VERSION ""

NS_ :

BS_:

BU_: VDCU_V CDCU VDR_TBOX ADCU VIU_B VIU_C VDCU_M EPB EPS_M EPS_S EBS FCS CMS_R CMS_B ECAS EGSM MTCU

BO_ 2566889511 NM_VDCU: 8 VDCU_V
 SG_ VDCU_SourceNodeID : 0|8@1+ (1,0) [0|255] "" Vector__XXX
 SG_ VDCU_ActiveWakeUpBit : 12|1@1+ (1,0) [0|1] "" Vector__XXX
 SG_ VDCU_RepeatMessageRequest : 8|1@1+ (1,0) [0|1] "" Vector__XXX
 SG_ VDCU_NMState_RMSfromBSM : 16|1@1+ (1,0) [0|1] "" Vector__XXX
 SG_ VDCU_NMState_RMSfromPBSM : 17|1@1+ (1,0) [0|1] "" Vector__XXX
 SG_ VDCU_NMState_RMSfromNOS : 18|1@1+ (1,0) [0|1] "" Vector__XXX
 SG_ VDCU_NMState_RMSfromRSS : 19|1@1+ (1,0) [0|1] "" Vector__XXX
 SG_ VDCU_NMState_NOSfromRMS : 20|1@1+ (1,0) [0|1] "" Vector__XXX
 SG_ VDCU_NMState_NOSfromRSS : 21|1@1+ (1,0) [0|1] "" Vector__XXX
 SG_ VDCU_WakeupSource : 24|8@1+ (1,0) [0|255] "" Vector__XXX
 SG_ VDCU_NMKpARson_NMPduReceived : 32|1@1+ (1,0) [0|1] "" Vector__XXX
 SG_ VDCU_NMKpARson_TimeOut : 33|1@1+ (1,0) [0|1] "" Vector__XXX
 SG_ VDCU_NMKpARson_Diag : 34|1@1+ (1,0) [0|1] "" Vector__XXX
 SG_ VDCU_NMKpARson_KL15 : 36|1@1+ (1,0) [0|1] "" Vector__XXX
 SG_ VDCU_NMKpARson_LINReq : 37|1@1+ (1,0) [0|1] "" Vector__XXX
 SG_ VDCU_NMKpARson_WinCtrl_L : 38|1@1+ (1,0) [0|1] "" Vector__XXX
 SG_ VDCU_NMKpARson_WinCtrl_R : 39|1@1+ (1,0) [0|1] "" Vector__XXX
 SG_ VDCU_NMKpARson_BrakePedalPressed : 40|1@1+ (1,0) [0|1] "" Vector__XXX
 SG_ VDCU_NMKpARson_LowBeamReq : 41|1@1+ (1,0) [0|1] "" Vector__XXX
 SG_ VDCU_NMKpARson_PosnLigjtReq : 42|1@1+ (1,0) [0|1] "" Vector__XXX
 SG_ VDCU_NMKpARson_DCChargeActive : 43|1@1+ (1,0) [0|1] "" Vector__XXX
 SG_ VDCU_NMKpARson_PowerOFFdelayMonitor : 44|1@1+ (1,0) [0|1] "" Vector__XXX
 SG_ VDCU_NMKpARson_ACChargeActive : 45|1@1+ (1,0) [0|1] "" Vector__XXX
 SG_ VDCU_NMKpARson_HVConnected : 46|1@1+ (1,0) [0|1] "" Vector__XXX
 SG_ VDCU_NMKpARson_ChargeWarmer : 47|1@1+ (1,0) [0|1] "" Vector__XXX
 SG_ VDCU_NMKpARson_Ready : 48|1@1+ (1,0) [0|1] "" Vector__XXX
 SG_ VDCU_NMKpARson_SmartCharge : 49|1@1+ (1,0) [0|1] "" Vector__XXX

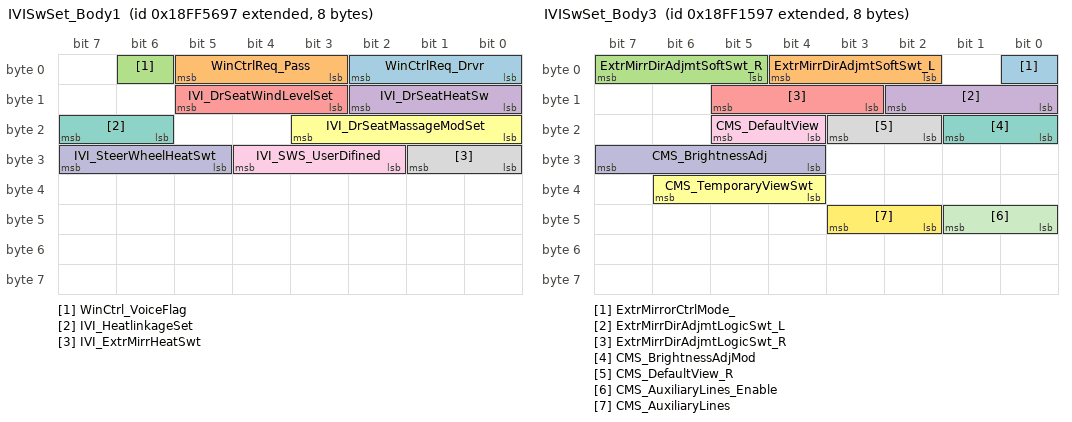
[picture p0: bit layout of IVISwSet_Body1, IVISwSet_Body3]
BO_ 2566870679 IVISwSet_Body1: 8 CDCU
 SG_ WinCtrlReq_Drvr : 0|3@1+ (1,0) [0|7] "" VDCU_V
 SG_ WinCtrlReq_Pass : 3|3@1+ (1,0) [0|7] "" VDCU_V
 SG_ WinCtrl_VoiceFlag : 6|1@1+ (1,0) [0|1] "" VDCU_V
 SG_ IVI_DrSeatHeatSw : 8|3@1+ (1,0) [0|7] "" VDCU_V
 SG_ IVI_DrSeatWindLevelSet : 11|3@1+ (1,0) [0|7] "" VDCU_V
 SG_ IVI_DrSeatMassageModSet : 16|4@1+ (1,0) [0|15] "" VDCU_V
 SG_ IVI_HeatlinkageSet : 22|2@1+ (1,0) [0|3] "" VDCU_V
 SG_ IVI_ExtrMirrHeatSwt : 24|2@1+ (1,0) [0|3] "" VDCU_V
 SG_ IVI_SWS_UserDifined : 26|3@1+ (1,0) [0|7] "" VDCU_V
 SG_ IVI_SteerWheelHeatSwt : 29|3@1+ (1,0) [0|7] "" VDCU_V

BO_ 2566900119 IVISwSet_Body2: 8 CDCU
 SG_ IVI_HornShiftSwitch : 0|2@1+ (1,0) [0|3] "" VDCU_V
 SG_ IVI_VehLockRemindSet : 2|2@1+ (1,0) [0|3] "" VDCU_V
 SG_ IVI_LampFollowMeHomeSet : 4|3@1+ (1,0) [0|7] "" VDCU_V
 SG_ IVI_LampAwayHomeSet : 8|3@1+ (1,0) [0|7] "" VDCU_V
 SG_ IVI_FindMyCarSet : 11|2@1+ (1,0) [0|3] "" VDCU_V
 SG_ IVI_SmartWelcomeSet : 13|2@1+ (1,0) [0|3] "" VDCU_V
 SG_ IVI_LogoLightSwitch : 16|2@1+ (1,0) [0|3] "" VDCU_V
 SG_ IVI_ADBSwitch : 18|2@1+ (1,0) [0|3] "" VDCU_V
 SG_ IVI_RainAutoCloseWinSet : 20|2@1+ (1,0) [0|3] "" VDCU_V
 SG_ IVI_LockAutoCloseWinSet : 22|2@1+ (1,0) [0|3] "" VDCU_V
 SG_ IVI_UnlockSet : 24|2@1+ (1,0) [0|3] "" VDCU_V
 SG_ IVI_SpeedAutoLockSet : 26|2@1+ (1,0) [0|3] "" VDCU_V
 SG_ IVI_StopAutoUnlockSet : 28|2@1+ (1,0) [0|3] "" VDCU_V
 SG_ IVI_ApproachAutoUnlockSet : 30|2@1+ (1,0) [0|3] "" VDCU_V
 SG_ IVI_AwayAutoLockSet : 32|2@1+ (1,0) [0|3] "" VDCU_V
 SG_ IVI_SpeedLimitSet_Sleeper : 34|2@1+ (1,0) [0|3] "" VDCU_V
 SG_ IVI_WCMEnableSwitch : 44|2@1+ (1,0) [0|3] "" VDCU_V
 SG_ IVI_BackLightBriSet : 48|4@1+ (1,0) [0|15] "" VDCU_V
 SG_ CeilingLightSet : 52|2@1+ (1,0) [0|3] "" VDCU_V
 SG_ IVI_VSPOpenSet : 56|2@1+ (1,0) [0|3] "" VDCU_V

BO_ 2566854039 IVISwSet_Body3: 8 CDCU
 SG_ ExtrMirrorCtrlMode_ : 0|1@1+ (1,0) [0|1] "" VDCU_V
 SG_ ExtrMirrDirAdjmtSoftSwt_L : 2|3@1+ (1,0) [0|7] "" VDCU_V
 SG_ ExtrMirrDirAdjmtSoftSwt_R : 5|3@1+ (1,0) [0|7] "" VDCU_V
 SG_ ExtrMirrDirAdjmtLogicSwt_L : 8|3@1+ (1,0) [0|7] "" VDCU_V
 SG_ ExtrMirrDirAdjmtLogicSwt_R : 11|3@1+ (1,0) [0|7] "" VDCU_V
 SG_ CMS_TemporaryViewSwt : 36|3@1+ (1,0) [0|7] "" VDCU_V
 SG_ CMS_BrightnessAdjMod : 16|2@1+ (1,0) [0|3] "" VDCU_V
 SG_ CMS_DefaultView_R : 18|2@1+ (1,0) [0|3] "" VDCU_V
 SG_ CMS_DefaultView : 20|2@1+ (1,0) [0|3] "" VDCU_V
 SG_ CMS_BrightnessAdj : 28|4@1+ (1,0) [0|15] "" VDCU_V
 SG_ CMS_AuxiliaryLines_Enable : 40|2@1+ (1,0) [0|3] "" VDCU_V
 SG_ CMS_AuxiliaryLines : 42|2@1+ (1,0) [0|3] "" VDCU_V

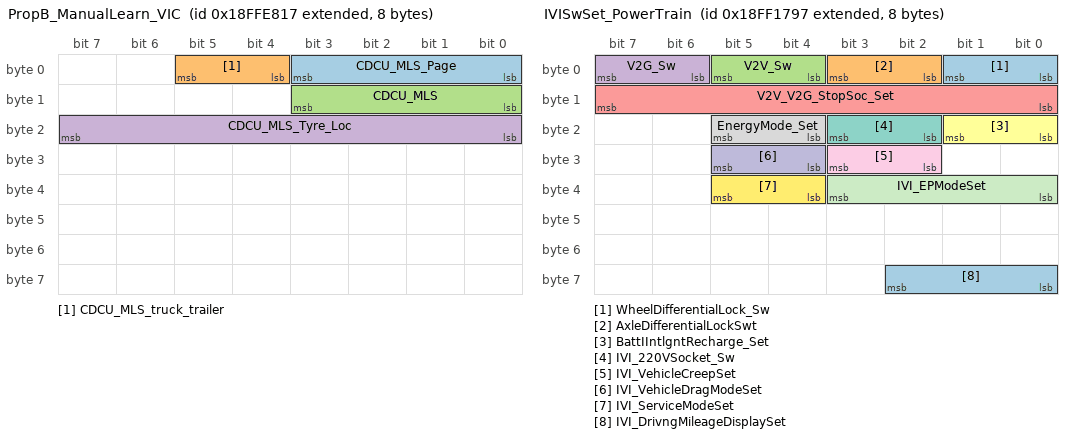
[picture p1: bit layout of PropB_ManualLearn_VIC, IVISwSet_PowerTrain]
BO_ 2566907927 PropB_ManualLearn_VIC: 8 CDCU
 SG_ CDCU_MLS_Page : 0|4@1+ (1,0) [0|15] "" VDCU_V
 SG_ CDCU_MLS_truck_trailer : 4|2@1+ (1,0) [0|3] "" VDCU_V
 SG_ CDCU_MLS : 8|4@1+ (1,0) [0|15] "" VDCU_V
 SG_ CDCU_MLS_Tyre_Loc : 16|8@1+ (1,0) [0|255] "" VDCU_V

BO_ 2566723351 IC_BDS: 8 CDCU
 SG_ DriverBeltlockStatus : 0|2@1+ (1,0) [0|3] "" VDCU_V
 SG_ PassengerBeltlockStatus : 2|2@1+ (1,0) [0|3] "" VDCU_V

BO_ 2566850171 DMS1: 8 CDCU
 SG_ DMS_SeatShakeSts : 32|3@1+ (1,0) [0|7] "" VDCU_V

BO_ 2563833751 Illumintion: 8 CDCU
 SG_ IlluminationBrightnessPercent : 0|8@1+ (0.4,0) [0|100] "%" VDCU_V

BO_ 2566905239 IVISwReq_TM1: 8 CDCU
 SG_ IVI_ACOffSwt : 0|2@1+ (1,0) [0|3] "" VDCU_V
 SG_ IVI_ACAutoSwt : 2|2@1+ (1,0) [0|3] "" VDCU_V
 SG_ IVI_ACModeMotorSwt : 4|3@1+ (1,0) [0|7] "" VDCU_V
 SG_ IVI_ACACSwt : 8|2@1+ (1,0) [0|3] "" VDCU_V
 SG_ IVI_ACPTCSwt : 10|2@1+ (1,0) [0|3] "" VDCU_V
 SG_ IVI_ACCycleMotorSwt : 12|2@1+ (1,0) [0|3] "" VDCU_V
 SG_ IVI_ACFrontDefrostSwt : 14|2@1+ (1,0) [0|3] "" VDCU_V
 SG_ IVI_ACTempPlusSwt : 16|1@1+ (1,0) [0|1] "" VDCU_V
 SG_ IVI_ACTempMinusSwt : 17|1@1+ (1,0) [0|1] "" VDCU_V
 SG_ IVI_ACTempLevelSwt : 18|6@1+ (1,0) [0|63] "" VDCU_V
 SG_ IVI_ACBlowerLvlSeltSwt : 24|4@1+ (1,0) [0|15] "" VDCU_V
 SG_ IVI_LonizerSwt : 28|2@1+ (1,0) [0|3] "" VDCU_V
 SG_ IVI_AirPurgeSwt : 30|2@1+ (1,0) [0|3] "" VDCU_V
 SG_ IVI_AcMaxSwt : 32|2@1+ (1,0) [0|3] "" VDCU_V
 SG_ IVI_HeatingMaxSwt : 34|2@1+ (1,0) [0|3] "" VDCU_V
 SG_ IVI_TempZoneSyncSwt : 36|2@1+ (1,0) [0|3] "" VDCU_V
 SG_ IVI_ACBlowerLvlSeltSwt_Slpr : 40|4@1+ (1,0) [0|15] "" VDCU_V
 SG_ IVI_ACTempPlusSwt_Slpr : 48|1@1+ (1,0) [0|1] "" VDCU_V
 SG_ IVI_ACTempMinusSwt_Slpr : 49|1@1+ (1,0) [0|1] "" VDCU_V
 SG_ IVI_ACTempLevelSwt_Slpr : 50|6@1+ (1,0) [0|63] "" VDCU_V
 SG_ IVI_ACBlowerPlusSwt_Slpr : 56|1@1+ (1,0) [0|1] "" VDCU_V
 SG_ IVI_ACBlowerMinusSwt_Slpr : 57|1@1+ (1,0) [0|1] "" VDCU_V
 SG_ IVI_ACBlowerLvlMinusSwt : 58|1@1+ (1,0) [0|1] "" VDCU_V
 SG_ IVI_ACOffSwt_Slpr : 59|2@1+ (1,0) [0|3] "" VDCU_V
 SG_ IVI_ACTimingRunSwt_Slpr : 61|2@1+ (1,0) [0|3] "" VDCU_V

BO_ 2566854551 IVISwSet_PowerTrain: 8 CDCU
 SG_ WheelDifferentialLock_Sw : 0|2@1+ (1,0) [0|3] "" VDCU_V
 SG_ AxleDifferentialLockSwt : 2|2@1+ (1,0) [0|3] "" VDCU_V
 SG_ V2V_Sw : 4|2@1+ (1,0) [0|3] "" VDCU_V
 SG_ V2G_Sw : 6|2@1+ (1,0) [0|3] "" VDCU_V
 SG_ V2V_V2G_StopSoc_Set : 8|8@1+ (1,0) [20|100] "%" VDCU_V
 SG_ BattIIntlgntRecharge_Set : 16|2@1+ (1,0) [0|3] "" VDCU_V
 SG_ IVI_220VSocket_Sw : 18|2@1+ (1,0) [0|3] "" VDCU_V
 SG_ EnergyMode_Set : 20|2@1+ (1,0) [0|3] "" VDCU_V
 SG_ IVI_VehicleCreepSet : 26|2@1+ (1,0) [0|3] "" VDCU_V
 SG_ IVI_VehicleDragModeSet : 28|2@1+ (1,0) [0|3] "" VDCU_V
 SG_ IVI_EPModeSet : 32|4@1+ (1,0) [0|15] "" VDCU_V
 SG_ IVI_ServiceModeSet : 36|2@1+ (1,0) [0|3] "" VDCU_V
 SG_ IVI_DrivngMileageDisplaySet : 56|3@1+ (1,0) [0|7] "" VDCU_V

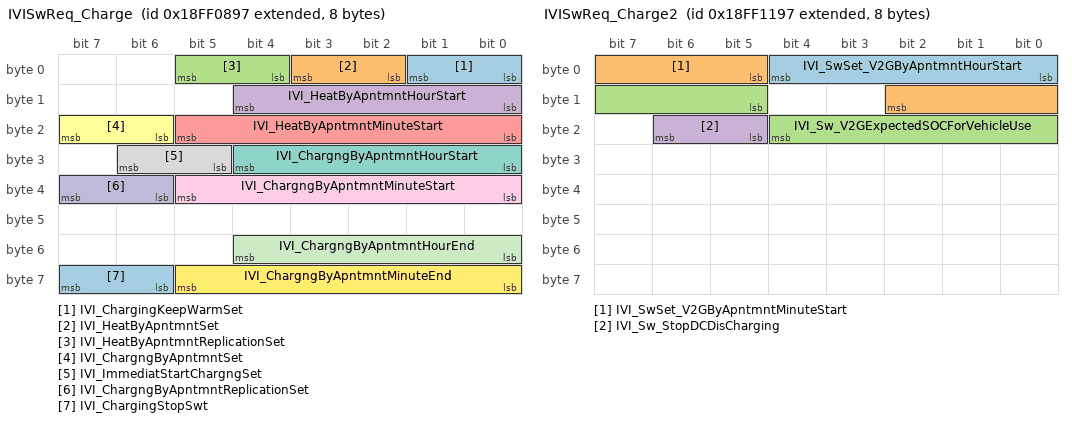
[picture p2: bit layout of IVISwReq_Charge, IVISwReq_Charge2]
BO_ 2566850711 IVISwReq_Charge: 8 CDCU
 SG_ IVI_ChargingKeepWarmSet : 0|2@1+ (1,0) [0|3] "" VDCU_V
 SG_ IVI_HeatByApntmntSet : 2|2@1+ (1,0) [0|3] "" VDCU_V
 SG_ IVI_HeatByApntmntReplicationSet : 4|2@1+ (1,0) [0|1] "" VDCU_V
 SG_ IVI_HeatByApntmntHourStart : 8|5@1+ (1,0) [0|31] "" VDCU_V
 SG_ IVI_HeatByApntmntMinuteStart : 16|6@1+ (1,0) [0|31] "" VDCU_V
 SG_ IVI_ChargngByApntmntSet : 22|2@1+ (1,0) [0|3] "" VDCU_V
 SG_ IVI_ChargngByApntmntHourStart : 24|5@1+ (1,0) [0|31] "h" VDCU_V
 SG_ IVI_ImmediatStartChargngSet : 29|2@1+ (1,0) [0|3] "" VDCU_V
 SG_ IVI_ChargngByApntmntMinuteStart : 32|6@1+ (1,0) [0|31] "min" VDCU_V
 SG_ IVI_ChargngByApntmntReplicationSet : 38|2@1+ (1,0) [0|1] "" VDCU_V
 SG_ IVI_ChargngByApntmntHourEnd : 48|5@1+ (1,0) [0|31] "h" VDCU_V
 SG_ IVI_ChargngByApntmntMinuteEnd : 56|6@1+ (1,0) [0|63] "min" VDCU_V
 SG_ IVI_ChargingStopSwt : 62|2@1+ (1,0) [0|3] "" VDCU_V

BO_ 2566853015 IVISwReq_Charge2: 8 CDCU
 SG_ IVI_SwSet_V2GByApntmntHourStart : 0|5@1+ (1,0) [0|31] "h" VDCU_V
 SG_ IVI_SwSet_V2GByApntmntMinuteStart : 5|6@1+ (1,0) [0|63] "min" VDCU_V
 SG_ IVI_Sw_V2GExpectedSOCForVehicleUse : 13|8@1+ (1,0) [0|100] "%" VDCU_V
 SG_ IVI_Sw_StopDCDisCharging : 21|2@1+ (1,0) [0|3] "" VDCU_V

BO_ 2566865177 TM_ACCtrl: 8 VDCU_V
 SG_ ACTempLevelDisp : 0|6@1+ (1,0) [0|63] "" CDCU,VDR_TBOX,ADCU
 SG_ ACPTCDisp : 6|2@1+ (1,0) [0|3] "" Vector__XXX
 SG_ ACTempLevelCtrl : 8|6@1+ (1,0) [0|63] "" VIU_B,ADCU
 SG_ ACModeMotorDisp : 16|3@1+ (1,0) [0|7] "" CDCU,VDR_TBOX,ADCU
 SG_ ACModeMotorCtrl : 19|3@1+ (1,0) [0|7] "" VIU_B,ADCU
 SG_ ACCycleMotorDisp : 22|2@1+ (1,0) [0|3] "" CDCU,VDR_TBOX,ADCU
 SG_ ACCycleMotorPosnCtrl : 24|2@1+ (1,0) [0|3] "" VIU_B,ADCU
 SG_ ACBlowerLevelDisp : 26|4@1+ (1,0) [0|15] "" CDCU,VDR_TBOX,ADCU
 SG_ ACBlowerLevelCtrl : 32|4@1+ (1,0) [0|15] "" VIU_B,ADCU
 SG_ ACFrontDefrostDisp : 36|2@1+ (1,0) [0|3] "" CDCU,VDR_TBOX,ADCU
 SG_ ACAcDisp : 38|2@1+ (1,0) [0|3] "" CDCU,VDR_TBOX,ADCU
 SG_ ACMaxDisp : 40|2@1+ (1,0) [0|3] "" CDCU,VDR_TBOX,ADCU
 SG_ ACAutoDisp : 42|2@1+ (1,0) [0|3] "" CDCU,VDR_TBOX,ADCU
 SG_ ACOffDisp : 44|2@1+ (1,0) [0|3] "" CDCU,VDR_TBOX,ADCU
 SG_ ACAirPurgeDisp : 46|2@1+ (1,0) [0|3] "" CDCU,VDR_TBOX,ADCU
 SG_ ACAirPurgeCtrl : 48|2@1+ (1,0) [0|3] "" VIU_B,ADCU
 SG_ ACLonizerDisp : 50|2@1+ (1,0) [0|3] "" CDCU,VDR_TBOX,ADCU
 SG_ ACLonizerCtrl : 52|2@1+ (1,0) [0|3] "" VIU_B,ADCU
 SG_ AC_TempZoneSyncSts : 54|2@1+ (1,0) [0|3] "" VIU_B,CDCU,VDR_TBOX,ADCU
 SG_ AC_HeatingMaxSts : 56|2@1+ (1,0) [0|3] "" VIU_B,CDCU,VDR_TBOX,ADCU
 SG_ ElecACTempLevelDisp : 58|5@1+ (1,0) [0|31] "" Vector__XXX

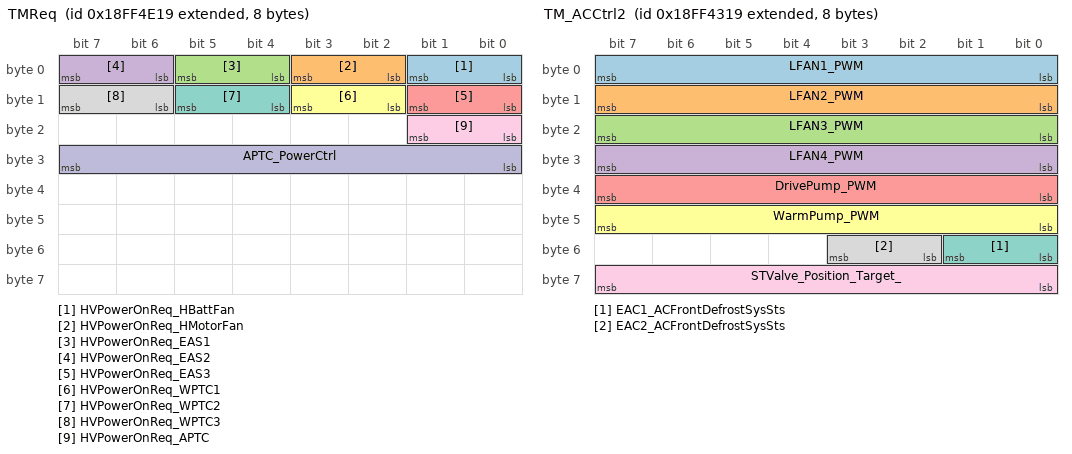
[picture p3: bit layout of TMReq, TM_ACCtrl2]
BO_ 2566868505 TMReq: 8 VDCU_V
 SG_ HVPowerOnReq_HBattFan : 0|2@1+ (1,0) [0|3] "" Vector__XXX
 SG_ HVPowerOnReq_HMotorFan : 2|2@1+ (1,0) [0|3] "" Vector__XXX
 SG_ HVPowerOnReq_EAS1 : 4|2@1+ (1,0) [0|3] "" Vector__XXX
 SG_ HVPowerOnReq_EAS2 : 6|2@1+ (1,0) [0|3] "" Vector__XXX
 SG_ HVPowerOnReq_EAS3 : 8|2@1+ (1,0) [0|3] "" Vector__XXX
 SG_ HVPowerOnReq_WPTC1 : 10|2@1+ (1,0) [0|3] "" Vector__XXX
 SG_ HVPowerOnReq_WPTC2 : 12|2@1+ (1,0) [0|3] "" Vector__XXX
 SG_ HVPowerOnReq_WPTC3 : 14|2@1+ (1,0) [0|3] "" Vector__XXX
 SG_ HVPowerOnReq_APTC : 16|2@1+ (1,0) [0|3] "" Vector__XXX
 SG_ APTC_PowerCtrl : 24|8@1+ (100,0) [0|4700] "W" VIU_B

BO_ 2566865433 TM_ACCtrl1: 8 VDCU_V
 SG_ ACTempLevelDispSlpr : 2|6@1+ (1,0) [0|63] "" CDCU
 SG_ ACTempLevelCtrl_Slpr : 10|6@1+ (1,0) [0|63] "" VIU_B
 SG_ ACBlowerLevelDisp_Slpr : 16|4@1+ (1,0) [0|15] "" CDCU
 SG_ ACBlowerLevelCtrl_Slpr : 20|4@1+ (1,0) [0|15] "" VIU_B
 SG_ ACTimingRunDisp_Slpr : 24|2@1+ (1,0) [0|3] "" CDCU
 SG_ ACOffDisp_Slpr : 26|2@1+ (1,0) [0|3] "" CDCU
 SG_ ESC_PTC_LowRelayCtrl : 28|2@1+ (1,0) [0|3] "" VIU_B
 SG_ FAN_LowRelayCtrl : 30|2@1+ (1,0) [0|3] "" VIU_C
 SG_ Blower_RelayCtrl : 32|2@1+ (1,0) [0|3] "" VIU_B
 SG_ Blower_RelayCtrl_Slpr : 34|2@1+ (1,0) [0|3] "" VIU_B
 SG_ BattPump_RelayCtrl : 36|2@1+ (1,0) [0|3] "" VIU_B
 SG_ WarmPump_RelayCtrl : 38|2@1+ (1,0) [0|3] "" VIU_B
 SG_ DrivePump_RelayCtrl : 40|2@1+ (1,0) [0|3] "" VIU_C
 SG_ SOVFront_Ctrl : 42|1@1+ (1,0) [0|1] "" VIU_B
 SG_ SOVRear_Ctrl : 43|1@1+ (1,0) [0|1] "" VIU_B
 SG_ Wasteheat_use_2way_SOV : 46|2@1+ (1,0) [0|3] "" VIU_C
 SG_ BattPump_PWM : 48|8@1+ (0.4,0) [0|100] "%" VIU_B,VIU_C
 SG_ Temp_Ambt_Accurate : 56|8@1+ (0.5,-40) [-40|87] "℃" Vector__XXX

BO_ 2566865689 TM_ACCtrl2: 8 VDCU_V
 SG_ LFAN1_PWM : 0|8@1+ (0.4,0) [0|100] "%" VIU_B,VIU_C
 SG_ LFAN2_PWM : 8|8@1+ (0.4,0) [0|100] "%" VIU_B,VIU_C
 SG_ LFAN3_PWM : 16|8@1+ (0.4,0) [0|100] "%" VIU_B,VIU_C
 SG_ LFAN4_PWM : 24|8@1+ (0.4,0) [0|100] "%" VIU_B,VIU_C
 SG_ DrivePump_PWM : 32|8@1+ (0.4,0) [0|100] "%" VIU_B,VIU_C
 SG_ WarmPump_PWM : 40|8@1+ (0.4,0) [0|100] "%" VIU_C
 SG_ EAC1_ACFrontDefrostSysSts : 48|2@1+ (1,0) [0|3] "" CDCU
 SG_ EAC2_ACFrontDefrostSysSts : 50|2@1+ (1,0) [0|3] "" CDCU
 SG_ STValve_Position_Target_ : 56|8@1+ (0.01953,0) [0|5] "v" VIU_C

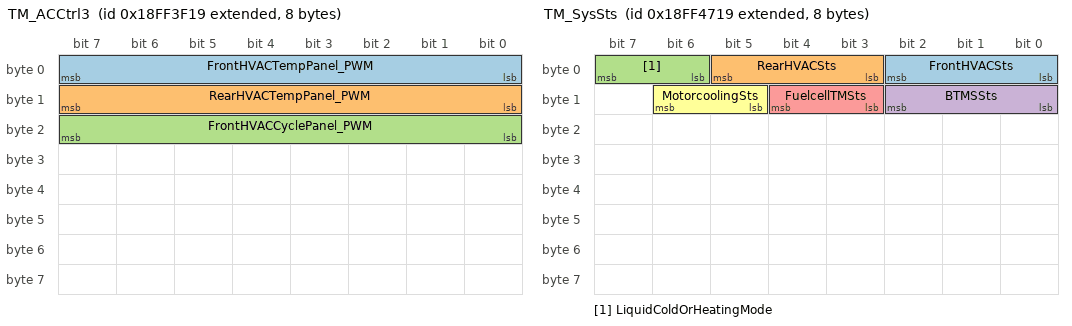
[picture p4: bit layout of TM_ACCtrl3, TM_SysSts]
BO_ 2566864665 TM_ACCtrl3: 8 VDCU_V
 SG_ FrontHVACTempPanel_PWM : 0|8@1+ (0.4,0) [0|100] "%" VIU_B
 SG_ RearHVACTempPanel_PWM : 8|8@1+ (0.4,0) [0|100] "%" VIU_B
 SG_ FrontHVACCyclePanel_PWM : 16|8@1+ (0.4,0) [0|100] "%" VIU_B

BO_ 2566866713 TM_SysSts: 8 VDCU_V
 SG_ FrontHVACSts : 0|3@1+ (1,0) [0|7] "" Vector__XXX
 SG_ RearHVACSts : 3|3@1+ (1,0) [0|6] "" Vector__XXX
 SG_ LiquidColdOrHeatingMode : 6|2@1+ (1,0) [0|3] "" Vector__XXX
 SG_ BTMSSts : 8|3@1+ (1,0) [0|7] "" Vector__XXX
 SG_ FuelcellTMSts : 11|2@1+ (1,0) [0|3] "" Vector__XXX
 SG_ MotorcoolingSts : 13|2@1+ (1,0) [0|3] "" Vector__XXX

BO_ 2566907722 EncryptData_TBox: 16 VDR_TBOX
 SG_ T_boxEncryptData_Byte1 : 0|8@1+ (1,0) [0|255] "" VDCU_V
 SG_ T_boxEncryptData_Byte2 : 8|8@1+ (1,0) [0|255] "" VDCU_V
 SG_ T_boxEncryptData_Byte3 : 16|8@1+ (1,0) [0|255] "" VDCU_V
 SG_ T_boxEncryptData_Byte4 : 24|8@1+ (1,0) [0|255] "" VDCU_V
 SG_ T_boxEncryptData_Byte5 : 32|8@1+ (1,0) [0|255] "" VDCU_V
 SG_ T_boxEncryptData_Byte6 : 40|8@1+ (1,0) [0|255] "" VDCU_V
 SG_ T_boxEncryptData_Byte7 : 48|8@1+ (1,0) [0|255] "" VDCU_V
 SG_ T_boxEncryptData_Byte8 : 56|8@1+ (1,0) [0|255] "" VDCU_V
 SG_ T_boxEncryptData_Byte9 : 64|8@1+ (1,0) [0|255] "" VDCU_V
 SG_ T_boxEncryptData_Byte10 : 72|8@1+ (1,0) [0|255] "" VDCU_V
 SG_ T_boxEncryptData_Byte11 : 80|8@1+ (1,0) [0|255] "" VDCU_V
 SG_ T_boxEncryptData_Byte12 : 88|8@1+ (1,0) [0|255] "" VDCU_V
 SG_ T_boxEncryptData_Byte13 : 96|8@1+ (1,0) [0|255] "" VDCU_V
 SG_ T_boxEncryptData_Byte14 : 104|8@1+ (1,0) [0|255] "" VDCU_V
 SG_ T_boxEncryptData_Byte15 : 112|8@1+ (1,0) [0|255] "" VDCU_V
 SG_ T_boxEncryptData_Byte16 : 120|8@1+ (1,0) [0|255] "" VDCU_V

BO_ 2566908234 VehicleID_TBox: 8 VDR_TBOX
 SG_ VehicleID_Tbox : 0|48@1+ (1,0) [0|2.81474976710655E14] "" VDCU_V

BO_ 2566908490 SecretKey_TBox: 16 VDR_TBOX
 SG_ SecretKey_Tbox_Byte1 : 0|8@1+ (1,0) [0|255] "" VDCU_V
 SG_ SecretKey_Tbox_Byte2 : 8|8@1+ (1,0) [0|255] "" VDCU_V
 SG_ SecretKey_Tbox_Byte3 : 16|8@1+ (1,0) [0|255] "" VDCU_V
 SG_ SecretKey_Tbox_Byte4 : 24|8@1+ (1,0) [0|255] "" VDCU_V
 SG_ SecretKey_Tbox_Byte5 : 32|8@1+ (1,0) [0|255] "" VDCU_V
 SG_ SecretKey_Tbox_Byte6 : 40|8@1+ (1,0) [0|255] "" VDCU_V
 SG_ SecretKey_Tbox_Byte7 : 48|8@1+ (1,0) [0|255] "" VDCU_V
 SG_ SecretKey_Tbox_Byte8 : 56|8@1+ (1,0) [0|255] "" VDCU_V
 SG_ SecretKey_Tbox_Byte9 : 64|8@1+ (1,0) [0|255] "" VDCU_V
 SG_ SecretKey_Tbox_Byte10 : 72|8@1+ (1,0) [0|255] "" VDCU_V
 SG_ SecretKey_Tbox_Byte11 : 80|8@1+ (1,0) [0|255] "" VDCU_V
 SG_ SecretKey_Tbox_Byte12 : 88|8@1+ (1,0) [0|255] "" VDCU_V
 SG_ SecretKey_Tbox_Byte13 : 96|8@1+ (1,0) [0|255] "" VDCU_V
 SG_ SecretKey_Tbox_Byte14 : 104|8@1+ (1,0) [0|255] "" VDCU_V
 SG_ SecretKey_Tbox_Byte15 : 112|8@1+ (1,0) [0|255] "" VDCU_V
 SG_ SecretKey_Tbox_Byte16 : 120|8@1+ (1,0) [0|255] "" VDCU_V

BO_ 2565537610 RQST_TBox: 3 VDR_TBOX
 SG_ Tbox_RQST_PGN : 0|24@1+ (1,0) [0|1.6777215E7] "" VDCU_V

BO_ 2566907210 TBox_Request: 16 VDR_TBOX
 SG_ ControlIdentifier : 0|8@1+ (1,0) [0|255] "" VDCU_V
 SG_ AwakeNetwork : 8|2@1+ (1,0) [0|3] "" VDCU_V
 SG_ TBOX_ACTempLevelReq_TM1 : 16|6@1+ (1,0) [0|63] "" VDCU_V
 SG_ TBOX_ACFrontDefrostReq_TM1 : 22|2@1+ (1,0) [0|3] "" VDCU_V
 SG_ TBOX_Cockpit_Cleaning_TM1 : 24|2@1+ (1,0) [0|3] "" VDCU_V
 SG_ TBOX_AcMaxSwt : 32|2@1+ (1,0) [0|3] "" VDCU_V
 SG_ TBOX_HeatingMaxSwt : 34|2@1+ (1,0) [0|3] "" VDCU_V
 SG_ TBOX_DrSeatHeatSw : 40|3@1+ (1,0) [0|7] "" VDCU_V
 SG_ TBOX_SteerWheelHeatSwt : 43|3@1+ (1,0) [0|7] "" VDCU_V
 SG_ TBOX_ChargngByApntmntHourStartFb : 48|5@1+ (1,0) [0|31] "h" VDCU_V
 SG_ TBOX_ChargngByApntmntMinuteStartFb : 53|6@1+ (1,0) [0|63] "min" VDCU_V
 SG_ TBOX_DCChargingByApntmnReplication_St : 60|2@1+ (1,0) [0|3] "" VDCU_V
 SG_ TBOX_ChargngByApntmntHourEndFb : 64|5@1+ (1,0) [0|31] "h" VDCU_V
 SG_ TBOX_ChargngByApntmntMinuteEndFb : 72|6@1+ (1,0) [0|63] "min" VDCU_V

BO_ 2566909258 TBOXReq_TM1: 8 VDR_TBOX
 SG_ TBOX_RemoteReqFlag : 63|1@1+ (1,0) [0|1] "" VDCU_V

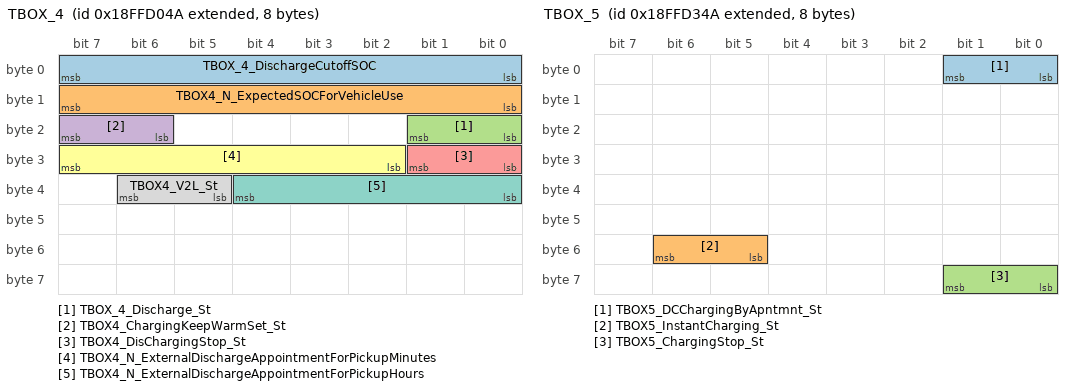
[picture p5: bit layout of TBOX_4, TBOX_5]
BO_ 2566901834 TBOX_4: 8 VDR_TBOX
 SG_ TBOX_4_DischargeCutoffSOC : 0|8@1+ (1,0) [0|100] "%" VDCU_V
 SG_ TBOX4_N_ExpectedSOCForVehicleUse : 8|8@1+ (1,0) [0|100] "%" VDCU_V
 SG_ TBOX_4_Discharge_St : 16|2@1+ (1,0) [0|3] "" VDCU_V
 SG_ TBOX4_ChargingKeepWarmSet_St : 22|2@1+ (1,0) [0|3] "" VDCU_V
 SG_ TBOX4_DisChargingStop_St : 24|2@1+ (1,0) [0|3] "" VDCU_V
 SG_ TBOX4_N_ExternalDischargeAppointmentForPickupMinutes : 26|6@1+ (1,0) [0|63] "" VDCU_V
 SG_ TBOX4_N_ExternalDischargeAppointmentForPickupHours : 32|5@1+ (1,0) [0|31] "" VDCU_V
 SG_ TBOX4_V2L_St : 37|2@1+ (1,0) [0|3] "" VDCU_V

BO_ 2566902602 TBOX_5: 8 VDR_TBOX
 SG_ TBOX5_DCChargingByApntmnt_St : 0|2@1+ (1,0) [0|3] "" VDCU_V
 SG_ TBOX5_InstantCharging_St : 53|2@1+ (1,0) [0|3] "" VDCU_V
 SG_ TBOX5_ChargingStop_St : 56|2@1+ (1,0) [0|3] "" VDCU_V

BO_ 2566907431 RandomData_VDCU: 8 VDCU_V
 SG_ VDCU_RandomData : 0|24@1+ (1,0) [0|1.6777215E7] "" VDR_TBOX

BO_ 2566908199 VehicleID_VDCU: 8 VDCU_V
 SG_ VehicleID_VDCU : 0|48@1+ (1,0) [0|2.81474976710655E14] "" VDR_TBOX

BO_ 2566908455 SecretKey_VDCU: 16 VDCU_V
 SG_ SecretKey_VDCU_Byte1 : 0|8@1+ (1,0) [0|255] "" VDR_TBOX
 SG_ SecretKey_VDCU_Byte2 : 8|8@1+ (1,0) [0|255] "" VDR_TBOX
 SG_ SecretKey_VDCU_Byte3 : 16|8@1+ (1,0) [0|255] "" VDR_TBOX
 SG_ SecretKey_VDCU_Byte4 : 24|8@1+ (1,0) [0|255] "" VDR_TBOX
 SG_ SecretKey_VDCU_Byte5 : 32|8@1+ (1,0) [0|255] "" VDR_TBOX
 SG_ SecretKey_VDCU_Byte6 : 40|8@1+ (1,0) [0|255] "" VDR_TBOX
 SG_ SecretKey_VDCU_Byte7 : 48|8@1+ (1,0) [0|255] "" VDR_TBOX
 SG_ SecretKey_VDCU_Byte8 : 56|8@1+ (1,0) [0|255] "" VDR_TBOX
 SG_ SecretKey_VDCU_Byte9 : 64|8@1+ (1,0) [0|255] "" VDR_TBOX
 SG_ SecretKey_VDCU_Byte10 : 72|8@1+ (1,0) [0|255] "" VDR_TBOX
 SG_ SecretKey_VDCU_Byte11 : 80|8@1+ (1,0) [0|255] "" VDR_TBOX
 SG_ SecretKey_VDCU_Byte12 : 88|8@1+ (1,0) [0|255] "" VDR_TBOX
 SG_ SecretKey_VDCU_Byte13 : 96|8@1+ (1,0) [0|255] "" VDR_TBOX
 SG_ SecretKey_VDCU_Byte14 : 104|8@1+ (1,0) [0|255] "" VDR_TBOX
 SG_ SecretKey_VDCU_Byte15 : 112|8@1+ (1,0) [0|255] "" VDR_TBOX
 SG_ SecretKey_VDCU_Byte16 : 120|8@1+ (1,0) [0|255] "" VDR_TBOX

BO_ 2565537575 RQST_VDCU: 3 VDCU_V
 SG_ VDCU_RQST_PGN : 0|24@1+ (1,0) [0|1.6777215E7] "" VDR_TBOX

BO_ 2566907943 VDCU_Response: 8 VDCU_V
 SG_ VDCU_St_AuthenticationResultResponse : 50|2@1+ (1,0) [0|3] "" VDR_TBOX
 SG_ ValidDKM : 40|1@1+ (1,0) [0|1] "" VDCU_M

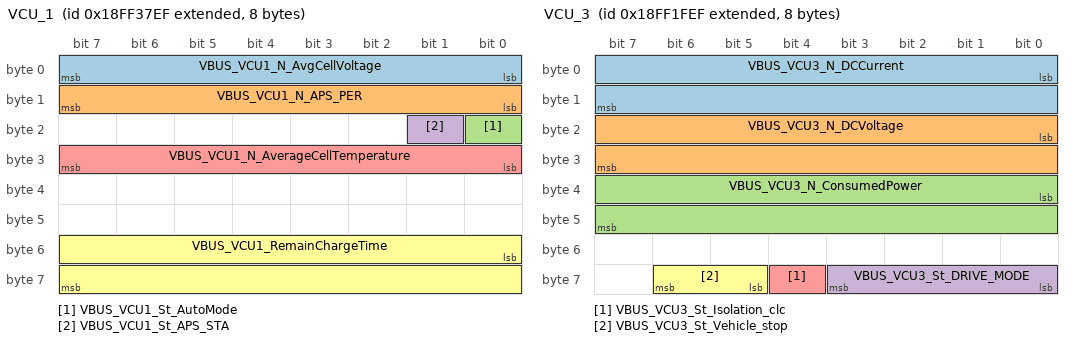
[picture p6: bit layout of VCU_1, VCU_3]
BO_ 2566862831 VCU_1: 8 VDCU_V
 SG_ VBUS_VCU1_N_AvgCellVoltage : 0|8@1+ (0.02,0) [0|5] "V" CDCU,VDR_TBOX,ADCU
 SG_ VBUS_VCU1_N_APS_PER : 8|8@1+ (0.4,0) [0|100] "%" CDCU,VDR_TBOX,ADCU
 SG_ VBUS_VCU1_St_AutoMode : 16|1@1+ (1,0) [0|1] "" CDCU,VDR_TBOX,ADCU
 SG_ VBUS_VCU1_St_APS_STA : 17|1@1+ (1,0) [0|1] "" CDCU,VDR_TBOX,ADCU
 SG_ VBUS_VCU1_N_AverageCellTemperature : 24|8@1+ (1,-40) [-40|125] "℃" CDCU,VDR_TBOX,ADCU
 SG_ VBUS_VCU1_RemainChargeTime : 48|16@1+ (1,0) [0|65535] "min" CDCU,VDR_TBOX,ADCU

BO_ 2566858479 VCU_6: 8 VDCU_V
 SG_ VBUS_VCU6_F_BpSynFlt_Fault : 58|1@1+ (1,0) [0|1] "" CDCU

BO_ 2566856687 VCU_3: 8 VDCU_V
 SG_ VBUS_VCU3_N_DCCurrent : 0|16@1+ (0.1,-1000) [-1000|1000] "A" CDCU,ADCU
 SG_ VBUS_VCU3_N_DCVoltage : 16|16@1+ (0.1,0) [0|1000] "V" CDCU,ADCU
 SG_ VBUS_VCU3_N_ConsumedPower : 32|16@1+ (1,-1000) [-1000|1000] "kW" CDCU,ADCU
 SG_ VBUS_VCU3_St_DRIVE_MODE : 56|4@1+ (1,0) [0|15] "" CDCU,ADCU
 SG_ VBUS_VCU3_St_Isolation_clc : 60|1@1+ (1,0) [0|1] "" CDCU,ADCU
 SG_ VBUS_VCU3_St_Vehicle_stop : 61|2@1+ (1,0) [0|3] "" CDCU,ADCU

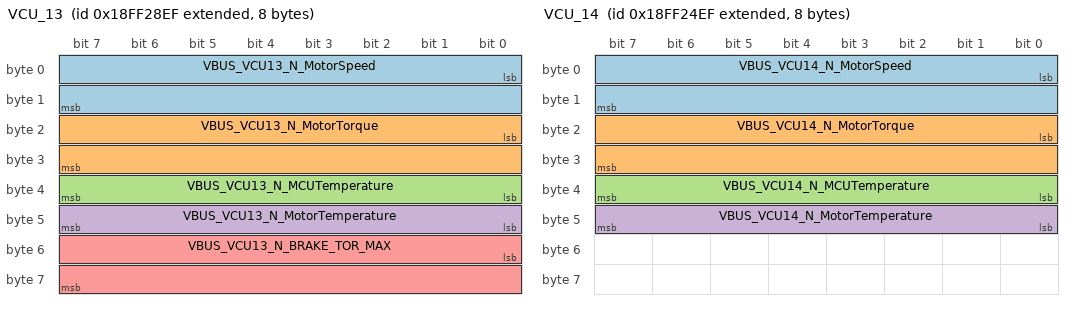
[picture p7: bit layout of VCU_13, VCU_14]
BO_ 2566858991 VCU_13: 8 VDCU_V
 SG_ VBUS_VCU13_N_MotorSpeed : 0|16@1+ (1,-10000) [-10000|10000] "rpm" CDCU,VDR_TBOX,ADCU,EPB,EPS_M,EPS_S
 SG_ VBUS_VCU13_N_MotorTorque : 16|16@1+ (1,-5000) [-5000|60535] "N?m" CDCU,VDR_TBOX,ADCU,EPB,EPS_M,EPS_S
 SG_ VBUS_VCU13_N_MCUTemperature : 32|8@1+ (1,-40) [-40|215] "°C" CDCU,VDR_TBOX,ADCU,EPS_M,EPS_S
 SG_ VBUS_VCU13_N_MotorTemperature : 40|8@1+ (1,-40) [-40|215] "°C" CDCU,VDR_TBOX,ADCU,EPS_M,EPS_S
 SG_ VBUS_VCU13_N_BRAKE_TOR_MAX : 48|16@1+ (1,-3000) [-3000|3000] "N?m" CDCU,VDR_TBOX,ADCU,EPS_M,EPS_S

BO_ 2566857967 VCU_14: 8 VDCU_V
 SG_ VBUS_VCU14_N_MotorSpeed : 0|16@1+ (1,-10000) [-10000|30000] "rpm" CDCU,ADCU,EPB,EPS_M,EPS_S
 SG_ VBUS_VCU14_N_MotorTorque : 16|16@1+ (1,-5000) [-5000|60535] "N?m" CDCU,ADCU,EPB,EPS_M,EPS_S
 SG_ VBUS_VCU14_N_MCUTemperature : 32|8@1+ (1,-40) [-40|215] "°C" CDCU,ADCU,EPS_M,EPS_S
 SG_ VBUS_VCU14_N_MotorTemperature : 40|8@1+ (1,-40) [-40|215] "°C" CDCU,ADCU,EPS_M,EPS_S

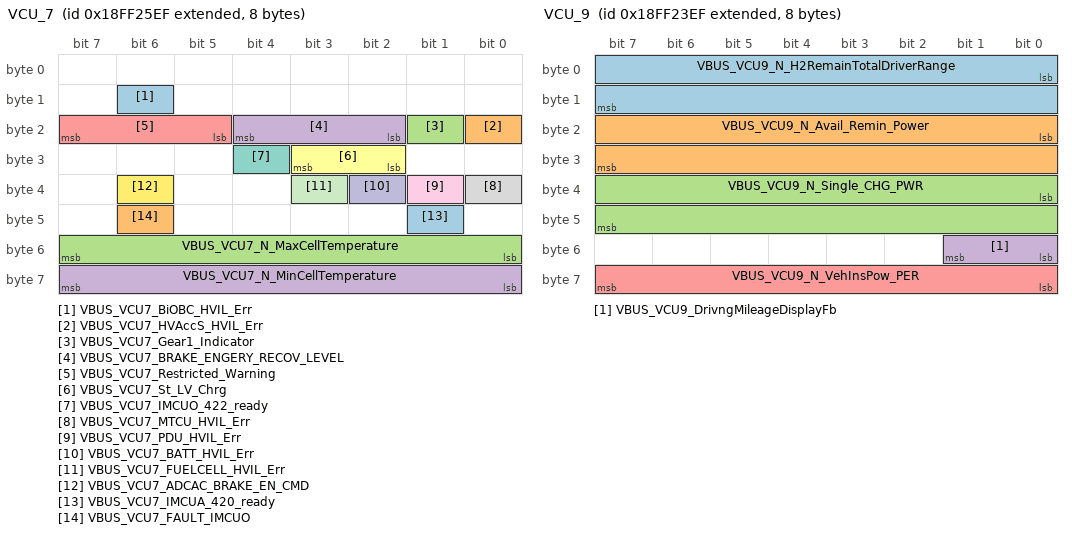
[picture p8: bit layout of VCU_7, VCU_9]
BO_ 2566858223 VCU_7: 8 VDCU_V
 SG_ VBUS_VCU7_BiOBC_HVIL_Err : 14|1@1+ (1,0) [0|1] "" CDCU,VDR_TBOX,ADCU
 SG_ VBUS_VCU7_HVAccS_HVIL_Err : 16|1@1+ (1,0) [0|1] "" ADCU
 SG_ VBUS_VCU7_Gear1_Indicator : 17|1@1+ (1,0) [0|1] "" CDCU,ADCU
 SG_ VBUS_VCU7_BRAKE_ENGERY_RECOV_LEVEL : 18|3@1+ (1,0) [0|7] "" CDCU,VDR_TBOX,ADCU
 SG_ VBUS_VCU7_Restricted_Warning : 21|3@1+ (1,0) [0|7] "" CDCU,VDR_TBOX,ADCU
 SG_ VBUS_VCU7_St_LV_Chrg : 26|2@1+ (1,0) [0|3] "" CDCU,VDR_TBOX,ADCU
 SG_ VBUS_VCU7_IMCUO_422_ready : 28|1@1+ (1,0) [0|1] "" CDCU,VDR_TBOX,ADCU
 SG_ VBUS_VCU7_MTCU_HVIL_Err : 32|1@1+ (1,0) [0|1] "" CDCU,VDR_TBOX,ADCU
 SG_ VBUS_VCU7_PDU_HVIL_Err : 33|1@1+ (1,0) [0|1] "" CDCU,VDR_TBOX,ADCU
 SG_ VBUS_VCU7_BATT_HVIL_Err : 34|1@1+ (1,0) [0|1] "" CDCU,VDR_TBOX,ADCU
 SG_ VBUS_VCU7_FUELCELL_HVIL_Err : 35|1@1+ (1,0) [0|1] "" CDCU,VDR_TBOX,ADCU
 SG_ VBUS_VCU7_ADCAC_BRAKE_EN_CMD : 38|1@1+ (1,0) [0|1] "" CDCU,VDR_TBOX,ADCU
 SG_ VBUS_VCU7_IMCUA_420_ready : 41|1@1+ (1,0) [0|1] "" VIU_C,CDCU,VDR_TBOX,ADCU
 SG_ VBUS_VCU7_FAULT_IMCUO : 46|1@1+ (1,0) [0|1] "" CDCU,VDR_TBOX,ADCU
 SG_ VBUS_VCU7_N_MaxCellTemperature : 48|8@1+ (1,-40) [-40|125] "℃" CDCU,VDR_TBOX,ADCU
 SG_ VBUS_VCU7_N_MinCellTemperature : 56|8@1+ (1,-40) [-40|125] "℃" CDCU,VDR_TBOX,ADCU

BO_ 2566857711 VCU_9: 8 VDCU_V
 SG_ VBUS_VCU9_N_H2RemainTotalDriverRange : 0|16@1+ (1,0) [0|65535] "km" CDCU,ADCU
 SG_ VBUS_VCU9_N_Avail_Remin_Power : 16|16@1+ (1,-1000) [-1000|1000] "kW" CDCU,ADCU
 SG_ VBUS_VCU9_N_Single_CHG_PWR : 32|16@1+ (0.1,0) [0|6553.5] "kW·h" CDCU,ADCU
 SG_ VBUS_VCU9_DrivngMileageDisplayFb : 48|2@1+ (1,0) [0|3] "" CDCU,ADCU
 SG_ VBUS_VCU9_N_VehInsPow_PER : 56|8@1+ (1,-100) [-100|100] "%" Vector__XXX

BO_ 2566853871 VCU_12: 8 VDCU_V
 SG_ VBUS_VCU12_ICS_Fault_Flg : 61|2@1+ (1,0) [0|3] "" CDCU,VDR_TBOX,ADCU
 SG_ VBUS_VCU12_HVConnect_Sta : 63|1@1+ (1,0) [0|1] "" CDCU

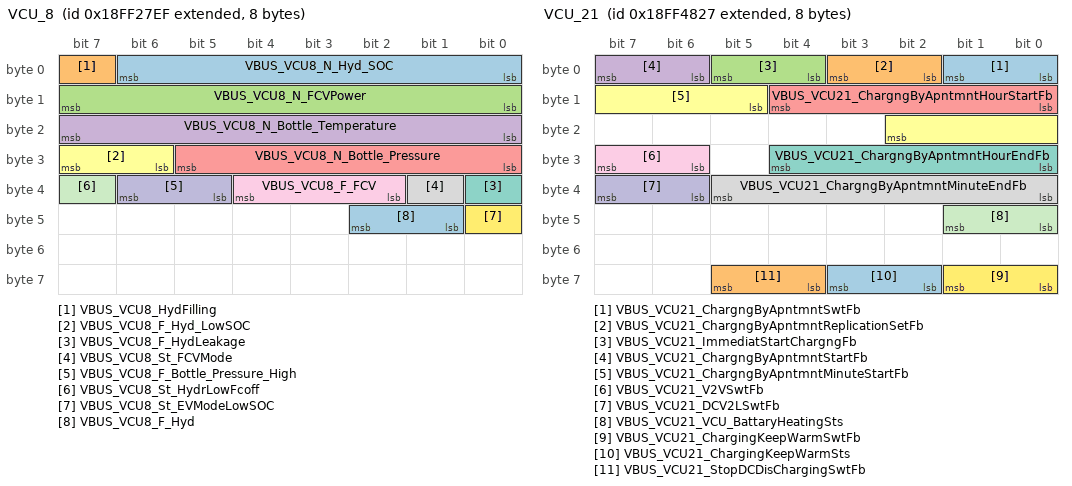
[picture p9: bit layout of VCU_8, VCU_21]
BO_ 2566858735 VCU_8: 8 VDCU_V
 SG_ VBUS_VCU8_N_Hyd_SOC : 0|7@1+ (1,0) [0|100] "%" CDCU,VDR_TBOX,ADCU
 SG_ VBUS_VCU8_HydFilling : 7|1@1+ (1,0) [0|1] "" CDCU,VDR_TBOX,ADCU
 SG_ VBUS_VCU8_N_FCVPower : 8|8@1+ (1,0) [0|255] "kw" CDCU,VDR_TBOX,ADCU
 SG_ VBUS_VCU8_N_Bottle_Temperature : 16|8@1+ (1,-40) [-40|210] "℃" CDCU,VDR_TBOX,ADCU
 SG_ VBUS_VCU8_N_Bottle_Pressure : 24|6@1+ (1,0) [0|50] "MPa" CDCU,VDR_TBOX,ADCU
 SG_ VBUS_VCU8_F_Hyd_LowSOC : 30|2@1+ (1,0) [0|2] "" CDCU,VDR_TBOX,ADCU
 SG_ VBUS_VCU8_F_HydLeakage : 32|1@1+ (1,0) [0|1] "" CDCU,VDR_TBOX,ADCU
 SG_ VBUS_VCU8_St_FCVMode : 33|1@1+ (1,0) [0|1] "" CDCU,VDR_TBOX,ADCU
 SG_ VBUS_VCU8_F_FCV : 34|3@1+ (1,0) [0|4] "" CDCU,VDR_TBOX,ADCU
 SG_ VBUS_VCU8_F_Bottle_Pressure_High : 37|2@1+ (1,0) [0|3] "" CDCU,VDR_TBOX,ADCU
 SG_ VBUS_VCU8_St_HydrLowFcoff : 39|1@1+ (1,0) [0|1] "" CDCU,VDR_TBOX,ADCU
 SG_ VBUS_VCU8_St_EVModeLowSOC : 40|1@1+ (1,0) [0|1] "" CDCU,VDR_TBOX,ADCU
 SG_ VBUS_VCU8_F_Hyd : 41|2@1+ (1,0) [0|3] "" CDCU,VDR_TBOX,ADCU

BO_ 2566866215 VCU_20: 8 VDCU_V
 SG_ VBUS_VCU20_V2GSwtFb : 0|2@1+ (1,0) [0|3] "" CDCU
 SG_ VBUS_VCU20_PowerOutSts_220V : 2|2@1+ (1,0) [0|3] "" Vector__XXX
 SG_ VBUS_VCU20_PowerSwtFb_220V : 4|2@1+ (1,0) [0|3] "" CDCU
 SG_ VBUS_VCU20_AutoBatteryRechargeSwtFb : 6|2@1+ (1,0) [0|3] "" CDCU
 SG_ VBUS_VCU20_DiffLockStateRearAxle1 : 8|2@1+ (1,0) [0|3] "" CDCU
 SG_ VBUS_VCU20_DiffLockStateRearAxle2 : 10|2@1+ (1,0) [0|3] "" CDCU
 SG_ VBUS_VCU20_DiffLockSwtFb : 12|2@1+ (1,0) [0|3] "" CDCU
 SG_ VBUS_VCU20_SPSM_St : 14|2@1+ (1,0) [0|3] "" CDCU
 SG_ VBUS_VCU20_VehicleCreepSetFb : 16|2@1+ (1,0) [0|3] "" CDCU
 SG_ VBUS_VCU20_GSMFltSts : 18|2@1+ (1,0) [0|3] "" CDCU
 SG_ VBUS_VCU20_DragModelSwtFb : 24|2@1+ (1,0) [0|3] "" CDCU
 SG_ VBUS_VCU20_SPSM_SwtFb : 26|2@1+ (1,0) [0|3] "" CDCU
 SG_ VBUS_VCU20_Swt_EV_FCV : 28|2@1+ (1,0) [0|3] "" CDCU
 SG_ VBUS_VCU20_DriveAnti_theftSts : 30|2@1+ (1,0) [0|3] "" CDCU,VDR_TBOX
 SG_ VBUS_VCU20_StopChargingSwtFb : 32|2@1+ (1,0) [0|3] "" CDCU,VDR_TBOX
 SG_ VBUS_VCU20_V2GByApntmntMinuteStart : 34|6@1+ (1,0) [0|63] "" CDCU
 SG_ VBUS_VCU20_V2GDischargeCutoffSOC : 40|8@1+ (1,0) [0|100] "%" CDCU
 SG_ VBUS_VCU20_V2GExpectedSOCForVehicleUse : 48|8@1+ (1,0) [0|100] "%" CDCU
 SG_ VBUS_VCU20_V2GByApntmntHourStart : 56|5@1+ (1,0) [0|31] "" CDCU
 SG_ VBUS_VCU20_DrvMod_ECO : 61|1@1+ (1,0) [0|1] "" CDCU
 SG_ VBUS_VCU20_EMotor_OverSpeed : 62|2@1+ (1,0) [0|3] "" CDCU

BO_ 2566866983 VCU_21: 8 VDCU_V
 SG_ VBUS_VCU21_ChargngByApntmntSwtFb : 0|2@1+ (1,0) [0|3] "" CDCU,VDR_TBOX
 SG_ VBUS_VCU21_ChargngByApntmntReplicationSetFb : 2|2@1+ (1,0) [0|3] "" CDCU,VDR_TBOX
 SG_ VBUS_VCU21_ImmediatStartChargngFb : 4|2@1+ (1,0) [0|3] "" CDCU,VDR_TBOX
 SG_ VBUS_VCU21_ChargngByApntmntStartFb : 6|2@1+ (1,0) [0|3] "" CDCU,VDR_TBOX
 SG_ VBUS_VCU21_ChargngByApntmntHourStartFb : 8|5@1+ (1,0) [0|31] "h" CDCU,VDR_TBOX
 SG_ VBUS_VCU21_ChargngByApntmntMinuteStartFb : 13|6@1+ (1,0) [0|63] "min" CDCU,VDR_TBOX
 SG_ VBUS_VCU21_ChargngByApntmntHourEndFb : 24|5@1+ (1,0) [0|31] "h" CDCU,VDR_TBOX
 SG_ VBUS_VCU21_ChargngByApntmntMinuteEndFb : 32|6@1+ (1,0) [0|63] "min" CDCU,VDR_TBOX
 SG_ VBUS_VCU21_V2VSwtFb : 30|2@1+ (1,0) [0|3] "" CDCU
 SG_ VBUS_VCU21_DCV2LSwtFb : 38|2@1+ (1,0) [0|3] "" CDCU
 SG_ VBUS_VCU21_VCU_BattaryHeatingSts : 40|2@1+ (1,0) [0|3] "" CDCU,VDR_TBOX
 SG_ VBUS_VCU21_ChargingKeepWarmSwtFb : 56|2@1+ (1,0) [0|3] "" CDCU,VDR_TBOX
 SG_ VBUS_VCU21_ChargingKeepWarmSts : 58|2@1+ (1,0) [0|3] "" CDCU,VDR_TBOX
 SG_ VBUS_VCU21_StopDCDisChargingSwtFb : 60|2@1+ (1,0) [0|3] "" CDCU,VDR_TBOX

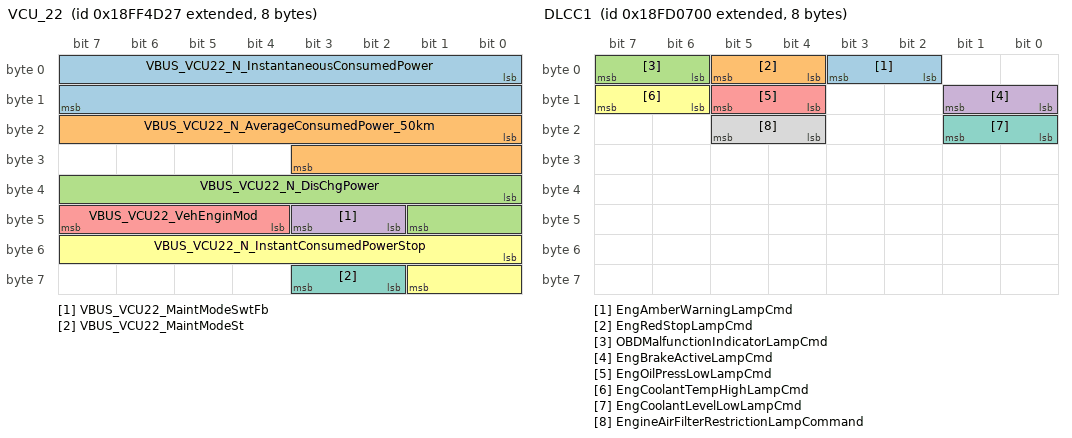
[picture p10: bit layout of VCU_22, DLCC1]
BO_ 2566868263 VCU_22: 8 VDCU_V
 SG_ VBUS_VCU22_N_InstantaneousConsumedPower : 0|16@1+ (0.1,-3000) [-3000|3553.5] "kW·h/100km" CDCU
 SG_ VBUS_VCU22_N_AverageConsumedPower_50km : 16|12@1+ (0.1,0) [0|6553.5] "kW·h/100km" CDCU
 SG_ VBUS_VCU22_N_DisChgPower : 32|10@1+ (0.1,0) [0|1000] "kW" Vector__XXX
 SG_ VBUS_VCU22_MaintModeSwtFb : 42|2@1+ (1,0) [0|3] "" CDCU
 SG_ VBUS_VCU22_VehEnginMod : 44|4@1+ (1,0) [0|15] "" CDCU
 SG_ VBUS_VCU22_N_InstantConsumedPowerStop : 48|10@1+ (0.1,0) [0|100] "kW" CDCU
 SG_ VBUS_VCU22_MaintModeSt : 58|2@1+ (1,0) [0|3] "" CDCU

BO_ 2566870288 PROPB_IT3_TX: 8 VDCU_V
 SG_ IntarderPilotLampState : 0|2@1+ (1,0) [0|3] "" CDCU

BO_ 2566708224 CCVS3: 8 VDCU_V
 SG_ ACCReadinessStatus : 0|2@1+ (1,0) [0|3] "" ADCU,EPB,EBS,EPS_M,EPS_S
 SG_ AEBSReadinessState : 24|2@1+ (1,0) [0|3] "" ADCU,EPB,EBS,EPS_M,EPS_S

BO_ 2566719232 DLCC1: 8 VDCU_V
 SG_ EngAmberWarningLampCmd : 2|2@1+ (1,0) [0|3] "" CDCU,ADCU,EPB,EBS,EPS_M,EPS_S
 SG_ EngRedStopLampCmd : 4|2@1+ (1,0) [0|3] "" CDCU,ADCU,EPB,EBS,EPS_M,EPS_S
 SG_ OBDMalfunctionIndicatorLampCmd : 6|2@1+ (1,0) [0|3] "" CDCU,ADCU,EPB,EBS,EPS_M,EPS_S
 SG_ EngBrakeActiveLampCmd : 8|2@1+ (1,0) [0|3] "" CDCU,ADCU,EPB,EBS,EPS_M,EPS_S
 SG_ EngOilPressLowLampCmd : 12|2@1+ (1,0) [0|3] "" CDCU,ADCU,EPB,EBS,EPS_M,EPS_S
 SG_ EngCoolantTempHighLampCmd : 14|2@1+ (1,0) [0|3] "" CDCU,ADCU,EPB,EBS,EPS_M,EPS_S
 SG_ EngCoolantLevelLowLampCmd : 16|2@1+ (1,0) [0|3] "" CDCU,ADCU,EPB,EBS,EPS_M,EPS_S
 SG_ EngineAirFilterRestrictionLampCommand : 20|2@1+ (1,0) [0|3] "" CDCU,ADCU,EPB,EBS,EPS_M,EPS_S

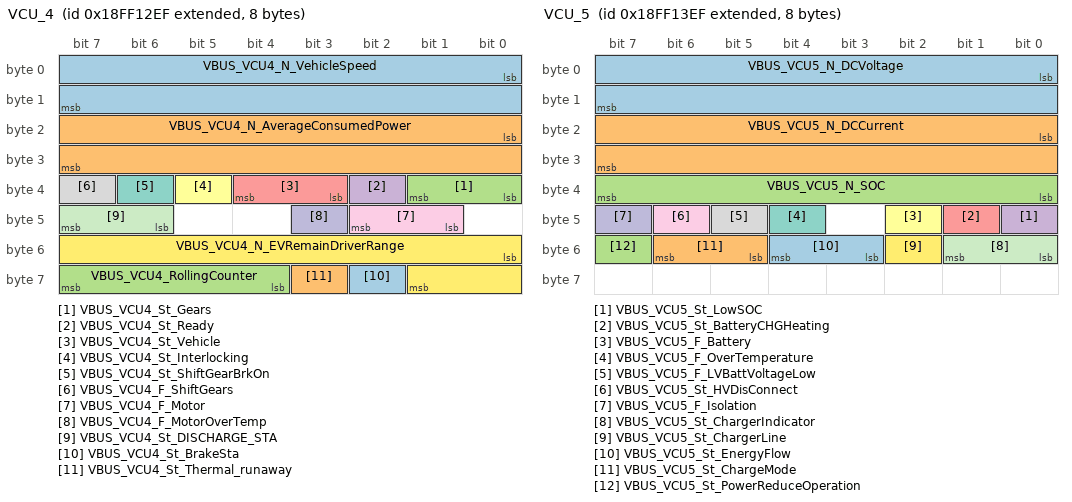
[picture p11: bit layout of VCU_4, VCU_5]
BO_ 2566853359 VCU_4: 8 VDCU_V
 SG_ VBUS_VCU4_N_VehicleSpeed : 0|16@1+ (0.0039,0) [0|250.996] "km/h" CDCU,VDR_TBOX,ADCU,EPB,EBS
 SG_ VBUS_VCU4_N_AverageConsumedPower : 16|16@1+ (0.1,0) [0|6553.5] "kW·h/100km" CDCU,VDR_TBOX,ADCU
 SG_ VBUS_VCU4_St_Gears : 32|2@1+ (1,0) [0|3] "" CDCU,VDR_TBOX,ADCU,EPB,FCS,EPS_M,EPS_S
 SG_ VBUS_VCU4_St_Ready : 34|1@1+ (1,0) [0|1] "" CDCU,VDR_TBOX,CMS_R,CMS_B,ADCU,FCS
 SG_ VBUS_VCU4_St_Vehicle : 35|2@1+ (1,0) [0|3] "" CDCU,VDR_TBOX,ADCU
 SG_ VBUS_VCU4_St_Interlocking : 37|1@1+ (1,0) [0|1] "" CDCU,VDR_TBOX,ADCU
 SG_ VBUS_VCU4_St_ShiftGearBrkOn : 38|1@1+ (1,0) [0|1] "" CDCU,VDR_TBOX,ADCU
 SG_ VBUS_VCU4_F_ShiftGears : 39|1@1+ (1,0) [0|1] "" CDCU,ADCU
 SG_ VBUS_VCU4_F_Motor : 41|2@1+ (1,0) [0|3] "" CDCU,VDR_TBOX,ADCU
 SG_ VBUS_VCU4_F_MotorOverTemp : 43|1@1+ (1,0) [0|1] "" CDCU,VDR_TBOX,ADCU
 SG_ VBUS_VCU4_St_DISCHARGE_STA : 46|2@1+ (1,0) [0|3] "" CDCU,VDR_TBOX,ADCU
 SG_ VBUS_VCU4_N_EVRemainDriverRange : 48|10@1+ (1,0) [0|1023] "km" CDCU,VDR_TBOX,ADCU
 SG_ VBUS_VCU4_St_BrakeSta : 58|1@1+ (1,0) [0|1] "" CDCU,VDR_TBOX,ADCU
 SG_ VBUS_VCU4_St_Thermal_runaway : 59|1@1+ (1,0) [0|1] "" CDCU,VDR_TBOX,ADCU
 SG_ VBUS_VCU4_RollingCounter : 60|4@1+ (1,0) [0|15] "" CDCU,VDR_TBOX,ADCU

BO_ 2566853615 VCU_5: 8 VDCU_V
 SG_ VBUS_VCU5_N_DCVoltage : 0|16@1+ (0.1,0) [0|1000] "V" CDCU,ADCU,EPS_M
 SG_ VBUS_VCU5_N_DCCurrent : 16|16@1+ (0.1,-1000) [-1000|1000] "A" CDCU,ADCU,EPS_M
 SG_ VBUS_VCU5_N_SOC : 32|8@1+ (0.4,0) [0|100] "%" CDCU,ADCU,EPS_M
 SG_ VBUS_VCU5_St_LowSOC : 40|1@1+ (1,0) [0|1] "" CDCU,ADCU
 SG_ VBUS_VCU5_St_BatteryCHGHeating : 41|1@1+ (1,0) [0|1] "" CDCU,ADCU,EPS_M
 SG_ VBUS_VCU5_F_Battery : 42|1@1+ (1,0) [0|1] "" CDCU,ADCU,EPS_M
 SG_ VBUS_VCU5_F_OverTemperature : 44|1@1+ (1,0) [0|1] "" CDCU,ADCU,EPS_M
 SG_ VBUS_VCU5_F_LVBattVoltageLow : 45|1@1+ (1,0) [0|1] "" CDCU,ADCU,EPS_M
 SG_ VBUS_VCU5_St_HVDisConnect : 46|1@1+ (1,0) [0|1] "" CDCU,ADCU,EPS_M
 SG_ VBUS_VCU5_F_Isolation : 47|1@1+ (1,0) [0|1] "" CDCU,ADCU,EPS_M
 SG_ VBUS_VCU5_St_ChargerIndicator : 48|2@1+ (1,0) [0|3] "" CDCU,ADCU,EPS_M
 SG_ VBUS_VCU5_St_ChargerLine : 50|1@1+ (1,0) [0|1] "" CDCU,ADCU,EPS_M
 SG_ VBUS_VCU5_St_EnergyFlow : 51|2@1+ (1,0) [0|3] "" CDCU,ADCU,EPS_M
 SG_ VBUS_VCU5_St_ChargeMode : 53|2@1+ (1,0) [0|3] "" CDCU,ADCU,EPS_M
 SG_ VBUS_VCU5_St_PowerReduceOperation : 55|1@1+ (1,0) [0|1] "" CDCU,ADCU,EPS_M

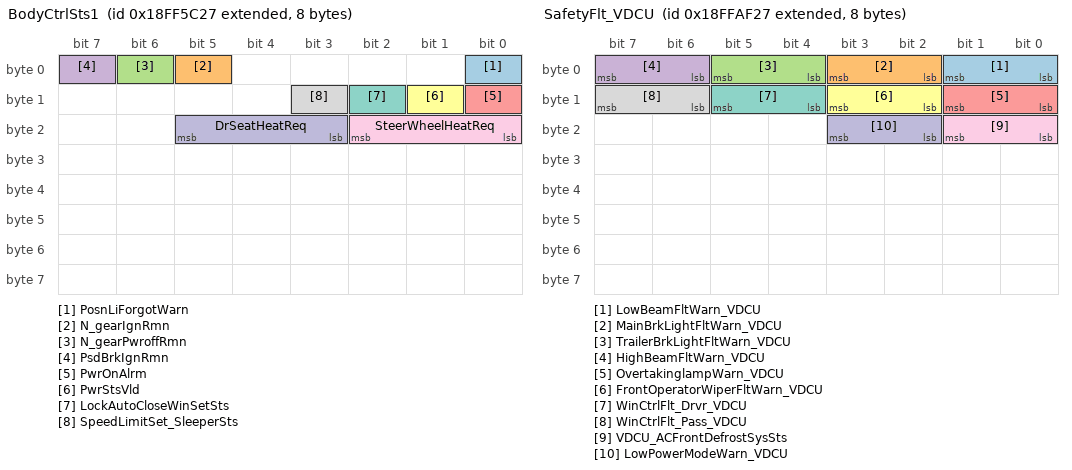
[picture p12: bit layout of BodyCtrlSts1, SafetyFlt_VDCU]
BO_ 2566872103 BodyCtrlSts1: 8 VDCU_V
 SG_ PosnLiForgotWarn : 0|1@1+ (1,0) [0|1] "" CDCU
 SG_ N_gearIgnRmn : 5|1@1+ (1,0) [0|1] "" CDCU
 SG_ N_gearPwroffRmn : 6|1@1+ (1,0) [0|1] "" CDCU
 SG_ PsdBrkIgnRmn : 7|1@1+ (1,0) [0|1] "" CDCU
 SG_ PwrOnAlrm : 8|1@1+ (1,0) [0|1] "" CDCU
 SG_ PwrStsVld : 9|1@1+ (1,0) [0|1] "" CDCU
 SG_ LockAutoCloseWinSetSts : 10|1@1+ (1,0) [0|1] "" CDCU
 SG_ SpeedLimitSet_SleeperSts : 11|1@1+ (1,0) [0|1] "" CDCU
 SG_ SteerWheelHeatReq : 16|3@1+ (1,0) [0|7] "" CDCU
 SG_ DrSeatHeatReq : 19|3@1+ (1,0) [0|7] "" CDCU

BO_ 2566893351 SafetyFlt_VDCU: 8 VDCU_V
 SG_ LowBeamFltWarn_VDCU : 0|2@1+ (1,0) [0|3] "" VIU_B,CDCU
 SG_ MainBrkLightFltWarn_VDCU : 2|2@1+ (1,0) [0|3] "" VIU_B,VIU_C,CDCU
 SG_ TrailerBrkLightFltWarn_VDCU : 4|2@1+ (1,0) [0|3] "" VIU_B,VIU_C,CDCU
 SG_ HighBeamFltWarn_VDCU : 6|2@1+ (1,0) [0|3] "" VIU_B,CDCU
 SG_ OvertakinglampWarn_VDCU : 8|2@1+ (1,0) [0|3] "" VIU_B,CDCU
 SG_ FrontOperatorWiperFltWarn_VDCU : 10|2@1+ (1,0) [0|3] "" VIU_B,CDCU
 SG_ WinCtrlFlt_Drvr_VDCU : 12|2@1+ (1,0) [0|3] "" VIU_B,CDCU
 SG_ WinCtrlFlt_Pass_VDCU : 14|2@1+ (1,0) [0|3] "" VIU_B,CDCU
 SG_ VDCU_ACFrontDefrostSysSts : 16|2@1+ (1,0) [0|3] "" CDCU
 SG_ LowPowerModeWarn_VDCU : 18|2@1+ (1,0) [0|3] "" CDCU

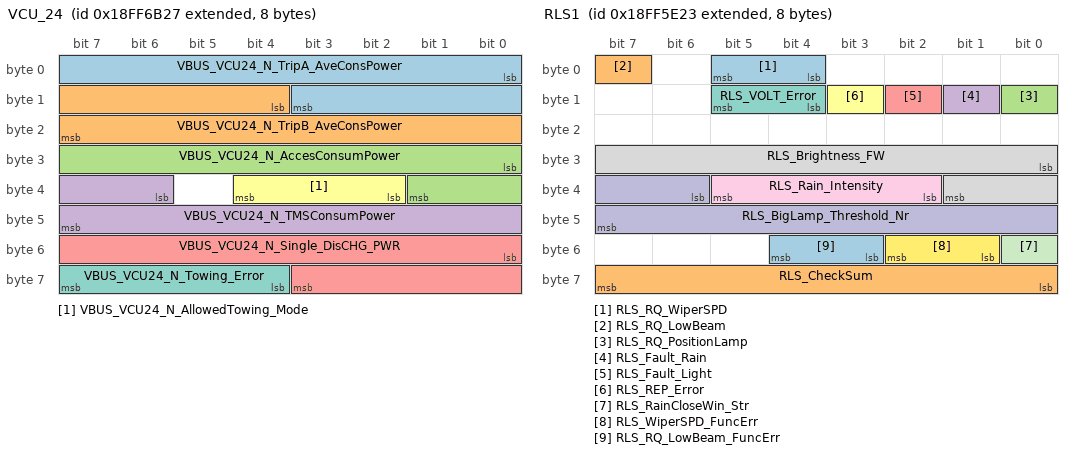
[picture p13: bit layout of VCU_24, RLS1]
BO_ 2566875943 VCU_24: 8 VDCU_V
 SG_ VBUS_VCU24_N_TripA_AveConsPower : 0|12@1+ (0.1,0) [0|409.5] "kW·h/100km" CDCU
 SG_ VBUS_VCU24_N_TripB_AveConsPower : 12|12@1+ (0.1,0) [0|409.5] "kW·h/100km" CDCU
 SG_ VBUS_VCU24_N_AccesConsumPower : 24|10@1+ (0.1,0) [0|100] "kW" CDCU
 SG_ VBUS_VCU24_N_TMSConsumPower : 38|10@1+ (0.1,0) [0|100] "kW" CDCU
 SG_ VBUS_VCU24_N_Single_DisCHG_PWR : 48|12@1+ (0.1,0) [0|400] "kW·h" CDCU
 SG_ VBUS_VCU24_N_AllowedTowing_Mode : 34|3@1+ (1,0) [0|7] "" CDCU
 SG_ VBUS_VCU24_N_Towing_Error : 60|4@1+ (1,0) [0|15] "" CDCU

BO_ 2566912807 VCU_25: 8 VDCU_V
 SG_ VBUS_VCU24_BMS538_TOTAL_CHG_PWR : 0|24@1+ (10,0) [0|167772150] "kW·h" CDCU

BO_ 2566861351 LiCtrl: 8 VDCU_V
 SG_ LeftTurnLightReq : 0|4@1+ (1,0) [0|15] "" VIU_B,VIU_C,CDCU,VDR_TBOX,ADCU
 SG_ RightTurnLightReq : 4|4@1+ (1,0) [0|15] "" VIU_B,VIU_C,CDCU,VDR_TBOX,ADCU
 SG_ HzrdLightReq : 8|1@1+ (1,0) [0|1] "" VIU_B,VIU_C,CDCU,VDR_TBOX,ADCU,FCS
 SG_ LowBeamReq : 9|1@1+ (1,0) [0|1] "" VIU_B,CDCU,VDR_TBOX,ADCU
 SG_ HighBeamReq : 10|1@1+ (1,0) [0|1] "" VIU_B,CDCU,VDR_TBOX,ADCU
 SG_ ReverseLampReq : 11|1@1+ (1,0) [0|1] "" VIU_C,VDR_TBOX,ADCU
 SG_ MainBrkLightReq : 12|2@1+ (1,0) [0|3] "" VIU_C,VDR_TBOX,ADCU
 SG_ TrailerBrkLightReq : 14|2@1+ (1,0) [0|3] "" VIU_C,VDR_TBOX,ADCU
 SG_ PosnLigjtReq : 16|1@1+ (1,0) [0|1] "" VIU_B,VIU_C,CDCU,VDR_TBOX,CMS_R,CMS_B,ADCU
 SG_ BacklightAdjustReq : 17|4@1+ (1,0) [0|15] "" VIU_B,VDR_TBOX,ADCU
 SG_ LeftDayTimeRunngLiReq : 21|1@1+ (1,0) [0|1] "" VDR_TBOX,ADCU
 SG_ RightDayTimeRunngLiReq : 22|1@1+ (1,0) [0|1] "" VDR_TBOX,ADCU
 SG_ RearFogLampReq : 23|1@1+ (1,0) [0|1] "" VIU_C,CDCU,VDR_TBOX,ADCU
 SG_ RearFogLampReplcmtReq : 24|1@1+ (1,0) [0|1] "" VDR_TBOX,ADCU
 SG_ LanternLanguageReq : 25|4@1+ (1,0) [0|15] "" VDR_TBOX
 SG_ IVI_FrontFogLampLinkageSetFB : 29|1@1+ (1,0) [0|1] "" CDCU
 SG_ LampFollowMeHomeSetSts : 32|2@1+ (1,0) [0|3] "" CDCU,VDR_TBOX
 SG_ LampAwayHomeSetSts : 34|2@1+ (1,0) [0|3] "" CDCU,VDR_TBOX
 SG_ ExtrMirrHeatCtrl : 36|2@1+ (1,0) [0|3] "" VIU_B,CDCU,VDR_TBOX
 SG_ ExtrMirrDirAdjmtCtrl_L : 40|3@1+ (1,0) [0|7] "" VIU_B,VDR_TBOX
 SG_ ExtrMirrDirAdjmtCtrl_R : 43|3@1+ (1,0) [0|7] "" VIU_B,VDR_TBOX
 SG_ FrontFogLampReq_L : 46|1@1+ (1,0) [0|1] "" VIU_B,CDCU,VDR_TBOX,ADCU
 SG_ FrontFogLampReq_R : 47|1@1+ (1,0) [0|1] "" VIU_B,CDCU,VDR_TBOX,ADCU

BO_ 2566861607 BodyCtrl1: 8 VDCU_V
 SG_ WinReq_L : 0|2@1+ (1,0) [0|3] "" VIU_B,VDR_TBOX
 SG_ WinReq_R : 2|2@1+ (1,0) [0|3] "" VIU_B,VDR_TBOX
 SG_ WasherReq : 8|2@1+ (1,0) [0|3] "" VIU_B,VDR_TBOX
 SG_ WiperReq : 10|3@1+ (1,0) [0|7] "" VIU_B,VDR_TBOX
 SG_ OutIncrWinAntAlarm : 13|1@1+ (1,0) [0|1] "" VIU_B
 SG_ StartStopButtonLiReq : 14|2@1+ (1,0) [0|3] "" VDR_TBOX
 SG_ RelayReq_ACC : 16|1@1+ (1,0) [0|1] "" VDR_TBOX
 SG_ RelayReq_IG1 : 17|1@1+ (1,0) [0|1] "" VDR_TBOX
 SG_ RelayReq_IG2 : 18|1@1+ (1,0) [0|1] "" VDR_TBOX
 SG_ CrankReq : 19|1@1+ (1,0) [0|1] "" VDR_TBOX
 SG_ RelaySts_ACC : 20|1@1+ (1,0) [0|1] "" VDR_TBOX
 SG_ RelaySts_IG1 : 21|1@1+ (1,0) [0|1] "" VDR_TBOX
 SG_ RelaySts_IG2 : 22|1@1+ (1,0) [0|1] "" VDR_TBOX
 SG_ LowPowerMode : 24|4@1+ (1,0) [0|15] "" VIU_B,VIU_C,CDCU,VDR_TBOX,CMS_R,CMS_B,ADCU,EPB,FCS,EBS,EPS_M,EPS_S,ECAS,EGSM
 SG_ RmtLowPowerMode : 29|1@1+ (1,0) [0|1] "" VIU_B
 SG_ RainCloseWinSwt_Fb : 30|2@1+ (1,0) [0|3] "" CDCU,VDR_TBOX
 SG_ RmtLocaloutreq_VDCU : 32|2@1+ (1,0) [0|1] "" VDR_TBOX
 SG_ BluetoothKeyConnect : 36|2@1+ (1,0) [0|2] "" VIU_B
 SG_ BluetoothKeyLocation : 41|3@1+ (1,0) [0|4] "" VIU_B
 SG_ BluetoothKeyReq : 44|4@1+ (1,0) [0|15] "" VIU_B
 SG_ BluetoothPhoneConnect : 48|2@1+ (1,0) [0|3] "" VIU_B
 SG_ PrimaryAntennaSleepSts : 50|2@1+ (1,0) [0|3] "" VIU_B

BO_ 2566845721 AMB1: 8 VDCU_V
 SG_ AmbAirT : 24|16@1+ (0.03125,-273) [-273|1734] "°C" VIU_C,CDCU,MTCU

BO_ 2566872611 RLS1: 8 VDCU_V
 SG_ RLS_RQ_WiperSPD : 4|2@1+ (1,0) [0|3] "" FCS
 SG_ RLS_RQ_LowBeam : 7|1@1+ (1,0) [0|1] "" Vector__XXX
 SG_ RLS_RQ_PositionLamp : 8|1@1+ (1,0) [0|1] "" Vector__XXX
 SG_ RLS_Fault_Rain : 9|1@1+ (1,0) [0|1] "" Vector__XXX
 SG_ RLS_Fault_Light : 10|1@1+ (1,0) [0|1] "" Vector__XXX
 SG_ RLS_REP_Error : 11|1@1+ (1,0) [0|1] "" Vector__XXX
 SG_ RLS_VOLT_Error : 12|2@1+ (1,0) [0|3] "" Vector__XXX
 SG_ RLS_Brightness_FW : 24|10@1+ (6,0) [0|6126] "LUX" Vector__XXX
 SG_ RLS_Rain_Intensity : 34|4@1+ (10,0) [0|100] "%" ADCU,FCS
 SG_ RLS_BigLamp_Threshold_Nr : 38|10@1+ (6,0) [0|6126] "LUX" Vector__XXX
 SG_ RLS_RainCloseWin_Str : 48|1@1+ (1,0) [0|1] "" Vector__XXX
 SG_ RLS_WiperSPD_FuncErr : 49|2@1+ (1,0) [0|3] "" CDCU
 SG_ RLS_RQ_LowBeam_FuncErr : 51|2@1+ (1,0) [0|3] "" CDCU
 SG_ RLS_CheckSum : 56|8@1+ (1,0) [0|255] "" Vector__XXX

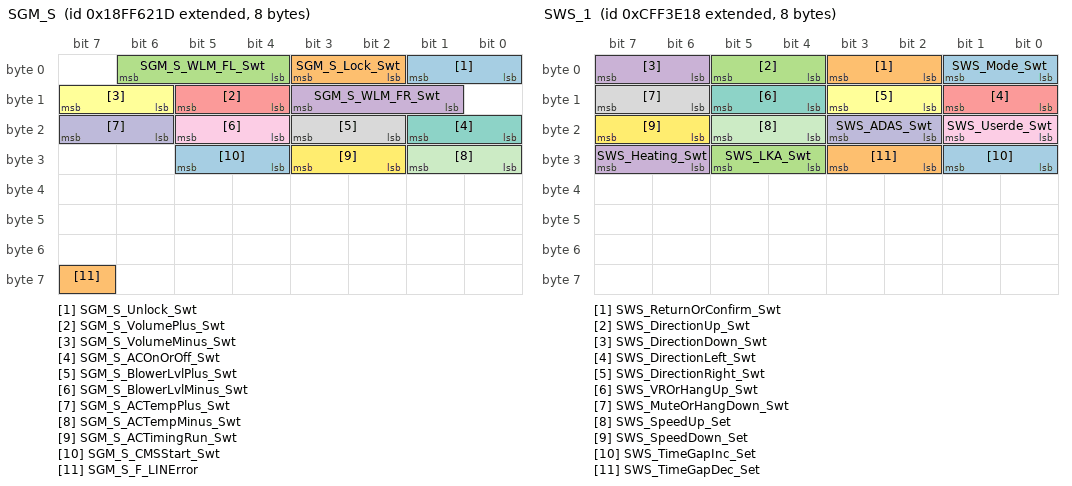
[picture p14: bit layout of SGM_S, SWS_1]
BO_ 2566873629 SGM_S: 8 VDCU_V
 SG_ SGM_S_Unlock_Swt : 0|2@1+ (1,0) [0|3] "" VIU_B
 SG_ SGM_S_Lock_Swt : 2|2@1+ (1,0) [0|3] "" VIU_B
 SG_ SGM_S_WLM_FL_Swt : 4|3@1+ (1,0) [0|7] "" Vector__XXX
 SG_ SGM_S_WLM_FR_Swt : 9|3@1+ (1,0) [0|7] "" Vector__XXX
 SG_ SGM_S_VolumePlus_Swt : 12|2@1+ (1,0) [0|3] "" CDCU
 SG_ SGM_S_VolumeMinus_Swt : 14|2@1+ (1,0) [0|3] "" CDCU
 SG_ SGM_S_ACOnOrOff_Swt : 16|2@1+ (1,0) [0|3] "" Vector__XXX
 SG_ SGM_S_BlowerLvlPlus_Swt : 18|2@1+ (1,0) [0|3] "" Vector__XXX
 SG_ SGM_S_BlowerLvlMinus_Swt : 20|2@1+ (1,0) [0|3] "" Vector__XXX
 SG_ SGM_S_ACTempPlus_Swt : 22|2@1+ (1,0) [0|3] "" Vector__XXX
 SG_ SGM_S_ACTempMinus_Swt : 24|2@1+ (1,0) [0|3] "" Vector__XXX
 SG_ SGM_S_ACTimingRun_Swt : 26|2@1+ (1,0) [0|3] "" Vector__XXX
 SG_ SGM_S_CMSStart_Swt : 28|2@1+ (1,0) [0|3] "" CMS_R,CMS_B
 SG_ SGM_S_F_LINError : 63|1@1+ (1,0) [0|1] "" VIU_B,CDCU,CMS_R,CMS_B

BO_ 2365537816 SWS_1: 8 VDCU_V
 SG_ SWS_Mode_Swt : 0|2@1+ (1,0) [0|3] "" CDCU
 SG_ SWS_ReturnOrConfirm_Swt : 2|2@1+ (1,0) [0|3] "" CDCU
 SG_ SWS_DirectionUp_Swt : 4|2@1+ (1,0) [0|3] "" CDCU
 SG_ SWS_DirectionDown_Swt : 6|2@1+ (1,0) [0|3] "" CDCU
 SG_ SWS_DirectionLeft_Swt : 8|2@1+ (1,0) [0|3] "" CDCU
 SG_ SWS_DirectionRight_Swt : 10|2@1+ (1,0) [0|3] "" CDCU
 SG_ SWS_VROrHangUp_Swt : 12|2@1+ (1,0) [0|3] "" CDCU
 SG_ SWS_MuteOrHangDown_Swt : 14|2@1+ (1,0) [0|3] "" CDCU
 SG_ SWS_Userde_Swt : 16|2@1+ (1,0) [0|3] "" CDCU,ADCU,FCS
 SG_ SWS_ADAS_Swt : 18|2@1+ (1,0) [0|3] "" CDCU,ADCU,FCS
 SG_ SWS_SpeedUp_Set : 20|2@1+ (1,0) [0|3] "" CDCU,ADCU,FCS
 SG_ SWS_SpeedDown_Set : 22|2@1+ (1,0) [0|3] "" CDCU,ADCU,FCS
 SG_ SWS_TimeGapInc_Set : 24|2@1+ (1,0) [0|3] "" CDCU,ADCU,FCS
 SG_ SWS_TimeGapDec_Set : 26|2@1+ (1,0) [0|3] "" CDCU,ADCU,FCS
 SG_ SWS_LKA_Swt : 28|2@1+ (1,0) [0|3] "" CDCU,ADCU,FCS
 SG_ SWS_Heating_Swt : 30|2@1+ (1,0) [0|3] "" VIU_B,CDCU

BO_ 2566873374 SGM_IP: 8 VDCU_V
 SG_ SGM_IP_HornType_Swt : 0|2@1+ (1,0) [0|3] "" VIU_B
 SG_ SGM_IP_RearLight_Swt : 2|2@1+ (1,0) [0|3] "" VIU_C
 SG_ SGM_IP_ACOff_Swt : 4|2@1+ (1,0) [0|3] "" Vector__XXX
 SG_ SGM_IP_BlowerLvlPlus_Swt : 6|2@1+ (1,0) [0|3] "" Vector__XXX
 SG_ SGM_IP_BlowerLvlMinus_Swt : 8|2@1+ (1,0) [0|3] "" Vector__XXX
 SG_ SGM_IP_ACTempPlus_Swt : 10|2@1+ (1,0) [0|3] "" Vector__XXX
 SG_ SGM_IP_ACTempMinus_Swt : 12|2@1+ (1,0) [0|3] "" Vector__XXX
 SG_ SGM_IP_ACFrontDefrost_Swt : 14|2@1+ (1,0) [0|3] "" Vector__XXX
 SG_ SGM_IP_F_LINError : 63|2@1+ (1,0) [0|3] "" Vector__XXX

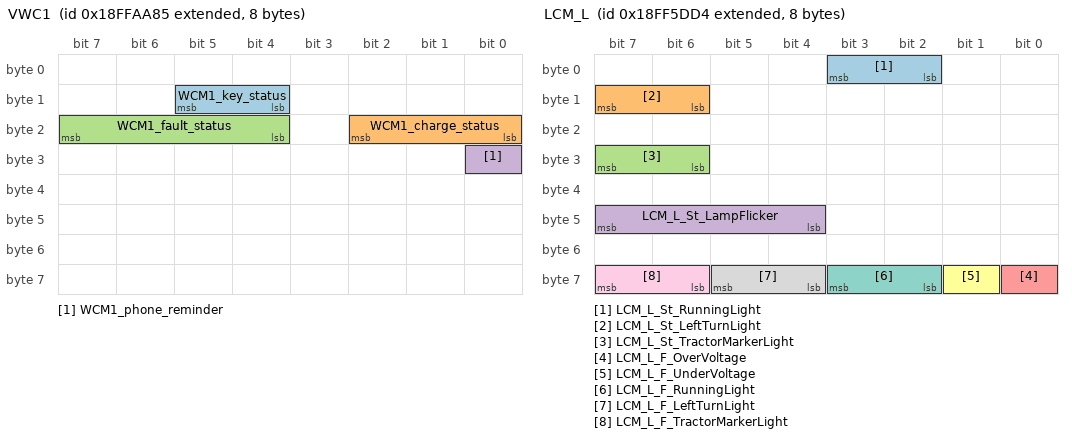
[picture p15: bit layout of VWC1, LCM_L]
BO_ 2566892165 VWC1: 8 VDCU_V
 SG_ WCM1_key_status : 12|2@1+ (1,0) [0|3] "" CDCU
 SG_ WCM1_charge_status : 16|3@1+ (1,0) [0|7] "" CDCU
 SG_ WCM1_fault_status : 20|4@1+ (1,0) [0|15] "" CDCU
 SG_ WCM1_phone_reminder : 24|1@1+ (1,0) [0|1] "" CDCU

BO_ 2566900371 LOGStatus: 8 VDCU_V
 SG_ LOG_LogoLightSet_Sts : 16|2@1+ (1,0) [0|3] "" CDCU

BO_ 2566872532 LCM_L: 8 VDCU_V
 SG_ LCM_L_St_RunningLight : 2|2@1+ (1,0) [0|3] "" CDCU,VDR_TBOX
 SG_ LCM_L_St_LeftTurnLight : 14|2@1+ (1,0) [0|3] "" CDCU,VDR_TBOX,FCS
 SG_ LCM_L_St_TractorMarkerLight : 30|2@1+ (1,0) [0|3] "" CDCU,VDR_TBOX
 SG_ LCM_L_St_LampFlicker : 44|4@1+ (1,0) [0|15] "" CDCU,VDR_TBOX
 SG_ LCM_L_F_OverVoltage : 56|1@1+ (1,0) [0|1] "" CDCU,VDR_TBOX
 SG_ LCM_L_F_UnderVoltage : 57|1@1+ (1,0) [0|1] "" CDCU,VDR_TBOX
 SG_ LCM_L_F_RunningLight : 58|2@1+ (1,0) [0|3] "" CDCU,VDR_TBOX
 SG_ LCM_L_F_LeftTurnLight : 60|2@1+ (1,0) [0|3] "" CDCU,VDR_TBOX
 SG_ LCM_L_F_TractorMarkerLight : 62|2@1+ (1,0) [0|3] "" CDCU,VDR_TBOX

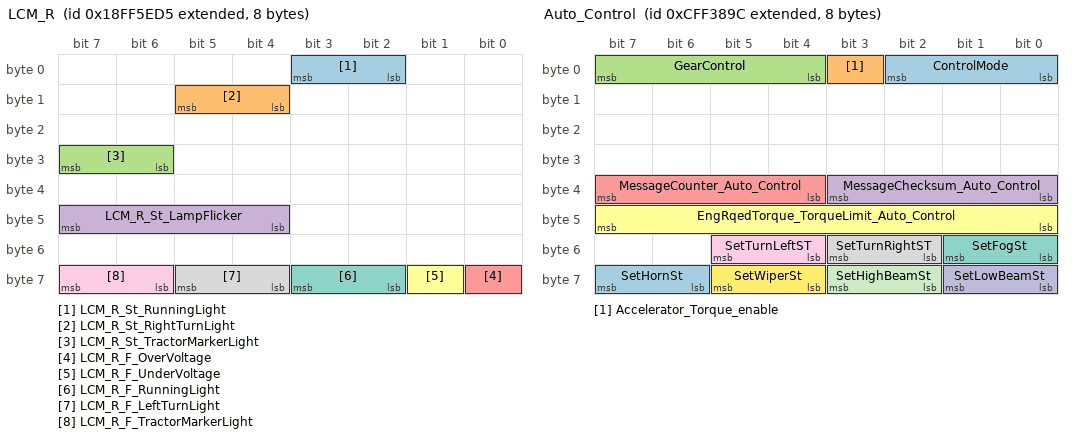
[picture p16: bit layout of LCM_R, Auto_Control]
BO_ 2566872789 LCM_R: 8 VDCU_V
 SG_ LCM_R_St_RunningLight : 2|2@1+ (1,0) [0|3] "" CDCU,VDR_TBOX
 SG_ LCM_R_St_RightTurnLight : 12|2@1+ (1,0) [0|3] "" CDCU,VDR_TBOX,FCS
 SG_ LCM_R_St_TractorMarkerLight : 30|2@1+ (1,0) [0|3] "" CDCU,VDR_TBOX
 SG_ LCM_R_St_LampFlicker : 44|4@1+ (1,0) [0|15] "" CDCU,VDR_TBOX
 SG_ LCM_R_F_OverVoltage : 56|1@1+ (1,0) [0|1] "" CDCU,VDR_TBOX
 SG_ LCM_R_F_UnderVoltage : 57|1@1+ (1,0) [0|1] "" CDCU,VDR_TBOX
 SG_ LCM_R_F_RunningLight : 58|2@1+ (1,0) [0|3] "" CDCU,VDR_TBOX
 SG_ LCM_R_F_LeftTurnLight : 60|2@1+ (1,0) [0|3] "" CDCU,VDR_TBOX
 SG_ LCM_R_F_TractorMarkerLight : 62|2@1+ (1,0) [0|3] "" CDCU,VDR_TBOX

BO_ 2566867415 EPU_L: 8 VDCU_V
 SG_ EPU_LeftStepStatus : 0|3@1+ (1,0) [0|7] "" CDCU

BO_ 2566867672 EPU_R: 8 VDCU_V
 SG_ EPU_RightStepStatus : 0|3@1+ (1,0) [0|7] "" CDCU

BO_ 2365536412 Auto_Control: 8 ADCU
 SG_ ControlMode : 0|3@1+ (1,0) [0|7] "" VDCU_V
 SG_ Accelerator_Torque_enable : 3|1@1+ (1,0) [0|1] "" VDCU_V
 SG_ GearControl : 4|4@1+ (1,0) [0|15] "" VDCU_V
 SG_ MessageChecksum_Auto_Control : 32|4@1+ (1,0) [0|15] "" VDCU_V
 SG_ MessageCounter_Auto_Control : 36|4@1+ (1,0) [0|15] "" VDCU_V
 SG_ EngRqedTorque_TorqueLimit_Auto_Control : 40|8@1+ (1,-125) [-125|125] "%" VDCU_V
 SG_ SetFogSt : 48|2@1+ (1,0) [0|3] "" VDCU_V
 SG_ SetTurnRightST : 50|2@1+ (1,0) [0|3] "" VDCU_V
 SG_ SetTurnLeftST : 52|2@1+ (1,0) [0|3] "" VDCU_V
 SG_ SetLowBeamSt : 56|2@1+ (1,0) [0|3] "" VDCU_V
 SG_ SetHighBeamSt : 58|2@1+ (1,0) [0|3] "" VDCU_V
 SG_ SetWiperSt : 60|2@1+ (1,0) [0|3] "" VDCU_V
 SG_ SetHornSt : 62|2@1+ (1,0) [0|3] "" VDCU_V

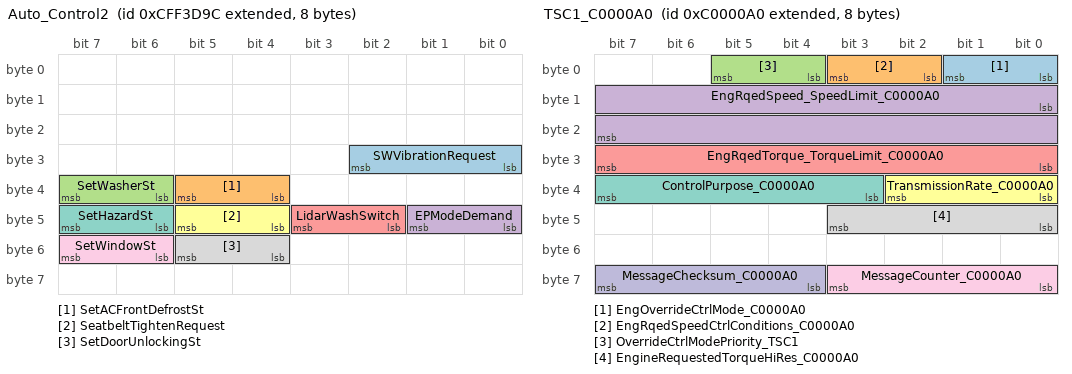
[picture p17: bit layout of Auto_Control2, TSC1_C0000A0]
BO_ 2365537692 Auto_Control2: 8 ADCU
 SG_ SWVibrationRequest : 24|3@1+ (1,0) [0|7] "" VDCU_V
 SG_ SetACFrontDefrostSt : 36|2@1+ (1,0) [0|3] "" VDCU_V
 SG_ SetWasherSt : 38|2@1+ (1,0) [0|3] "" VDCU_V
 SG_ EPModeDemand : 40|2@1+ (1,0) [0|3] "" VDCU_V
 SG_ LidarWashSwitch : 42|2@1+ (1,0) [0|3] "" VDCU_V
 SG_ SeatbeltTightenRequest : 44|2@1+ (1,0) [0|3] "" VDCU_V
 SG_ SetHazardSt : 46|2@1+ (1,0) [0|3] "" VDCU_V
 SG_ SetDoorUnlockingSt : 52|2@1+ (1,0) [0|3] "" VDCU_V
 SG_ SetWindowSt : 54|2@1+ (1,0) [0|3] "" VDCU_V

BO_ 2348810400 TSC1_C0000A0: 8 FCS
 SG_ EngOverrideCtrlMode_C0000A0 : 0|2@1+ (1,0) [0|3] "" VDCU_V
 SG_ EngRqedSpeedCtrlConditions_C0000A0 : 2|2@1+ (1,0) [0|3] "" VDCU_V
 SG_ OverrideCtrlModePriority_TSC1 : 4|2@1+ (1,0) [0|3] "" VDCU_V
 SG_ EngRqedSpeed_SpeedLimit_C0000A0 : 8|16@1+ (0.125,0) [0|8031.875] "rpm" VDCU_V
 SG_ EngRqedTorque_TorqueLimit_C0000A0 : 24|8@1+ (1,-125) [-125|125] "%" VDCU_V
 SG_ TransmissionRate_C0000A0 : 32|3@1+ (1,0) [0|7] "" VDCU_V
 SG_ ControlPurpose_C0000A0 : 35|5@1+ (1,0) [0|31] "" VDCU_V
 SG_ EngineRequestedTorqueHiRes_C0000A0 : 40|4@1+ (0.125,0) [0|0.875] "%" VDCU_V
 SG_ MessageCounter_C0000A0 : 56|4@1+ (1,0) [0|15] "" VDCU_V
 SG_ MessageChecksum_C0000A0 : 60|4@1+ (1,0) [0|15] "" VDCU_V

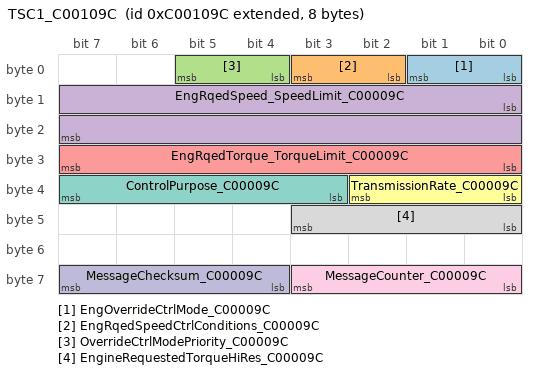
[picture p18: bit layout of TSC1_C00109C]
BO_ 2348814492 TSC1_C00109C: 8 ADCU
 SG_ EngOverrideCtrlMode_C00009C : 0|2@1+ (1,0) [0|3] "" VDCU_V
 SG_ EngRqedSpeedCtrlConditions_C00009C : 2|2@1+ (1,0) [0|3] "" VDCU_V
 SG_ OverrideCtrlModePriority_C00009C : 4|2@1+ (1,0) [0|3] "" VDCU_V
 SG_ EngRqedSpeed_SpeedLimit_C00009C : 8|16@1+ (0.125,0) [0|8031.875] "rpm" VDCU_V
 SG_ EngRqedTorque_TorqueLimit_C00009C : 24|8@1+ (1,-125) [-125|125] "%" VDCU_V
 SG_ TransmissionRate_C00009C : 32|3@1+ (1,0) [0|7] "" VDCU_V
 SG_ ControlPurpose_C00009C : 35|5@1+ (1,0) [0|31] "" VDCU_V
 SG_ EngineRequestedTorqueHiRes_C00009C : 40|4@1+ (0.125,0) [0|0.875] "%" VDCU_V
 SG_ MessageCounter_C00009C : 56|4@1+ (1,0) [0|15] "" VDCU_V
 SG_ MessageChecksum_C00009C : 60|4@1+ (1,0) [0|15] "" VDCU_V

BO_ 2349465760 CCVS2_AEB: 8 ADCU
 SG_ CruiseCtrlDisableCommand : 0|2@1+ (1,0) [0|3] "" VDCU_V

BO_TX_BU_ 2349465760 : ADCU,FCS;

CM_ BO_ 2566853015 "新能源设置";
CM_ BO_ 2566908234 "应为OnRequest";
CM_ BO_ 2566908490 "应为OnRequest";
CM_ BO_ 2566908199 "应为OnRequest";
CM_ BO_ 2566908455 "应为OnRequest";
CM_ SG_ 2566889511 VDCU_SourceNodeID "源节点 ID";
CM_ SG_ 2566889511 VDCU_ActiveWakeUpBit "主动唤醒标志位";
CM_ SG_ 2566889511 VDCU_RepeatMessageRequest "重复报文请求标志位";
CM_ SG_ 2566889511 VDCU_NMState_RMSfromBSM "重复报文状态（从总线睡眠模式切换而来）";
CM_ SG_ 2566889511 VDCU_NMState_RMSfromPBSM "重复报文状态（从预总线切换而来）";
CM_ SG_ 2566889511 VDCU_NMState_RMSfromNOS "重复报文状态（从正常运行状态切换而来）";
CM_ SG_ 2566889511 VDCU_NMState_RMSfromRSS "重复报文状态（从准备睡眠状态切换而来）";
CM_ SG_ 2566889511 VDCU_NMState_NOSfromRMS "正常运行状态（从重复报文状态切换而来）";
CM_ SG_ 2566889511 VDCU_NMState_NOSfromRSS "正常运行状态（从准备睡眠状态切换而来）";
CM_ SG_ 2566889511 VDCU_WakeupSource "唤醒源（本次唤醒的首次唤醒源）";
CM_ SG_ 2566889511 VDCU_NMKpARson_NMPduReceived "NM唤醒源（维持唤醒源）收到NM报文";
CM_ SG_ 2566889511 VDCU_NMKpARson_TimeOut "NM唤醒源（维持唤醒源）Repeat Message定时器没有到期";
CM_ SG_ 2566889511 VDCU_NMKpARson_Diag "NM唤醒源（维持唤醒源）诊断";
CM_ SG_ 2566889511 VDCU_NMKpARson_KL15 "NM唤醒源（维持唤醒源）检测到低压电源状态处于ON或Crank";
CM_ SG_ 2566889511 VDCU_NMKpARson_LINReq "NM唤醒源（维持唤醒源）LIN唤醒";
CM_ SG_ 2566889511 VDCU_NMKpARson_WinCtrl_L "NM唤醒源（维持唤醒源）主驾车窗控制命令输出";
CM_ SG_ 2566889511 VDCU_NMKpARson_WinCtrl_R "NM唤醒源（维持唤醒源）副驾车窗控制命令输出";
CM_ SG_ 2566889511 VDCU_NMKpARson_BrakePedalPressed "NM唤醒源（维持唤醒源）制动踏板踩下";
CM_ SG_ 2566889511 VDCU_NMKpARson_LowBeamReq "NM唤醒源（维持唤醒源）近光灯控制灯光输出命令";
CM_ SG_ 2566889511 VDCU_NMKpARson_PosnLigjtReq "NM唤醒源（维持唤醒源）位置灯控制灯光输出命令";
CM_ SG_ 2566889511 VDCU_NMKpARson_DCChargeActive "NM唤醒源（维持唤醒源）直流充电激活信号有效";
CM_ SG_ 2566889511 VDCU_NMKpARson_PowerOFFdelayMonitor "NM唤醒源（维持唤醒源）下电延时监控有效";
CM_ SG_ 2566889511 VDCU_NMKpARson_ACChargeActive "NM唤醒源（维持唤醒源）交流充电激活信号有效";
CM_ SG_ 2566889511 VDCU_NMKpARson_HVConnected "NM唤醒源（维持唤醒源）检测到高压上电处于高压连接状态";
CM_ SG_ 2566889511 VDCU_NMKpARson_ChargeWarmer "NM唤醒源（维持唤醒源）电池充电保温功能激活";
CM_ SG_ 2566889511 VDCU_NMKpARson_Ready "NM唤醒源（维持唤醒源）高压连接状态";
CM_ SG_ 2566889511 VDCU_NMKpARson_SmartCharge "NM唤醒源（维持唤醒源）蓄电池智能补电功能激活";
CM_ SG_ 2566870679 WinCtrlReq_Drvr "司机侧车窗控制请求";
CM_ SG_ 2566870679 WinCtrlReq_Pass "副驾侧车窗控制请求";
CM_ SG_ 2566870679 WinCtrl_VoiceFlag "车窗语音控制标志位";
CM_ SG_ 2566870679 IVI_DrSeatHeatSw "主驾座椅加热软开关";
CM_ SG_ 2566870679 IVI_DrSeatWindLevelSet "主驾通风状态等级设置";
CM_ SG_ 2566870679 IVI_DrSeatMassageModSet "预留。主驾座椅按摩模式设置";
CM_ SG_ 2566870679 IVI_HeatlinkageSet "座椅加热与方向盘加热联动设置";
CM_ SG_ 2566870679 IVI_ExtrMirrHeatSwt "后视镜加热软开关（预留）";
CM_ SG_ 2566870679 IVI_SWS_UserDifined "方向盘自定义按键设置";
CM_ SG_ 2566870679 IVI_SteerWheelHeatSwt "方向盘加热软开关";
CM_ SG_ 2566900119 IVI_HornShiftSwitch "预留软开关。喇叭切换开关，1、气喇叭；2、电喇叭。";
CM_ SG_ 2566900119 IVI_VehLockRemindSet "锁车提示设置请求，包含以下状态:1、双闪灯模式；2、双闪灯+喇叭模式。";
CM_ SG_ 2566900119 IVI_LampFollowMeHomeSet "伴我回家灯光点亮时间设置，包含以下状态:1、30S；2、60S；3、90S。";
CM_ SG_ 2566900119 IVI_LampAwayHomeSet "照我离家灯光点亮时间设置，包含以下状态:1、30S；2、60S；3、90S。";
CM_ SG_ 2566900119 IVI_FindMyCarSet "寻车模式，包含以下状态:1、双闪灯模式；2、双闪灯+喇叭模式。";
CM_ SG_ 2566900119 IVI_SmartWelcomeSet "智能迎宾模式开启关闭设置，包含以下状态:1、关闭；2、开启";
CM_ SG_ 2566900119 IVI_LogoLightSwitch "Logo灯开关";
CM_ SG_ 2566900119 IVI_ADBSwitch "ADB功能开启、关闭请求，包含以下请求:1、开启；2、关闭。";
CM_ SG_ 2566900119 IVI_RainAutoCloseWinSet "雨天自动关窗设置";
CM_ SG_ 2566900119 IVI_LockAutoCloseWinSet "锁车自动关窗功能设置请求";
CM_ SG_ 2566900119 IVI_UnlockSet "单门或 全车解锁设置";
CM_ SG_ 2566900119 IVI_SpeedAutoLockSet "行车闭锁";
CM_ SG_ 2566900119 IVI_StopAutoUnlockSet "熄火解锁功能设置请求";
CM_ SG_ 2566900119 IVI_ApproachAutoUnlockSet "近车自动解锁Approaching Vehicle AUTO Unlock";
CM_ SG_ 2566900119 IVI_AwayAutoLockSet "离车自动闭锁";
CM_ SG_ 2566900119 IVI_SpeedLimitSet_Sleeper "卧铺测车速限制信号";
CM_ SG_ 2566900119 IVI_WCMEnableSwitch "手机无线充电功能使能";
CM_ SG_ 2566900119 IVI_BackLightBriSet "背光亮度调节设置";
CM_ SG_ 2566900119 CeilingLightSet "顶灯控制请求（开关、语音）";
CM_ SG_ 2566900119 IVI_VSPOpenSet "VPS开启关闭请求";
CM_ SG_ 2566854039 ExtrMirrorCtrlMode_ "后视镜模式控制，切换方向盘按键音频（Inactive）/后视镜调节功能（Active）是否展开多种模式";
CM_ SG_ 2566854039 ExtrMirrDirAdjmtSoftSwt_L "左侧后视镜调节软开关请求ExtrMirrorDirectionAdjustmentSoftSwitch";
CM_ SG_ 2566854039 ExtrMirrDirAdjmtSoftSwt_R "右侧后视镜调节软开关请求ExtrMirrorDirectionAdjustmentSoftSwitch";
CM_ SG_ 2566854039 ExtrMirrDirAdjmtLogicSwt_L "左侧后视镜视野调节逻辑开关（仲裁后）";
CM_ SG_ 2566854039 ExtrMirrDirAdjmtLogicSwt_R "右侧后视镜视野调节逻辑开关（仲裁后）";
CM_ SG_ 2566854039 CMS_TemporaryViewSwt "电子外后视镜临时视野开启开关信号";
CM_ SG_ 2566854039 CMS_BrightnessAdjMod "亮度模式调节: 手动 自动";
CM_ SG_ 2566854039 CMS_DefaultView_R "电子后视镜视野复位开关_右侧";
CM_ SG_ 2566854039 CMS_DefaultView "电子后视镜视野复位开关";
CM_ SG_ 2566854039 CMS_BrightnessAdj "左侧CMS亮度调节档位";
CM_ SG_ 2566854039 CMS_AuxiliaryLines_Enable "CMS辅助线调节使能开关";
CM_ SG_ 2566854039 CMS_AuxiliaryLines "CMS辅助线调节";
CM_ SG_ 2566907927 CDCU_MLS_Page "手动学习状态页";
CM_ SG_ 2566907927 CDCU_MLS_truck_trailer "卡车/挂车标志位(声明该报文与牵引车相关还是和挂车相关当MLS Page = 0时)";
CM_ SG_ 2566907927 CDCU_MLS "手动学习状态";
CM_ SG_ 2566907927 CDCU_MLS_Tyre_Loc "所学习的轮胎位置";
CM_ SG_ 2566723351 DriverBeltlockStatus "State of switch used to determine if Driver Beltlock is buckled驾驶员安全带状态";
CM_ SG_ 2566723351 PassengerBeltlockStatus "State of switch used to determine if Passenger Beltlock is buckled.副驾驶员安全带状态";
CM_ SG_ 2566850171 DMS_SeatShakeSts "驾驶员疲劳提醒-座椅震动请求";
CM_ SG_ 2563833751 IlluminationBrightnessPercent "Commanded backlight brightness level for all cab displays.  开关背光灯亮度控制";
CM_ SG_ 2566905239 IVI_ACOffSwt "空调OFF请求";
CM_ SG_ 2566905239 IVI_ACAutoSwt "Auto设置";
CM_ SG_ 2566905239 IVI_ACModeMotorSwt "模式挡位开关";
CM_ SG_ 2566905239 IVI_ACACSwt "AC开关请求信号";
CM_ SG_ 2566905239 IVI_ACPTCSwt "PTC开关请求信号";
CM_ SG_ 2566905239 IVI_ACCycleMotorSwt "内外循环请求开关";
CM_ SG_ 2566905239 IVI_ACFrontDefrostSwt "前除霜开关";
CM_ SG_ 2566905239 IVI_ACTempPlusSwt "空调温度+开关，长按时间≥2s，按照每0,3s变化1℃发送。";
CM_ SG_ 2566905239 IVI_ACTempMinusSwt "空调温度-开关 ，长按时间≥2s，按照每0,3s变化1℃发送。";
CM_ SG_ 2566905239 IVI_ACTempLevelSwt "冷暖挡位控制 按0.5精度 17-32";
CM_ SG_ 2566905239 IVI_ACBlowerLvlSeltSwt "风量控制档位选择";
CM_ SG_ 2566905239 IVI_LonizerSwt "负离子ON/OFF请求";
CM_ SG_ 2566905239 IVI_AirPurgeSwt "空气净化（前排）Air Purge";
CM_ SG_ 2566905239 IVI_AcMaxSwt "最大制冷开关/前排急速制冷开关";
CM_ SG_ 2566905239 IVI_HeatingMaxSwt "前排急速制热请求";
CM_ SG_ 2566905239 IVI_TempZoneSyncSwt "空调温区同步请求 前排卧铺同步";
CM_ SG_ 2566905239 IVI_ACBlowerLvlSeltSwt_Slpr "卧铺风量控制档位选择";
CM_ SG_ 2566905239 IVI_ACTempPlusSwt_Slpr "卧铺温度+  Sleeper";
CM_ SG_ 2566905239 IVI_ACTempMinusSwt_Slpr "卧铺温度-";
CM_ SG_ 2566905239 IVI_ACTempLevelSwt_Slpr "卧铺冷暖挡位控制 按0.5精度 17-32";
CM_ SG_ 2566905239 IVI_ACBlowerPlusSwt_Slpr "卧铺风量+";
CM_ SG_ 2566905239 IVI_ACBlowerMinusSwt_Slpr "卧铺风量-";
CM_ SG_ 2566905239 IVI_ACBlowerLvlMinusSwt "风量控制档位-开关，长按时间≥2s，按照每2s变化1℃发送。";
CM_ SG_ 2566905239 IVI_ACOffSwt_Slpr "卧铺空调OFF请求";
CM_ SG_ 2566905239 IVI_ACTimingRunSwt_Slpr "卧铺驻车定时通风";
CM_ SG_ 2566854551 WheelDifferentialLock_Sw "轮间差速锁开关";
CM_ SG_ 2566854551 AxleDifferentialLockSwt "预留。轴间差速锁";
CM_ SG_ 2566854551 V2V_Sw "对外放电V2V开关";
CM_ SG_ 2566854551 V2G_Sw "对外放电V2G开关";
CM_ SG_ 2566854551 V2V_V2G_StopSoc_Set "设置V2V V2G防电截止SOC值";
CM_ SG_ 2566854551 BattIIntlgntRecharge_Set "蓄电池智能补电功能设置batterie recharge Intelligent  默认0x1";
CM_ SG_ 2566854551 IVI_220VSocket_Sw "220V车内取电插座取电请求开关设置请求";
CM_ SG_ 2566854551 EnergyMode_Set "能源模式请求状态";
CM_ SG_ 2566854551 IVI_VehicleCreepSet "蠕行功能启用设置";
CM_ SG_ 2566854551 IVI_VehicleDragModeSet "拖车模式请求";
CM_ SG_ 2566854551 IVI_EPModeSet "驾驶模式设置";
CM_ SG_ 2566854551 IVI_ServiceModeSet "低压维修模式设置";
CM_ SG_ 2566854551 IVI_DrivngMileageDisplaySet "续航里程显示方式设置";
CM_ SG_ 2566850711 IVI_ChargingKeepWarmSet "充电保温设置";
CM_ SG_ 2566850711 IVI_HeatByApntmntSet "预约加热功能激活  TBOX收";
CM_ SG_ 2566850711 IVI_HeatByApntmntReplicationSet "预约加热功能重复设置HeatingByAppointment";
CM_ SG_ 2566850711 IVI_HeatByApntmntHourStart "预约加热出行时间-时 0-23时";
CM_ SG_ 2566850711 IVI_HeatByApntmntMinuteStart "预约加热出行时间-分 0-59分";
CM_ SG_ 2566850711 IVI_ChargngByApntmntSet "预约直流充电功能激活  TBOX收";
CM_ SG_ 2566850711 IVI_ChargngByApntmntHourStart "预约直流充电设置开启时间-时 0-23时";
CM_ SG_ 2566850711 IVI_ImmediatStartChargngSet "立即充电开关";
CM_ SG_ 2566850711 IVI_ChargngByApntmntMinuteStart "预约直流充电设置-分 0-59分";
CM_ SG_ 2566850711 IVI_ChargngByApntmntReplicationSet "预约直流充电功能重复设置ChargingByAppointment Replication";
CM_ SG_ 2566850711 IVI_ChargngByApntmntHourEnd "预约直流充电设置结束时间-时 0-23时0x1E定义“充满”的信号";
CM_ SG_ 2566850711 IVI_ChargngByApntmntMinuteEnd "预约直流充电设置-分 0-59分0x3E定义“充满”的信号";
CM_ SG_ 2566850711 IVI_ChargingStopSwt "充电停止开关";
CM_ SG_ 2566853015 IVI_SwSet_V2GByApntmntHourStart "预计用车时间（时）设置";
CM_ SG_ 2566853015 IVI_SwSet_V2GByApntmntMinuteStart "预计用车时间（分）设置";
CM_ SG_ 2566853015 IVI_Sw_V2GExpectedSOCForVehicleUse "取车期望SOC值设置";
CM_ SG_ 2566853015 IVI_Sw_StopDCDisCharging "直流放电停止开关设置";
CM_ SG_ 2566865177 ACTempLevelDisp "用户设定温度显示 按0.5精度 17-32";
CM_ SG_ 2566865177 ACPTCDisp "Beacon预留，空调PTC档位显示";
CM_ SG_ 2566865177 ACTempLevelCtrl "用户设定温度控制";
CM_ SG_ 2566865177 ACModeMotorDisp "模式挡位显示";
CM_ SG_ 2566865177 ACModeMotorCtrl "模式风门电机位置控制";
CM_ SG_ 2566865177 ACCycleMotorDisp "内外循环档位显示 inside and outside circulation mode";
CM_ SG_ 2566865177 ACCycleMotorPosnCtrl "内外循环风门电机位置控制";
CM_ SG_ 2566865177 ACBlowerLevelDisp "风量档位显示";
CM_ SG_ 2566865177 ACBlowerLevelCtrl "鼓风机挡位控制";
CM_ SG_ 2566865177 ACFrontDefrostDisp "前除霜档位显示";
CM_ SG_ 2566865177 ACAcDisp "空调AC档位显示";
CM_ SG_ 2566865177 ACMaxDisp "ACMax档位显示（急速制冷）";
CM_ SG_ 2566865177 ACAutoDisp "Auto档位显示";
CM_ SG_ 2566865177 ACOffDisp "OFF档位显示OFF控制=OFF即空调开机";
CM_ SG_ 2566865177 ACAirPurgeDisp "空气净化显示";
CM_ SG_ 2566865177 ACAirPurgeCtrl "空气净化控制";
CM_ SG_ 2566865177 ACLonizerDisp "负离子发生器工作显示";
CM_ SG_ 2566865177 ACLonizerCtrl "负离子发生器控制";
CM_ SG_ 2566865177 AC_TempZoneSyncSts "空调温区同步状态反馈 前排卧铺同步";
CM_ SG_ 2566865177 AC_HeatingMaxSts "前排急速制热状态（急速制热）";
CM_ SG_ 2566865177 ElecACTempLevelDisp "Beacon，电动空调温度档位显示";
CM_ SG_ 2566868505 HVPowerOnReq_HBattFan "预留。高压冷却风扇-电堆上高压请求";
CM_ SG_ 2566868505 HVPowerOnReq_HMotorFan "预留。高压冷却风扇-电机上高压请求";
CM_ SG_ 2566868505 HVPowerOnReq_EAS1 "压缩机1（空调）上高压请求";
CM_ SG_ 2566868505 HVPowerOnReq_EAS2 "压缩机2（动力电池）上高压请求";
CM_ SG_ 2566868505 HVPowerOnReq_EAS3 "压缩机3（动力电池）上高压请求";
CM_ SG_ 2566868505 HVPowerOnReq_WPTC1 "WPTC1上高压请求";
CM_ SG_ 2566868505 HVPowerOnReq_WPTC2 "WPTC2上高压请求";
CM_ SG_ 2566868505 HVPowerOnReq_WPTC3 "WPTC3上高压请求";
CM_ SG_ 2566868505 HVPowerOnReq_APTC "APTC上高压请求";
CM_ SG_ 2566868505 APTC_PowerCtrl "APTC功率控制请求信号，0-3500W /100";
CM_ SG_ 2566865433 ACTempLevelDispSlpr "卧铺空调用户设定温度显示";
CM_ SG_ 2566865433 ACTempLevelCtrl_Slpr "卧铺空调用户设定温度控制";
CM_ SG_ 2566865433 ACBlowerLevelDisp_Slpr "卧铺空调风量控制档位显示";
CM_ SG_ 2566865433 ACBlowerLevelCtrl_Slpr "卧铺鼓风机挡位控制";
CM_ SG_ 2566865433 ACTimingRunDisp_Slpr "驻车定时通风（卧铺）档位显示";
CM_ SG_ 2566865433 ACOffDisp_Slpr "卧铺空调OFF档位显示OFF控制=OFF即空调开机";
CM_ SG_ 2566865433 ESC_PTC_LowRelayCtrl "电动压缩机、WPTC、APTC低压侧继电器控制Low-voltage relay control";
CM_ SG_ 2566865433 FAN_LowRelayCtrl "低压风扇继电器控制";
CM_ SG_ 2566865433 Blower_RelayCtrl "鼓风机继电器控制";
CM_ SG_ 2566865433 Blower_RelayCtrl_Slpr "后鼓风机继电器控制 L5无B有";
CM_ SG_ 2566865433 BattPump_RelayCtrl "电池水泵继电器";
CM_ SG_ 2566865433 WarmPump_RelayCtrl "采暖水泵继电器 L5无B有";
CM_ SG_ 2566865433 DrivePump_RelayCtrl "电驱动水泵继电器";
CM_ SG_ 2566865433 SOVFront_Ctrl "前空调电磁阀关闭控制 L5&B电磁阀OFF=功能开启（默认常开）";
CM_ SG_ 2566865433 SOVRear_Ctrl "后空调电磁阀关闭控制 B电磁阀OFF=功能开启（默认常开）";
CM_ SG_ 2566865433 Wasteheat_use_2way_SOV "电堆电控开关阀位置控制/电堆余热利用水阀控制";
CM_ SG_ 2566865433 BattPump_PWM "电池水泵功率控制";
CM_ SG_ 2566865433 Temp_Ambt_Accurate "室外温度（计算后使用）";
CM_ SG_ 2566865689 LFAN1_PWM "低压风扇组1调速占空比 L5+Beacon";
CM_ SG_ 2566865689 LFAN2_PWM "低压风扇组2调速占空比  L5无";
CM_ SG_ 2566865689 LFAN3_PWM "低压风扇组3调速占空比 L5无";
CM_ SG_ 2566865689 LFAN4_PWM "低压风扇组4调速占空比 L5无";
CM_ SG_ 2566865689 DrivePump_PWM "电驱动水泵功率控制";
CM_ SG_ 2566865689 WarmPump_PWM "采暖水泵功率控制  L5无";
CM_ SG_ 2566865689 EAC1_ACFrontDefrostSysSts "除霜除雾功能系统状态";
CM_ SG_ 2566865689 EAC2_ACFrontDefrostSysSts "除霜除雾功能系统状态";
CM_ SG_ 2566865689 STValve_Position_Target_ "三通水阀目标位置例如：Byte=EC,对应的十进制为236,电压=236*0.01953=4.6V";
CM_ SG_ 2566864665 FrontHVACTempPanel_PWM "前空调冷暖风门需求位置百分比";
CM_ SG_ 2566864665 RearHVACTempPanel_PWM "后空调冷暖风门需求位置百分比";
CM_ SG_ 2566864665 FrontHVACCyclePanel_PWM "前空调循环风需求位置百分比";
CM_ SG_ 2566866713 FrontHVACSts "驾驶舱空调工作模式";
CM_ SG_ 2566866713 RearHVACSts "后空调工作模式";
CM_ SG_ 2566866713 LiquidColdOrHeatingMode "液冷/液热系统工作模式";
CM_ SG_ 2566866713 BTMSSts "电池热管理工作模式";
CM_ SG_ 2566866713 FuelcellTMSts "电堆热管理工作模式";
CM_ SG_ 2566866713 MotorcoolingSts "电机电控冷却工作模式";
CM_ SG_ 2566907722 T_boxEncryptData_Byte1 "加密结果字节1";
CM_ SG_ 2566907722 T_boxEncryptData_Byte2 "加密结果字节2";
CM_ SG_ 2566907722 T_boxEncryptData_Byte3 "加密结果字节3";
CM_ SG_ 2566907722 T_boxEncryptData_Byte4 "加密结果字节4";
CM_ SG_ 2566907722 T_boxEncryptData_Byte5 "加密结果字节5";
CM_ SG_ 2566907722 T_boxEncryptData_Byte6 "加密结果字节6";
CM_ SG_ 2566907722 T_boxEncryptData_Byte7 "加密结果字节7";
CM_ SG_ 2566907722 T_boxEncryptData_Byte8 "加密结果字节8";
CM_ SG_ 2566907722 T_boxEncryptData_Byte9 "加密结果字节9";
CM_ SG_ 2566907722 T_boxEncryptData_Byte10 "加密结果字节10";
CM_ SG_ 2566907722 T_boxEncryptData_Byte11 "加密结果字节11";
CM_ SG_ 2566907722 T_boxEncryptData_Byte12 "加密结果字节12";
CM_ SG_ 2566907722 T_boxEncryptData_Byte13 "加密结果字节13";
CM_ SG_ 2566907722 T_boxEncryptData_Byte14 "加密结果字节14";
CM_ SG_ 2566907722 T_boxEncryptData_Byte15 "加密结果字节15";
CM_ SG_ 2566907722 T_boxEncryptData_Byte16 "加密结果字节16";
CM_ SG_ 2566908234 VehicleID_Tbox "车辆ID";
CM_ SG_ 2566908490 SecretKey_Tbox_Byte1 "加密密钥字节1";
CM_ SG_ 2566908490 SecretKey_Tbox_Byte2 "加密密钥字节2";
CM_ SG_ 2566908490 SecretKey_Tbox_Byte3 "加密密钥字节3";
CM_ SG_ 2566908490 SecretKey_Tbox_Byte4 "加密密钥字节4";
CM_ SG_ 2566908490 SecretKey_Tbox_Byte5 "加密密钥字节5";
CM_ SG_ 2566908490 SecretKey_Tbox_Byte6 "加密密钥字节6";
CM_ SG_ 2566908490 SecretKey_Tbox_Byte7 "加密密钥字节7";
CM_ SG_ 2566908490 SecretKey_Tbox_Byte8 "加密密钥字节8";
CM_ SG_ 2566908490 SecretKey_Tbox_Byte9 "加密密钥字节9";
CM_ SG_ 2566908490 SecretKey_Tbox_Byte10 "加密密钥字节10";
CM_ SG_ 2566908490 SecretKey_Tbox_Byte11 "加密密钥字节11";
CM_ SG_ 2566908490 SecretKey_Tbox_Byte12 "加密密钥字节12";
CM_ SG_ 2566908490 SecretKey_Tbox_Byte13 "加密密钥字节13";
CM_ SG_ 2566908490 SecretKey_Tbox_Byte14 "加密密钥字节14";
CM_ SG_ 2566908490 SecretKey_Tbox_Byte15 "加密密钥字节15";
CM_ SG_ 2566908490 SecretKey_Tbox_Byte16 "加密密钥字节16";
CM_ SG_ 2565537610 Tbox_RQST_PGN "PGN:0x00FFE9PGN:0x00FFEA";
CM_ SG_ 2566907210 ControlIdentifier "控制识别码";
CM_ SG_ 2566907210 AwakeNetwork "网络唤醒信号";
CM_ SG_ 2566907210 TBOX_ACTempLevelReq_TM1 "TBOX冷暖挡位请求";
CM_ SG_ 2566907210 TBOX_ACFrontDefrostReq_TM1 "前除霜功能请求";
CM_ SG_ 2566907210 TBOX_Cockpit_Cleaning_TM1 "座舱清洁功能请求";
CM_ SG_ 2566907210 TBOX_AcMaxSwt "最大制冷开关/前排急速制冷开关";
CM_ SG_ 2566907210 TBOX_HeatingMaxSwt "前排急速制热请求";
CM_ SG_ 2566907210 TBOX_DrSeatHeatSw "主驾座椅加热";
CM_ SG_ 2566907210 TBOX_SteerWheelHeatSwt "方向盘加热";
CM_ SG_ 2566907210 TBOX_ChargngByApntmntHourStartFb "预约直流充电设置开始时间-时";
CM_ SG_ 2566907210 TBOX_ChargngByApntmntMinuteStartFb "预约直流充电设置开始时间-分";
CM_ SG_ 2566907210 TBOX_DCChargingByApntmnReplication_St "预约直流充电功能频次设置";
CM_ SG_ 2566907210 TBOX_ChargngByApntmntHourEndFb "预约直流充电设置结束时间-时";
CM_ SG_ 2566907210 TBOX_ChargngByApntmntMinuteEndFb "预约直流充电设置结束时间-分";
CM_ SG_ 2566909258 TBOX_RemoteReqFlag "远程请求控制标志位";
CM_ SG_ 2566901834 TBOX_4_DischargeCutoffSOC "放电截止SOC设置";
CM_ SG_ 2566901834 TBOX4_N_ExpectedSOCForVehicleUse "用车时期望SOC设置";
CM_ SG_ 2566901834 TBOX_4_Discharge_St "对外放电设置对外放电功能设置开关";
CM_ SG_ 2566901834 TBOX4_ChargingKeepWarmSet_St "插抢保温设置";
CM_ SG_ 2566901834 TBOX4_DisChargingStop_St "放电停止开关设置";
CM_ SG_ 2566901834 TBOX4_N_ExternalDischargeAppointmentForPickupMinutes "对外放电预计用车时间（分）";
CM_ SG_ 2566901834 TBOX4_N_ExternalDischargeAppointmentForPickupHours "对外放电预计用车时间（时）";
CM_ SG_ 2566901834 TBOX4_V2L_St "V2L设置";
CM_ SG_ 2566902602 TBOX5_DCChargingByApntmnt_St "预约直流充电功能设置开关";
CM_ SG_ 2566902602 TBOX5_InstantCharging_St "立即充电功能设置开关";
CM_ SG_ 2566902602 TBOX5_ChargingStop_St "充电停止功能设置开关";
CM_ SG_ 2566907431 VDCU_RandomData "VDCU认证随机数";
CM_ SG_ 2566908199 VehicleID_VDCU "车辆ID";
CM_ SG_ 2566908455 SecretKey_VDCU_Byte1 "加密密钥字节1";
CM_ SG_ 2566908455 SecretKey_VDCU_Byte2 "加密密钥字节2";
CM_ SG_ 2566908455 SecretKey_VDCU_Byte3 "加密密钥字节3";
CM_ SG_ 2566908455 SecretKey_VDCU_Byte4 "加密密钥字节4";
CM_ SG_ 2566908455 SecretKey_VDCU_Byte5 "加密密钥字节5";
CM_ SG_ 2566908455 SecretKey_VDCU_Byte6 "加密密钥字节6";
CM_ SG_ 2566908455 SecretKey_VDCU_Byte7 "加密密钥字节7";
CM_ SG_ 2566908455 SecretKey_VDCU_Byte8 "加密密钥字节8";
CM_ SG_ 2566908455 SecretKey_VDCU_Byte9 "加密密钥字节9";
CM_ SG_ 2566908455 SecretKey_VDCU_Byte10 "加密密钥字节10";
CM_ SG_ 2566908455 SecretKey_VDCU_Byte11 "加密密钥字节11";
CM_ SG_ 2566908455 SecretKey_VDCU_Byte12 "加密密钥字节12";
CM_ SG_ 2566908455 SecretKey_VDCU_Byte13 "加密密钥字节13";
CM_ SG_ 2566908455 SecretKey_VDCU_Byte14 "加密密钥字节14";
CM_ SG_ 2566908455 SecretKey_VDCU_Byte15 "加密密钥字节15";
CM_ SG_ 2566908455 SecretKey_VDCU_Byte16 "加密密钥字节16";
CM_ SG_ 2565537575 VDCU_RQST_PGN "PGN:0x00FFE9PGN:0x00FFEA";
CM_ SG_ 2566907943 VDCU_St_AuthenticationResultResponse "握手状态反馈";
CM_ SG_ 2566907943 ValidDKM "蓝牙钥匙有效判断";
CM_ SG_ 2566862831 VBUS_VCU1_N_AvgCellVoltage "平均单体电压";
CM_ SG_ 2566862831 VBUS_VCU1_N_APS_PER "加速踏板开度";
CM_ SG_ 2566862831 VBUS_VCU1_St_AutoMode "自动驾驶模式";
CM_ SG_ 2566862831 VBUS_VCU1_St_APS_STA "加速踏板状态";
CM_ SG_ 2566862831 VBUS_VCU1_N_AverageCellTemperature "电池单体平均温度值";
CM_ SG_ 2566862831 VBUS_VCU1_RemainChargeTime "剩余充电时间";
CM_ SG_ 2566858479 VBUS_VCU6_F_BpSynFlt_Fault "制动踏板同步校验故障";
CM_ SG_ 2566856687 VBUS_VCU3_N_DCCurrent "母线电流";
CM_ SG_ 2566856687 VBUS_VCU3_N_DCVoltage "母线电压";
CM_ SG_ 2566856687 VBUS_VCU3_N_ConsumedPower "当前系统输出功率";
CM_ SG_ 2566856687 VBUS_VCU3_St_DRIVE_MODE "驾驶模式";
CM_ SG_ 2566856687 VBUS_VCU3_St_Isolation_clc "绝缘故障检修提示";
CM_ SG_ 2566856687 VBUS_VCU3_St_Vehicle_stop "车辆因故障停车提示";
CM_ SG_ 2566858991 VBUS_VCU13_N_MotorSpeed "电机转速";
CM_ SG_ 2566858991 VBUS_VCU13_N_MotorTorque "电机扭矩";
CM_ SG_ 2566858991 VBUS_VCU13_N_MCUTemperature "电机控制器温度";
CM_ SG_ 2566858991 VBUS_VCU13_N_MotorTemperature "电机温度";
CM_ SG_ 2566858991 VBUS_VCU13_N_BRAKE_TOR_MAX "驱动系统当前最大回馈扭矩";
CM_ SG_ 2566857967 VBUS_VCU14_N_MotorSpeed "电机转速";
CM_ SG_ 2566857967 VBUS_VCU14_N_MotorTorque "电机扭矩";
CM_ SG_ 2566857967 VBUS_VCU14_N_MCUTemperature "电机控制器温度";
CM_ SG_ 2566857967 VBUS_VCU14_N_MotorTemperature "电机温度";
CM_ SG_ 2566858223 VBUS_VCU7_BiOBC_HVIL_Err "车内取电逆变器互锁故障";
CM_ SG_ 2566858223 VBUS_VCU7_HVAccS_HVIL_Err "高压附件互锁故障";
CM_ SG_ 2566858223 VBUS_VCU7_Gear1_Indicator "车速过高，已启用N挡，请重新挂挡";
CM_ SG_ 2566858223 VBUS_VCU7_BRAKE_ENGERY_RECOV_LEVEL "制动能量回收挡位";
CM_ SG_ 2566858223 VBUS_VCU7_Restricted_Warning "远程锁车状态提示";
CM_ SG_ 2566858223 VBUS_VCU7_St_LV_Chrg "低压蓄电池补电状态";
CM_ SG_ 2566858223 VBUS_VCU7_IMCUO_422_ready "转向DCAC使能状态（对VCU使能的反馈）";
CM_ SG_ 2566858223 VBUS_VCU7_MTCU_HVIL_Err "MTCU互锁故障";
CM_ SG_ 2566858223 VBUS_VCU7_PDU_HVIL_Err "PDU互锁故障";
CM_ SG_ 2566858223 VBUS_VCU7_BATT_HVIL_Err "动力电池系统互锁故障";
CM_ SG_ 2566858223 VBUS_VCU7_FUELCELL_HVIL_Err "燃料电池系统互锁故障";
CM_ SG_ 2566858223 VBUS_VCU7_ADCAC_BRAKE_EN_CMD "制动DCAC使能命令";
CM_ SG_ 2566858223 VBUS_VCU7_IMCUA_420_ready "制动DCAC使能状态（对VCU使能的反馈）";
CM_ SG_ 2566858223 VBUS_VCU7_FAULT_IMCUO "IMCUO系统故障";
CM_ SG_ 2566858223 VBUS_VCU7_N_MaxCellTemperature "电池单体最高温度";
CM_ SG_ 2566858223 VBUS_VCU7_N_MinCellTemperature "电池单体最低温度";
CM_ SG_ 2566857711 VBUS_VCU9_N_H2RemainTotalDriverRange "氢能剩余可行驶里程";
CM_ SG_ 2566857711 VBUS_VCU9_N_Avail_Remin_Power "可用剩余功率";
CM_ SG_ 2566857711 VBUS_VCU9_N_Single_CHG_PWR "已充电能量(单次)";
CM_ SG_ 2566857711 VBUS_VCU9_DrivngMileageDisplayFb "续驶里程显示方式设置反馈";
CM_ SG_ 2566857711 VBUS_VCU9_N_VehInsPow_PER "动力系统负荷-百分比";
CM_ SG_ 2566853871 VBUS_VCU12_ICS_Fault_Flg "ICS控制模块故障";
CM_ SG_ 2566853871 VBUS_VCU12_HVConnect_Sta "高压连接状态";
CM_ SG_ 2566858735 VBUS_VCU8_N_Hyd_SOC "氢气SOC";
CM_ SG_ 2566858735 VBUS_VCU8_HydFilling "加氢指示";
CM_ SG_ 2566858735 VBUS_VCU8_N_FCVPower "燃料电池功率";
CM_ SG_ 2566858735 VBUS_VCU8_N_Bottle_Temperature "氢瓶温度";
CM_ SG_ 2566858735 VBUS_VCU8_N_Bottle_Pressure "氢瓶压力";
CM_ SG_ 2566858735 VBUS_VCU8_F_Hyd_LowSOC "氢气SOC低警示灯";
CM_ SG_ 2566858735 VBUS_VCU8_F_HydLeakage "H2泄露";
CM_ SG_ 2566858735 VBUS_VCU8_St_FCVMode "FCVMode";
CM_ SG_ 2566858735 VBUS_VCU8_F_FCV "燃料电池故障";
CM_ SG_ 2566858735 VBUS_VCU8_F_Bottle_Pressure_High "氢瓶压力过高故障";
CM_ SG_ 2566858735 VBUS_VCU8_St_HydrLowFcoff "氢压低燃料电池关机提示";
CM_ SG_ 2566858735 VBUS_VCU8_St_EVModeLowSOC "EV模式电池SOC低提醒";
CM_ SG_ 2566858735 VBUS_VCU8_F_Hyd "氢系统故障";
CM_ SG_ 2566866215 VBUS_VCU20_V2GSwtFb "直流V2G开关状态反馈";
CM_ SG_ 2566866215 VBUS_VCU20_PowerOutSts_220V "车内取电工作状态反馈";
CM_ SG_ 2566866215 VBUS_VCU20_PowerSwtFb_220V "车内取电开关状态反馈";
CM_ SG_ 2566866215 VBUS_VCU20_AutoBatteryRechargeSwtFb "低压蓄电池智能补电功能开关状态反馈";
CM_ SG_ 2566866215 VBUS_VCU20_DiffLockStateRearAxle1 "轮间差速锁工作状态反馈（桥1）";
CM_ SG_ 2566866215 VBUS_VCU20_DiffLockStateRearAxle2 "轮间差速锁工作状态反馈（桥2）";
CM_ SG_ 2566866215 VBUS_VCU20_DiffLockSwtFb "轮间差速锁开关状态反馈";
CM_ SG_ 2566866215 VBUS_VCU20_SPSM_St "超级节电功能状态反馈";
CM_ SG_ 2566866215 VBUS_VCU20_VehicleCreepSetFb "蠕行开关设置接收状态反馈";
CM_ SG_ 2566866215 VBUS_VCU20_GSMFltSts "怀挡故障状态（仪表提示）";
CM_ SG_ 2566866215 VBUS_VCU20_DragModelSwtFb "拖车模式开关反馈";
CM_ SG_ 2566866215 VBUS_VCU20_SPSM_SwtFb "超级节电开关反馈";
CM_ SG_ 2566866215 VBUS_VCU20_Swt_EV_FCV "EV开关状态反馈";
CM_ SG_ 2566866215 VBUS_VCU20_DriveAnti_theftSts "动力防盗认证结果反馈";
CM_ SG_ 2566866215 VBUS_VCU20_StopChargingSwtFb "直流充电停止开关反馈";
CM_ SG_ 2566866215 VBUS_VCU20_V2GByApntmntMinuteStart "预计用车时间（分）-设置反馈";
CM_ SG_ 2566866215 VBUS_VCU20_V2GDischargeCutoffSOC "对外放电截止SOC设置反馈";
CM_ SG_ 2566866215 VBUS_VCU20_V2GExpectedSOCForVehicleUse "用车时期望SOC设置反馈";
CM_ SG_ 2566866215 VBUS_VCU20_V2GByApntmntHourStart "预计用车时间（时）-设置反馈";
CM_ SG_ 2566866215 VBUS_VCU20_DrvMod_ECO "建议切换经济模式提示";
CM_ SG_ 2566866215 VBUS_VCU20_EMotor_OverSpeed "电机超速报警";
CM_ SG_ 2566866983 VBUS_VCU21_ChargngByApntmntSwtFb "预约直流充电功能开关状态反馈";
CM_ SG_ 2566866983 VBUS_VCU21_ChargngByApntmntReplicationSetFb "预约直流充电功能循环设置状态反馈";
CM_ SG_ 2566866983 VBUS_VCU21_ImmediatStartChargngFb "立即充电反馈状态（也是对软开关的反馈）";
CM_ SG_ 2566866983 VBUS_VCU21_ChargngByApntmntStartFb "预约直流充电功能开启状态反馈";
CM_ SG_ 2566866983 VBUS_VCU21_ChargngByApntmntHourStartFb "预约直流充电设置开始时间-时";
CM_ SG_ 2566866983 VBUS_VCU21_ChargngByApntmntMinuteStartFb "预约直流充电设置开始时间-分";
CM_ SG_ 2566866983 VBUS_VCU21_ChargngByApntmntHourEndFb "预约直流充电设置结束时间-时";
CM_ SG_ 2566866983 VBUS_VCU21_ChargngByApntmntMinuteEndFb "预约直流充电设置结束时间-分";
CM_ SG_ 2566866983 VBUS_VCU21_V2VSwtFb "直流V2V开关状态反馈";
CM_ SG_ 2566866983 VBUS_VCU21_DCV2LSwtFb "直流V2L开关状态反馈";
CM_ SG_ 2566866983 VBUS_VCU21_VCU_BattaryHeatingSts "动力电池加热状态";
CM_ SG_ 2566866983 VBUS_VCU21_ChargingKeepWarmSwtFb "动力电池充电保温开关状态反馈";
CM_ SG_ 2566866983 VBUS_VCU21_ChargingKeepWarmSts "动力电池充电保温状态";
CM_ SG_ 2566866983 VBUS_VCU21_StopDCDisChargingSwtFb "直流放电停止开关反馈";
CM_ SG_ 2566868263 VBUS_VCU22_N_InstantaneousConsumedPower "瞬时电耗";
CM_ SG_ 2566868263 VBUS_VCU22_N_AverageConsumedPower_50km "平均电耗（50km）";
CM_ SG_ 2566868263 VBUS_VCU22_N_DisChgPower "对外放电功率（插枪放电，非行驶）";
CM_ SG_ 2566868263 VBUS_VCU22_MaintModeSwtFb "维修模式开关反馈";
CM_ SG_ 2566868263 VBUS_VCU22_VehEnginMod "整车工程模式";
CM_ SG_ 2566868263 VBUS_VCU22_N_InstantConsumedPowerStop "瞬时电耗（停车）";
CM_ SG_ 2566868263 VBUS_VCU22_MaintModeSt "维修模式状态";
CM_ SG_ 2566870288 IntarderPilotLampState "Status of the Intarder pilot lamp.仪表指示灯状态";
CM_ SG_ 2566708224 ACCReadinessStatus "This parameter is used to indicate an application's state of readiness for responding to commands from an adaptive cruise control system controller.";
CM_ SG_ 2566708224 AEBSReadinessState "Advanced emergency braking systems (AEBS) will limit the engine torque via TSC1 during warning and braking phases. Therefore the engine controller gives a feedback to the AEBS if it is configured and able to obey these limitation commands.";
CM_ SG_ 2566719232 EngAmberWarningLampCmd "Command signal directly controlling the Engine Amber Warning Lamp发动机黄色警告灯命令(对应动力CAN:EMS_0x27B_EngineState)";
CM_ SG_ 2566719232 EngRedStopLampCmd "Command signal directly controlling the Engine Red Stop Lamp发动机红色警告灯命令";
CM_ SG_ 2566719232 OBDMalfunctionIndicatorLampCmd "Command signal directly controlling the OBD Malfunction Indicator LampOBD故障指示灯命令(对应动力CAN:EMS_0x27B_MILState)";
CM_ SG_ 2566719232 EngBrakeActiveLampCmd "Command signal directly controlling the Engine Brake Active Lamp";
CM_ SG_ 2566719232 EngOilPressLowLampCmd "Command signal directly controlling the Engine Oil Pressure Low Lamp.机油压力低指示灯(对应动力CAN:EMS_0x27B_OilPressureWarning)";
CM_ SG_ 2566719232 EngCoolantTempHighLampCmd "Command signal directly controlling the Engine Coolant Temperature High Lamp水温高指示灯(对应动力CAN:RECU_0x27B_EngCoolantTempHighLampCmd ）";
CM_ SG_ 2566719232 EngCoolantLevelLowLampCmd "Command signal directly controlling the Engine Coolant Level Low Lamp.水位低指示灯(对应动力CAN:RECU_0x27B_EngCoolantLevelLowLampCmd）";
CM_ SG_ 2566719232 EngineAirFilterRestrictionLampCommand "Command signal directly controlling the Engine Air Filter Restriction Lamp";
CM_ SG_ 2566853359 VBUS_VCU4_N_VehicleSpeed "实际车速";
CM_ SG_ 2566853359 VBUS_VCU4_N_AverageConsumedPower "平均电耗（100KM）";
CM_ SG_ 2566853359 VBUS_VCU4_St_Gears "档位状态";
CM_ SG_ 2566853359 VBUS_VCU4_St_Ready "ready信号";
CM_ SG_ 2566853359 VBUS_VCU4_St_Vehicle "整车状态";
CM_ SG_ 2566853359 VBUS_VCU4_St_Interlocking "互锁状态";
CM_ SG_ 2566853359 VBUS_VCU4_St_ShiftGearBrkOn "换挡请踩制动";
CM_ SG_ 2566853359 VBUS_VCU4_F_ShiftGears "换挡不成功状态提示";
CM_ SG_ 2566853359 VBUS_VCU4_F_Motor "电机故障";
CM_ SG_ 2566853359 VBUS_VCU4_F_MotorOverTemp "电机过热报警";
CM_ SG_ 2566853359 VBUS_VCU4_St_DISCHARGE_STA "车辆放电状态";
CM_ SG_ 2566853359 VBUS_VCU4_N_EVRemainDriverRange "纯电剩余可行驶里程";
CM_ SG_ 2566853359 VBUS_VCU4_St_BrakeSta "制动踏板状态";
CM_ SG_ 2566853359 VBUS_VCU4_St_Thermal_runaway "动力电池热失控预警";
CM_ SG_ 2566853359 VBUS_VCU4_RollingCounter "VCU计数器I";
CM_ SG_ 2566853615 VBUS_VCU5_N_DCVoltage "动力电池总电压";
CM_ SG_ 2566853615 VBUS_VCU5_N_DCCurrent "动力电池总电流";
CM_ SG_ 2566853615 VBUS_VCU5_N_SOC "动力电池剩余电量";
CM_ SG_ 2566853615 VBUS_VCU5_St_LowSOC "SOC低警示灯";
CM_ SG_ 2566853615 VBUS_VCU5_St_BatteryCHGHeating "动力电池充电加热模式提示";
CM_ SG_ 2566853615 VBUS_VCU5_F_Battery "电池故障";
CM_ SG_ 2566853615 VBUS_VCU5_F_OverTemperature "电池过热";
CM_ SG_ 2566853615 VBUS_VCU5_F_LVBattVoltageLow "低压蓄电池电压低指示";
CM_ SG_ 2566853615 VBUS_VCU5_St_HVDisConnect "高压断开状态";
CM_ SG_ 2566853615 VBUS_VCU5_F_Isolation "绝缘故障";
CM_ SG_ 2566853615 VBUS_VCU5_St_ChargerIndicator "充电指示";
CM_ SG_ 2566853615 VBUS_VCU5_St_ChargerLine "充电线连接状态";
CM_ SG_ 2566853615 VBUS_VCU5_St_EnergyFlow "能量流显示";
CM_ SG_ 2566853615 VBUS_VCU5_St_ChargeMode "充电模式";
CM_ SG_ 2566853615 VBUS_VCU5_St_PowerReduceOperation "降功率运行标志位";
CM_ SG_ 2566872103 PosnLiForgotWarn "位置灯忘关报警";
CM_ SG_ 2566872103 N_gearIgnRmn "请挂在P/N档再点火";
CM_ SG_ 2566872103 N_gearPwroffRmn "请挂在P档再掉电";
CM_ SG_ 2566872103 PsdBrkIgnRmn "请踩下刹车再按下启动开关点火";
CM_ SG_ 2566872103 PwrOnAlrm "电源未关报警提示";
CM_ SG_ 2566872103 PwrStsVld "电源状态有效";
CM_ SG_ 2566872103 LockAutoCloseWinSetSts "锁车自动关窗功能设置成功反馈";
CM_ SG_ 2566872103 SpeedLimitSet_SleeperSts "卧铺开关车速限制设置反馈";
CM_ SG_ 2566872103 SteerWheelHeatReq "方向盘加热指令（VDCU->CDCU）";
CM_ SG_ 2566872103 DrSeatHeatReq "主驾座椅加热指令（VDCU->CDCU）";
CM_ SG_ 2566893351 LowBeamFltWarn_VDCU "近光灯故障提醒";
CM_ SG_ 2566893351 MainBrkLightFltWarn_VDCU "主车制动灯故障提醒";
CM_ SG_ 2566893351 TrailerBrkLightFltWarn_VDCU "挂车制动灯故障提醒";
CM_ SG_ 2566893351 HighBeamFltWarn_VDCU "远光灯故障提醒";
CM_ SG_ 2566893351 OvertakinglampWarn_VDCU "超车灯故障提醒";
CM_ SG_ 2566893351 FrontOperatorWiperFltWarn_VDCU "雨刮故障提醒";
CM_ SG_ 2566893351 WinCtrlFlt_Drvr_VDCU "主驾侧车窗故障提醒";
CM_ SG_ 2566893351 WinCtrlFlt_Pass_VDCU "副驾侧车窗故障提醒";
CM_ SG_ 2566893351 VDCU_ACFrontDefrostSysSts "除霜除雾功能系统状态包括控制策略引发的潜伏故障信号和单点故障信号;";
CM_ SG_ 2566893351 LowPowerModeWarn_VDCU "低压电源档位故障";
CM_ SG_ 2566875943 VBUS_VCU24_N_TripA_AveConsPower "平均电耗（小计里程A）";
CM_ SG_ 2566875943 VBUS_VCU24_N_TripB_AveConsPower "平均电耗（小计里程B）";
CM_ SG_ 2566875943 VBUS_VCU24_N_AccesConsumPower "附件电器用电功率（DCAC、DCDC、车内取电）";
CM_ SG_ 2566875943 VBUS_VCU24_N_TMSConsumPower "热管理系统用电功率";
CM_ SG_ 2566875943 VBUS_VCU24_N_Single_DisCHG_PWR "已放电电量(单次，插枪放电)";
CM_ SG_ 2566875943 VBUS_VCU24_N_AllowedTowing_Mode "拖车模式状态";
CM_ SG_ 2566875943 VBUS_VCU24_N_Towing_Error "拖车超限故障";
CM_ SG_ 2566912807 VBUS_VCU24_BMS538_TOTAL_CHG_PWR "电池累积充电电量";
CM_ SG_ 2566861351 LeftTurnLightReq "左转向灯驱动请求";
CM_ SG_ 2566861351 RightTurnLightReq "右转向灯驱动请求";
CM_ SG_ 2566861351 HzrdLightReq "危报灯驱动请求";
CM_ SG_ 2566861351 LowBeamReq "近光灯控制请求";
CM_ SG_ 2566861351 HighBeamReq "远光灯控制请求";
CM_ SG_ 2566861351 ReverseLampReq "倒车灯控制请求";
CM_ SG_ 2566861351 MainBrkLightReq "主车制动灯驱动请求";
CM_ SG_ 2566861351 TrailerBrkLightReq "挂车制动灯驱动请求";
CM_ SG_ 2566861351 PosnLigjtReq "位置灯控制请求";
CM_ SG_ 2566861351 BacklightAdjustReq "背光亮度调节请求";
CM_ SG_ 2566861351 LeftDayTimeRunngLiReq "左昼行灯驱动请求";
CM_ SG_ 2566861351 RightDayTimeRunngLiReq "右昼行灯驱动请求";
CM_ SG_ 2566861351 RearFogLampReq "后雾灯控制请求";
CM_ SG_ 2566861351 RearFogLampReplcmtReq "后雾灯代替制动灯请求";
CM_ SG_ 2566861351 LanternLanguageReq "灯语请求";
CM_ SG_ 2566861351 IVI_FrontFogLampLinkageSetFB "前雾灯随后雾灯联动设置反馈";
CM_ SG_ 2566861351 LampFollowMeHomeSetSts "伴我回家功能设置成功状态反馈";
CM_ SG_ 2566861351 LampAwayHomeSetSts "照我离家功能设置成功反馈";
CM_ SG_ 2566861351 ExtrMirrHeatCtrl "后视镜加热控制";
CM_ SG_ 2566861351 ExtrMirrDirAdjmtCtrl_L "左侧后视镜视野调节控制";
CM_ SG_ 2566861351 ExtrMirrDirAdjmtCtrl_R "右侧后视镜视野调节控制";
CM_ SG_ 2566861351 FrontFogLampReq_L "左前雾灯控制请求";
CM_ SG_ 2566861351 FrontFogLampReq_R "右前雾灯控制请求";
CM_ SG_ 2566861607 WinReq_L "主驾车窗升降控制请求";
CM_ SG_ 2566861607 WinReq_R "副驾车窗升降控制请求";
CM_ SG_ 2566861607 WasherReq "喷淋电机驱动请求";
CM_ SG_ 2566861607 WiperReq "雨刮驱动请求";
CM_ SG_ 2566861607 OutIncrWinAntAlarm "外部升窗防夹报警";
CM_ SG_ 2566861607 StartStopButtonLiReq "一键启动开关指示灯驱动命令";
CM_ SG_ 2566861607 RelayReq_ACC "ACC继电器吸合命令";
CM_ SG_ 2566861607 RelayReq_IG1 "IG1继电器吸合命令";
CM_ SG_ 2566861607 RelayReq_IG2 "IG2继电器吸合命令";
CM_ SG_ 2566861607 CrankReq "Crank命令";
CM_ SG_ 2566861607 RelaySts_ACC "ACC继电器状态";
CM_ SG_ 2566861607 RelaySts_IG1 "IG1继电器状态";
CM_ SG_ 2566861607 RelaySts_IG2 "IG2继电器状态";
CM_ SG_ 2566861607 LowPowerMode "低压电源状态";
CM_ SG_ 2566861607 RmtLowPowerMode "低压电源远控标志位";
CM_ SG_ 2566861607 RainCloseWinSwt_Fb "雨天自动关窗设置反馈";
CM_ SG_ 2566861607 RmtLocaloutreq_VDCU "本地事件触发退出远控请求(VDCU)";
CM_ SG_ 2566861607 BluetoothKeyConnect "蓝牙钥匙是否连接";
CM_ SG_ 2566861607 BluetoothKeyLocation "蓝牙钥匙位置";
CM_ SG_ 2566861607 BluetoothKeyReq "蓝牙钥匙请求";
CM_ SG_ 2566861607 BluetoothPhoneConnect "手机蓝牙是否连接";
CM_ SG_ 2566861607 PrimaryAntennaSleepSts "主天线休眠指令";
CM_ SG_ 2566845721 AmbAirT "Temperature of air surrounding vehicle.室外温度 Needed for AVE EP and Cetrax for Rotor-Temperature Derating Function";
CM_ SG_ 2566872611 RLS_RQ_WiperSPD "The Sensor requested wiper speed 雨量传感器请求的雨刮速度.";
CM_ SG_ 2566872611 RLS_RQ_LowBeam "Auto low beam request 近光灯点亮请求";
CM_ SG_ 2566872611 RLS_RQ_PositionLamp "Auto position lamp request 位置灯点亮请求";
CM_ SG_ 2566872611 RLS_Fault_Rain "Rain sensor fault status 雨量传感器故障状态";
CM_ SG_ 2566872611 RLS_Fault_Light "Light sensor fault status 光亮传感器故障状态";
CM_ SG_ 2566872611 RLS_REP_Error "RLS LIN response error RLS通讯故障状态";
CM_ SG_ 2566872611 RLS_VOLT_Error "RLS Voltage error RLS检测电池电压错误";
CM_ SG_ 2566872611 RLS_Brightness_FW "The Visible Ambientlight (540nm) measured by Spot FW 可见环境光亮度";
CM_ SG_ 2566872611 RLS_Rain_Intensity "This signal delivers information about rain intensity: from 0%(no rain) to 100% (very heavy rain) 降雨强度：从0%到100%";
CM_ SG_ 2566872611 RLS_BigLamp_Threshold_Nr "大灯开启阀值信号";
CM_ SG_ 2566872611 RLS_RainCloseWin_Str "雨天关窗信号";
CM_ SG_ 2566872611 RLS_WiperSPD_FuncErr "雨刮功能安全故障";
CM_ SG_ 2566872611 RLS_RQ_LowBeam_FuncErr "近光灯功能安全故障";
CM_ SG_ 2566872611 RLS_CheckSum "E2E Checksum";
CM_ SG_ 2566873629 SGM_S_Unlock_Swt "The Switch of the  Unlock";
CM_ SG_ 2566873629 SGM_S_Lock_Swt "The Switch of the  Lock";
CM_ SG_ 2566873629 SGM_S_WLM_FL_Swt "The Switch of the  window";
CM_ SG_ 2566873629 SGM_S_WLM_FR_Swt "The Switch of the  window";
CM_ SG_ 2566873629 SGM_S_VolumePlus_Swt "The Switch of the  Volume plus";
CM_ SG_ 2566873629 SGM_S_VolumeMinus_Swt "The Switch of the  Volume minus";
CM_ SG_ 2566873629 SGM_S_ACOnOrOff_Swt "The Switch of the  AC on or off";
CM_ SG_ 2566873629 SGM_S_BlowerLvlPlus_Swt "The Switch of the  AC Blowe plus";
CM_ SG_ 2566873629 SGM_S_BlowerLvlMinus_Swt "The Switch of the  AC Blowe minus";
CM_ SG_ 2566873629 SGM_S_ACTempPlus_Swt "The Switch of the  AC Temperature plus";
CM_ SG_ 2566873629 SGM_S_ACTempMinus_Swt "The Switch of the  AC Temperature minus";
CM_ SG_ 2566873629 SGM_S_ACTimingRun_Swt "The Switch of the  AC Timing Run";
CM_ SG_ 2566873629 SGM_S_CMSStart_Swt "The Switch of the  CMS start";
CM_ SG_ 2566873629 SGM_S_F_LINError "This signal shows one or more failures related to LIN communication.";
CM_ SG_ 2365537816 SWS_Mode_Swt "The Switch of the  Mode";
CM_ SG_ 2365537816 SWS_ReturnOrConfirm_Swt "The Switch of return or confirm";
CM_ SG_ 2365537816 SWS_DirectionUp_Swt "The switch of the Direction";
CM_ SG_ 2365537816 SWS_DirectionDown_Swt "The switch of the Direction";
CM_ SG_ 2365537816 SWS_DirectionLeft_Swt "The switch of the Direction";
CM_ SG_ 2365537816 SWS_DirectionRight_Swt "The switch of the Direction";
CM_ SG_ 2365537816 SWS_VROrHangUp_Swt "The switch of the VR Or Hang UP";
CM_ SG_ 2365537816 SWS_MuteOrHangDown_Swt "The switch of the mute Or HangDown";
CM_ SG_ 2365537816 SWS_Userde_Swt "The switch of the user-defined";
CM_ SG_ 2365537816 SWS_ADAS_Swt "(预留)The switch of the ADAS";
CM_ SG_ 2365537816 SWS_SpeedUp_Set "The switch of the CC Speed Set";
CM_ SG_ 2365537816 SWS_SpeedDown_Set "The switch of the CC Speed Set";
CM_ SG_ 2365537816 SWS_TimeGapInc_Set "The switch of the Time Gap Increase";
CM_ SG_ 2365537816 SWS_TimeGapDec_Set "The switch of the Time Gap Decrease";
CM_ SG_ 2365537816 SWS_LKA_Swt "The Switch of lane-keeping assist";
CM_ SG_ 2365537816 SWS_Heating_Swt "The Switch of sws heating";
CM_ SG_ 2566873374 SGM_IP_HornType_Swt "The Switch of the  Horn Type";
CM_ SG_ 2566873374 SGM_IP_RearLight_Swt "The Switch of the  Rear light";
CM_ SG_ 2566873374 SGM_IP_ACOff_Swt "The Switch of the  AC off";
CM_ SG_ 2566873374 SGM_IP_BlowerLvlPlus_Swt "The Switch of the  AC Blowe plus";
CM_ SG_ 2566873374 SGM_IP_BlowerLvlMinus_Swt "The Switch of the  AC Blowe minus";
CM_ SG_ 2566873374 SGM_IP_ACTempPlus_Swt "The Switch of the  AC Temperature plus";
CM_ SG_ 2566873374 SGM_IP_ACTempMinus_Swt "The Switch of the  AC Temperature minus";
CM_ SG_ 2566873374 SGM_IP_ACFrontDefrost_Swt "The Switch of the  AC Front Defrost";
CM_ SG_ 2566873374 SGM_IP_F_LINError "This signal shows one or more failures related to LIN communication.";
CM_ SG_ 2566892165 WCM1_key_status "Describe the status of WPC switch: ON or OFF无线充电器控制反馈（WPC当前状态）系统做记忆";
CM_ SG_ 2566892165 WCM1_charge_status "Describe the status of charge of the WPC:standby,charging,charging completed,WPC failure.手机无线充电状态";
CM_ SG_ 2566892165 WCM1_fault_status "Describe the current failure status of WPC.故障信息类别";
CM_ SG_ 2566892165 WCM1_phone_reminder "Describe whether there is a phone forgotten in the car.手机遗忘提醒";
CM_ SG_ 2566900371 LOG_LogoLightSet_Sts "Logo灯开关设置反馈";
CM_ SG_ 2566872532 LCM_L_St_RunningLight "昼行灯工作状态";
CM_ SG_ 2566872532 LCM_L_St_LeftTurnLight "转向灯工作状态";
CM_ SG_ 2566872532 LCM_L_St_TractorMarkerLight "位置灯工作状态";
CM_ SG_ 2566872532 LCM_L_St_LampFlicker "灯语执行状态";
CM_ SG_ 2566872532 LCM_L_F_OverVoltage "过压故障";
CM_ SG_ 2566872532 LCM_L_F_UnderVoltage "欠压故障";
CM_ SG_ 2566872532 LCM_L_F_RunningLight "昼行灯故障模式";
CM_ SG_ 2566872532 LCM_L_F_LeftTurnLight "转向灯故障模式";
CM_ SG_ 2566872532 LCM_L_F_TractorMarkerLight "位置灯故障模式";
CM_ SG_ 2566872789 LCM_R_St_RunningLight "昼行灯工作状态";
CM_ SG_ 2566872789 LCM_R_St_RightTurnLight "转向灯工作状态";
CM_ SG_ 2566872789 LCM_R_St_TractorMarkerLight "位置灯工作状态";
CM_ SG_ 2566872789 LCM_R_St_LampFlicker "灯语执行状态";
CM_ SG_ 2566872789 LCM_R_F_OverVoltage "过压故障";
CM_ SG_ 2566872789 LCM_R_F_UnderVoltage "欠压故障";
CM_ SG_ 2566872789 LCM_R_F_RunningLight "昼行灯故障模式";
CM_ SG_ 2566872789 LCM_R_F_LeftTurnLight "转向灯故障模式";
CM_ SG_ 2566872789 LCM_R_F_TractorMarkerLight "位置灯故障模式";
CM_ SG_ 2566867415 EPU_LeftStepStatus "左侧踏板状态";
CM_ SG_ 2566867672 EPU_RightStepStatus "右侧踏板状态";
CM_ SG_ 2365536412 ControlMode "驾驶模式";
CM_ SG_ 2365536412 Accelerator_Torque_enable "选择油门控制或扭矩控制";
CM_ SG_ 2365536412 GearControl "档位选择";
CM_ SG_ 2365536412 MessageChecksum_Auto_Control "Checksum = (Byte1 + Byte2 + Byte3 + Byte4 + (message counter & 0Fh) + Byte6 + Byte7 +Byte8+ message ID low byte + message ID mid low byte + message ID mid high byte + message ID high byte) Message Checksum = ((Checksum >> 4) + Checksum) & 0Fh";
CM_ SG_ 2365536412 EngRqedTorque_TorqueLimit_Auto_Control "Parameter provided to the engine or retarder in the torque/speed control message for controlling or limiting the output torque无效值：0xFB-ALL.";
CM_ SG_ 2365536412 SetFogSt "设置雾灯状态";
CM_ SG_ 2365536412 SetTurnRightST "设置右转向灯输出状态";
CM_ SG_ 2365536412 SetTurnLeftST "设置左转向灯输出状态";
CM_ SG_ 2365536412 SetLowBeamSt "设置近光灯输出状态";
CM_ SG_ 2365536412 SetHighBeamSt "设置远光灯输出状态";
CM_ SG_ 2365536412 SetWiperSt "设置雨刮状态";
CM_ SG_ 2365536412 SetHornSt "设置喇叭状态";
CM_ SG_ 2365537692 SWVibrationRequest "方向盘震动请求";
CM_ SG_ 2365537692 SetACFrontDefrostSt "设置前除霜状态";
CM_ SG_ 2365537692 SetWasherSt "设置前档清洗电机状态（预留）";
CM_ SG_ 2365537692 EPModeDemand "EP模式请求";
CM_ SG_ 2365537692 LidarWashSwitch "激光雷达清洗\喷气请求 预留";
CM_ SG_ 2365537692 SeatbeltTightenRequest "安全带预紧请求(预留)";
CM_ SG_ 2365537692 SetHazardSt "设置危险报警灯状态";
CM_ SG_ 2365537692 SetDoorUnlockingSt "设置驾驶员侧门锁状态";
CM_ SG_ 2365537692 SetWindowSt "设置门窗状态";
CM_ SG_ 2348810400 EngRqedSpeedCtrlConditions_C0000A0 "This mode tells the engine control system the governor characteristics that are desired during speed control.";
CM_ SG_ 2348810400 EngRqedSpeed_SpeedLimit_C0000A0 "Parameter provided to the engine from external sources in the torque/speed control message.Invalid Value:0xFB00~ALLFF";
CM_ SG_ 2348810400 EngRqedTorque_TorqueLimit_C0000A0 "Parameter provided to the engine or retarder in the torque/speed control message for controlling or limiting the output torque.无效值：0xFB-ALL";
CM_ SG_ 2348810400 TransmissionRate_C0000A0 "This parameter indicates the transmission rate at which the sending device will transmit the TSC1 message.";
CM_ SG_ 2348810400 ControlPurpose_C0000A0 "State signal which indicates which control mode the sending device is using to generate the TSC1 command.";
CM_ SG_ 2348810400 EngineRequestedTorqueHiRes_C0000A0 "This parameter displays an additional torque in percent of the reference engine torque.";
CM_ SG_ 2348810400 MessageCounter_C0000A0 "The message counter is used to detect situations where the transmitting ECU malfunction repeats the same frame all the time.";
CM_ SG_ 2348810400 MessageChecksum_C0000A0 "The checksum is used to verify the signal path from the transmitting device to the receiving device.";
CM_ SG_ 2348814492 EngRqedSpeedCtrlConditions_C00009C "This mode tells the engine control system the governor characteristics that are desired during speed control.";
CM_ SG_ 2348814492 EngRqedSpeed_SpeedLimit_C00009C "Parameter provided to the engine from external sources in the torque/speed control message.Invalid Value:0xFB00~ALLFF";
CM_ SG_ 2348814492 EngRqedTorque_TorqueLimit_C00009C "Parameter provided to the engine or retarder in the torque/speed control message for controlling or limiting the output torque.无效值：0xFB-ALL";
CM_ SG_ 2348814492 TransmissionRate_C00009C "This parameter indicates the transmission rate at which the sending device will transmit the TSC1 message.";
CM_ SG_ 2348814492 ControlPurpose_C00009C "State signal which indicates which control mode the sending device is using to generate the TSC1 command.";
CM_ SG_ 2348814492 EngineRequestedTorqueHiRes_C00009C "This parameter displays an additional torque in percent of the reference engine torque.";
CM_ SG_ 2348814492 MessageCounter_C00009C "The message counter is used to detect situations where the transmitting ECU malfunction repeats the same frame all the time.";
CM_ SG_ 2348814492 MessageChecksum_C00009C "The checksum is used to verify the signal path from the transmitting device to the receiving device.";
CM_ SG_ 2349465760 CruiseCtrlDisableCommand "This parameter is used to disable cruise control from a source other than the driver controlled switch if cruise control is active.  It is also used to inhibit cruise control from becoming active if it is not currently active.  If this parameter is used to disable cruise control, then cruise control will need to be re-initialized and the previous set speed will not be retained.";

BA_DEF_ BU_ "NodeLayerModules" STRING ;
BA_DEF_ BU_ "NmStationAddress" HEX 0 255;
BA_DEF_ BU_ "NmCAN" INT 1 2;
BA_DEF_ BU_ "ILUsed" ENUM "No","Yes";
BA_DEF_ BU_ "J1939MultiPgBroadcastType" ENUM "FBFF","FEFF";
BA_DEF_ BU_ "J1939MultiPgSizeThreshold" INT 0 64;
BA_DEF_ BU_ "J1939MultiPgSendTimeout" INT 0 3600000;
BA_DEF_ "NmType" STRING ;
BA_DEF_ "VersionYear" INT 2010 2999;
BA_DEF_ "ProtocolType" STRING ;
BA_DEF_ "NmMessageCount" INT 0 255;
BA_DEF_ "NmBaseAddress" HEX 0 2047;
BA_DEF_ "DBName" STRING ;
BA_DEF_ "BusType" STRING ;
BA_DEF_ "Baudrate" INT 0 1000000;
BA_DEF_ BO_ "GenMsgSendType" ENUM "Cycle","NoMsgSendType","IfActive","Event","CA","CE";
BA_DEF_ BO_ "GenMsgNrOfRepetition" INT 0 0;
BA_DEF_ BO_ "GenMsgILSupport" ENUM "No","Yes";
BA_DEF_ BO_ "GenMsgDelayTime" INT 0 0;
BA_DEF_ BO_ "GenMsgCycleTimeFast" INT 0 0;
BA_DEF_ BO_ "GenMsgCycleTime" INT 0 0;
BA_DEF_ BO_ "NmMessage" ENUM "No","Yes";
BA_DEF_ BO_ "VFrameFormat" ENUM "StandardCAN","ExtendedCAN","reserved","J1939PG";
BA_DEF_ BO_ "J1939CPgTOS" INT 0 7;
BA_DEF_ BO_ "J1939CPgSendTimeout" INT -1 3600000;
BA_DEF_ BO_ "J1939PgAppearanceOnBus" ENUM "Default","CAN_Extended","CANFD_Extended";
BA_DEF_ BO_ "GenMsgRequestable" INT 0 1;
BA_DEF_ SG_ "GenSigInvalidValue" HEX 0 0;
BA_DEF_ SG_ "GenSigStartValue" HEX 0 0;
BA_DEF_ SG_ "GenSigInactiveValue" HEX 0 0;
BA_DEF_ SG_ "GenSigSendType" ENUM "Cycle","OnWrite","OnWriteWithRepetition","OnChange","OnChangeWithRepetition","IfActive","IfActiveWithRepetition","NoSigSendType","vector_leerstring";
BA_DEF_ SG_ "SPN" INT 0 0;
BA_DEF_ SG_ "ASIL" STRING ;
BA_DEF_ SG_ "SigType" ENUM "Default","Range","RangeSigned","ASCII","Discrete","Control","ReferencePGN","DTC","StringDelimiter","StringLength","StringLengthControl","MessageCounter","MessageChecksum";
BA_DEF_ SG_ "GenSigILSupport" ENUM "No","Yes";
BA_DEF_ SG_ "GenSigEVName" STRING ;
BA_DEF_DEF_ "NodeLayerModules" "OSEKNM01.dll,CANoeILNLVector.dll";
BA_DEF_DEF_ "NmStationAddress" 254;
BA_DEF_DEF_ "NmCAN" 2;
BA_DEF_DEF_ "ILUsed" "Yes";
BA_DEF_DEF_ "J1939MultiPgBroadcastType" "FEFF";
BA_DEF_DEF_ "J1939MultiPgSizeThreshold" 56;
BA_DEF_DEF_ "J1939MultiPgSendTimeout" 2;
BA_DEF_DEF_ "NmType" "OSEK";
BA_DEF_DEF_ "VersionYear" 2019;
BA_DEF_DEF_ "ProtocolType" "CAN";
BA_DEF_DEF_ "NmMessageCount" 128;
BA_DEF_DEF_ "NmBaseAddress" 1024;
BA_DEF_DEF_ "DBName" "";
BA_DEF_DEF_ "BusType" "";
BA_DEF_DEF_ "Baudrate" 500000;
BA_DEF_DEF_ "GenMsgSendType" "Cycle";
BA_DEF_DEF_ "GenMsgNrOfRepetition" 0;
BA_DEF_DEF_ "GenMsgILSupport" "Yes";
BA_DEF_DEF_ "GenMsgDelayTime" 0;
BA_DEF_DEF_ "GenMsgCycleTimeFast" 0;
BA_DEF_DEF_ "GenMsgCycleTime" 100;
BA_DEF_DEF_ "NmMessage" "No";
BA_DEF_DEF_ "VFrameFormat" "StandardCAN";
BA_DEF_DEF_ "J1939CPgTOS" 2;
BA_DEF_DEF_ "J1939CPgSendTimeout" -1;
BA_DEF_DEF_ "J1939PgAppearanceOnBus" "Default";
BA_DEF_DEF_ "GenMsgRequestable" 1;
BA_DEF_DEF_ "GenSigInvalidValue" 0;
BA_DEF_DEF_ "GenSigStartValue" 0;
BA_DEF_DEF_ "GenSigInactiveValue" 0;
BA_DEF_DEF_ "GenSigSendType" "Cycle";
BA_DEF_DEF_ "SPN" 0;
BA_DEF_DEF_ "ASIL" "";
BA_DEF_DEF_ "SigType" "Default";
BA_DEF_DEF_ "GenSigILSupport" "Yes";
BA_DEF_DEF_ "GenSigEVName" "Env@Nodename_@Signame";
BA_ "BusType" "CAN";
BA_ "ProtocolType" "J1939";
BA_ "DBName" "Matrix";
BA_ "NmStationAddress" BU_ VDCU_V 3;
BA_ "NmStationAddress" BU_ CDCU 33;
BA_ "NmStationAddress" BU_ VDR_TBOX 159;
BA_ "NmStationAddress" BU_ ADCU 42;
BA_ "NmStationAddress" BU_ VIU_B 100;
BA_ "NmStationAddress" BU_ VIU_C 48;
BA_ "NmStationAddress" BU_ VDCU_M 39;
BA_ "NmStationAddress" BU_ EPB 80;
BA_ "NmStationAddress" BU_ EPS_M 19;
BA_ "NmStationAddress" BU_ EPS_S 20;
BA_ "NmStationAddress" BU_ EBS 11;
BA_ "NmStationAddress" BU_ FCS 42;
BA_ "NmStationAddress" BU_ CMS_R 97;
BA_ "NmStationAddress" BU_ CMS_B 99;
BA_ "NmStationAddress" BU_ ECAS 47;
BA_ "NmStationAddress" BU_ EGSM 5;
BA_ "NmStationAddress" BU_ MTCU 4;
BA_ "GenMsgCycleTime" BO_ 2566889511 500;
BA_ "NmMessage" BO_ 2566889511 1;
BA_ "GenMsgCycleTimeFast" BO_ 2566889511 50;
BA_ "GenMsgSendType" BO_ 2566889511 4;
BA_ "VFrameFormat" BO_ 2566889511 1;
BA_ "GenMsgNrOfRepetition" BO_ 2566870679 3;
BA_ "GenMsgCycleTime" BO_ 2566870679 500;
BA_ "GenMsgCycleTimeFast" BO_ 2566870679 50;
BA_ "GenMsgSendType" BO_ 2566870679 5;
BA_ "VFrameFormat" BO_ 2566870679 3;
BA_ "GenMsgNrOfRepetition" BO_ 2566900119 3;
BA_ "GenMsgCycleTime" BO_ 2566900119 500;
BA_ "GenMsgCycleTimeFast" BO_ 2566900119 50;
BA_ "GenMsgSendType" BO_ 2566900119 5;
BA_ "VFrameFormat" BO_ 2566900119 3;
BA_ "GenMsgCycleTime" BO_ 2566854039 50;
BA_ "VFrameFormat" BO_ 2566854039 3;
BA_ "GenMsgNrOfRepetition" BO_ 2566907927 3;
BA_ "GenMsgCycleTimeFast" BO_ 2566907927 50;
BA_ "GenMsgSendType" BO_ 2566907927 4;
BA_ "VFrameFormat" BO_ 2566907927 3;
BA_ "GenMsgCycleTime" BO_ 2566723351 250;
BA_ "VFrameFormat" BO_ 2566723351 3;
BA_ "GenMsgNrOfRepetition" BO_ 2566850171 3;
BA_ "GenMsgCycleTimeFast" BO_ 2566850171 50;
BA_ "VFrameFormat" BO_ 2566850171 3;
BA_ "VFrameFormat" BO_ 2563833751 3;
BA_ "GenMsgNrOfRepetition" BO_ 2566905239 3;
BA_ "GenMsgCycleTime" BO_ 2566905239 500;
BA_ "GenMsgCycleTimeFast" BO_ 2566905239 50;
BA_ "GenMsgSendType" BO_ 2566905239 5;
BA_ "VFrameFormat" BO_ 2566905239 3;
BA_ "GenMsgNrOfRepetition" BO_ 2566854551 3;
BA_ "GenMsgCycleTime" BO_ 2566854551 500;
BA_ "GenMsgCycleTimeFast" BO_ 2566854551 50;
BA_ "GenMsgSendType" BO_ 2566854551 5;
BA_ "VFrameFormat" BO_ 2566854551 3;
BA_ "GenMsgNrOfRepetition" BO_ 2566850711 3;
BA_ "GenMsgCycleTime" BO_ 2566850711 500;
BA_ "GenMsgCycleTimeFast" BO_ 2566850711 50;
BA_ "GenMsgSendType" BO_ 2566850711 5;
BA_ "VFrameFormat" BO_ 2566850711 3;
BA_ "GenMsgNrOfRepetition" BO_ 2566853015 3;
BA_ "GenMsgCycleTime" BO_ 2566853015 500;
BA_ "GenMsgCycleTimeFast" BO_ 2566853015 50;
BA_ "GenMsgSendType" BO_ 2566853015 5;
BA_ "VFrameFormat" BO_ 2566853015 3;
BA_ "VFrameFormat" BO_ 2566865177 3;
BA_ "VFrameFormat" BO_ 2566868505 3;
BA_ "VFrameFormat" BO_ 2566865433 3;
BA_ "VFrameFormat" BO_ 2566865689 3;
BA_ "VFrameFormat" BO_ 2566864665 3;
BA_ "VFrameFormat" BO_ 2566866713 3;
BA_ "GenMsgSendType" BO_ 2566907722 2;
BA_ "VFrameFormat" BO_ 2566907722 3;
BA_ "GenMsgCycleTime" BO_ 2566908234 0;
BA_ "GenMsgSendType" BO_ 2566908234 3;
BA_ "VFrameFormat" BO_ 2566908234 3;
BA_ "GenMsgCycleTime" BO_ 2566908490 0;
BA_ "GenMsgSendType" BO_ 2566908490 3;
BA_ "VFrameFormat" BO_ 2566908490 3;
BA_ "GenMsgSendType" BO_ 2565537610 2;
BA_ "VFrameFormat" BO_ 2565537610 3;
BA_ "GenMsgSendType" BO_ 2566907210 2;
BA_ "VFrameFormat" BO_ 2566907210 3;
BA_ "VFrameFormat" BO_ 2566909258 3;
BA_ "GenMsgNrOfRepetition" BO_ 2566901834 3;
BA_ "GenMsgCycleTime" BO_ 2566901834 500;
BA_ "GenMsgCycleTimeFast" BO_ 2566901834 50;
BA_ "GenMsgSendType" BO_ 2566901834 5;
BA_ "VFrameFormat" BO_ 2566901834 3;
BA_ "GenMsgNrOfRepetition" BO_ 2566902602 3;
BA_ "GenMsgCycleTime" BO_ 2566902602 500;
BA_ "GenMsgCycleTimeFast" BO_ 2566902602 50;
BA_ "GenMsgSendType" BO_ 2566902602 5;
BA_ "VFrameFormat" BO_ 2566902602 3;
BA_ "GenMsgSendType" BO_ 2566907431 2;
BA_ "VFrameFormat" BO_ 2566907431 3;
BA_ "GenMsgCycleTime" BO_ 2566908199 0;
BA_ "GenMsgSendType" BO_ 2566908199 3;
BA_ "VFrameFormat" BO_ 2566908199 3;
BA_ "GenMsgCycleTime" BO_ 2566908455 0;
BA_ "GenMsgSendType" BO_ 2566908455 3;
BA_ "VFrameFormat" BO_ 2566908455 3;
BA_ "GenMsgSendType" BO_ 2565537575 2;
BA_ "VFrameFormat" BO_ 2565537575 3;
BA_ "GenMsgCycleTime" BO_ 2566907943 0;
BA_ "GenMsgSendType" BO_ 2566907943 3;
BA_ "VFrameFormat" BO_ 2566907943 3;
BA_ "VFrameFormat" BO_ 2566862831 3;
BA_ "VFrameFormat" BO_ 2566858479 3;
BA_ "VFrameFormat" BO_ 2566856687 3;
BA_ "VFrameFormat" BO_ 2566858991 3;
BA_ "VFrameFormat" BO_ 2566857967 3;
BA_ "GenMsgCycleTime" BO_ 2566858223 500;
BA_ "VFrameFormat" BO_ 2566858223 3;
BA_ "GenMsgCycleTime" BO_ 2566857711 500;
BA_ "VFrameFormat" BO_ 2566857711 3;
BA_ "GenMsgCycleTime" BO_ 2566853871 500;
BA_ "VFrameFormat" BO_ 2566853871 3;
BA_ "VFrameFormat" BO_ 2566858735 3;
BA_ "VFrameFormat" BO_ 2566866215 3;
BA_ "VFrameFormat" BO_ 2566866983 3;
BA_ "GenMsgCycleTime" BO_ 2566868263 50;
BA_ "VFrameFormat" BO_ 2566868263 3;
BA_ "VFrameFormat" BO_ 2566870288 3;
BA_ "GenMsgCycleTime" BO_ 2566708224 1000;
BA_ "VFrameFormat" BO_ 2566708224 3;
BA_ "GenMsgCycleTime" BO_ 2566719232 1000;
BA_ "VFrameFormat" BO_ 2566719232 3;
BA_ "GenMsgCycleTime" BO_ 2566853359 50;
BA_ "VFrameFormat" BO_ 2566853359 3;
BA_ "VFrameFormat" BO_ 2566853615 3;
BA_ "VFrameFormat" BO_ 2566872103 3;
BA_ "VFrameFormat" BO_ 2566893351 3;
BA_ "VFrameFormat" BO_ 2566875943 3;
BA_ "GenMsgCycleTime" BO_ 2566912807 5000;
BA_ "VFrameFormat" BO_ 2566912807 3;
BA_ "GenMsgCycleTime" BO_ 2566861351 20;
BA_ "VFrameFormat" BO_ 2566861351 3;
BA_ "GenMsgCycleTime" BO_ 2566861607 50;
BA_ "GenMsgCycleTimeFast" BO_ 2566861607 20;
BA_ "VFrameFormat" BO_ 2566861607 3;
BA_ "GenMsgCycleTime" BO_ 2566845721 1000;
BA_ "VFrameFormat" BO_ 2566845721 3;
BA_ "VFrameFormat" BO_ 2566872611 3;
BA_ "VFrameFormat" BO_ 2566873629 3;
BA_ "GenMsgCycleTime" BO_ 2365537816 50;
BA_ "VFrameFormat" BO_ 2365537816 3;
BA_ "VFrameFormat" BO_ 2566873374 3;
BA_ "GenMsgCycleTime" BO_ 2566892165 500;
BA_ "VFrameFormat" BO_ 2566892165 3;
BA_ "GenMsgNrOfRepetition" BO_ 2566900371 3;
BA_ "GenMsgCycleTime" BO_ 2566900371 500;
BA_ "GenMsgCycleTimeFast" BO_ 2566900371 50;
BA_ "GenMsgSendType" BO_ 2566900371 5;
BA_ "VFrameFormat" BO_ 2566900371 3;
BA_ "VFrameFormat" BO_ 2566872532 3;
BA_ "VFrameFormat" BO_ 2566872789 3;
BA_ "VFrameFormat" BO_ 2566867415 3;
BA_ "VFrameFormat" BO_ 2566867672 3;
BA_ "GenMsgCycleTime" BO_ 2365536412 20;
BA_ "VFrameFormat" BO_ 2365536412 3;
BA_ "GenMsgCycleTime" BO_ 2365537692 20;
BA_ "VFrameFormat" BO_ 2365537692 3;
BA_ "GenMsgCycleTime" BO_ 2348810400 200;
BA_ "GenMsgCycleTimeFast" BO_ 2348810400 20;
BA_ "GenMsgSendType" BO_ 2348810400 4;
BA_ "VFrameFormat" BO_ 2348810400 3;
BA_ "GenMsgCycleTimeFast" BO_ 2348814492 20;
BA_ "GenMsgSendType" BO_ 2348814492 2;
BA_ "VFrameFormat" BO_ 2348814492 3;
BA_ "VFrameFormat" BO_ 2349465760 3;
BA_ "SPN" SG_ 2566889511 VDCU_SourceNodeID 520608;
BA_ "GenSigStartValue" SG_ 2566889511 VDCU_SourceNodeID 84;
BA_ "SPN" SG_ 2566889511 VDCU_RepeatMessageRequest 520609;
BA_ "SPN" SG_ 2566889511 VDCU_NMState_RMSfromBSM 520610;
BA_ "GenSigSendType" SG_ 2566889511 VDCU_NMState_RMSfromBSM 6;
BA_ "SPN" SG_ 2566889511 VDCU_NMState_RMSfromPBSM 520611;
BA_ "GenSigSendType" SG_ 2566889511 VDCU_NMState_RMSfromPBSM 6;
BA_ "SPN" SG_ 2566889511 VDCU_NMState_RMSfromNOS 520612;
BA_ "GenSigSendType" SG_ 2566889511 VDCU_NMState_RMSfromNOS 6;
BA_ "SPN" SG_ 2566889511 VDCU_NMState_RMSfromRSS 520613;
BA_ "GenSigSendType" SG_ 2566889511 VDCU_NMState_RMSfromRSS 6;
BA_ "SPN" SG_ 2566889511 VDCU_NMState_NOSfromRMS 520614;
BA_ "SPN" SG_ 2566889511 VDCU_NMState_NOSfromRSS 520615;
BA_ "SPN" SG_ 2566889511 VDCU_WakeupSource 520618;
BA_ "SPN" SG_ 2566889511 VDCU_NMKpARson_NMPduReceived 520815;
BA_ "SPN" SG_ 2566889511 VDCU_NMKpARson_TimeOut 520621;
BA_ "SPN" SG_ 2566889511 VDCU_NMKpARson_Diag 520620;
BA_ "SPN" SG_ 2566889511 VDCU_NMKpARson_KL15 520619;
BA_ "SPN" SG_ 2566889511 VDCU_NMKpARson_LINReq 520814;
BA_ "SPN" SG_ 2566889511 VDCU_NMKpARson_WinCtrl_L 520814;
BA_ "SPN" SG_ 2566889511 VDCU_NMKpARson_WinCtrl_R 520814;
BA_ "SPN" SG_ 2566889511 VDCU_NMKpARson_BrakePedalPressed 520814;
BA_ "SPN" SG_ 2566889511 VDCU_NMKpARson_LowBeamReq 520814;
BA_ "SPN" SG_ 2566889511 VDCU_NMKpARson_PosnLigjtReq 520814;
BA_ "SPN" SG_ 2566889511 VDCU_NMKpARson_DCChargeActive 520814;
BA_ "SPN" SG_ 2566889511 VDCU_NMKpARson_PowerOFFdelayMonitor 520814;
BA_ "SPN" SG_ 2566889511 VDCU_NMKpARson_ACChargeActive 520814;
BA_ "SPN" SG_ 2566889511 VDCU_NMKpARson_HVConnected 520814;
BA_ "SPN" SG_ 2566889511 VDCU_NMKpARson_ChargeWarmer 520814;
BA_ "SPN" SG_ 2566889511 VDCU_NMKpARson_Ready 520814;
BA_ "SPN" SG_ 2566889511 VDCU_NMKpARson_SmartCharge 520814;
BA_ "ASIL" SG_ 2566870679 WinCtrlReq_Drvr "A";
BA_ "GenSigSendType" SG_ 2566870679 WinCtrlReq_Drvr 4;
BA_ "ASIL" SG_ 2566870679 WinCtrlReq_Pass "A";
BA_ "GenSigSendType" SG_ 2566870679 WinCtrlReq_Pass 4;
BA_ "GenSigSendType" SG_ 2566870679 IVI_DrSeatHeatSw 4;
BA_ "GenSigSendType" SG_ 2566870679 IVI_DrSeatWindLevelSet 4;
BA_ "GenSigSendType" SG_ 2566870679 IVI_DrSeatMassageModSet 4;
BA_ "GenSigSendType" SG_ 2566870679 IVI_HeatlinkageSet 4;
BA_ "GenSigSendType" SG_ 2566870679 IVI_ExtrMirrHeatSwt 4;
BA_ "GenSigSendType" SG_ 2566870679 IVI_SWS_UserDifined 4;
BA_ "GenSigSendType" SG_ 2566870679 IVI_SteerWheelHeatSwt 4;
BA_ "GenSigSendType" SG_ 2566900119 IVI_HornShiftSwitch 4;
BA_ "GenSigSendType" SG_ 2566900119 IVI_VehLockRemindSet 4;
BA_ "GenSigSendType" SG_ 2566900119 IVI_LampFollowMeHomeSet 4;
BA_ "GenSigSendType" SG_ 2566900119 IVI_LampAwayHomeSet 4;
BA_ "GenSigSendType" SG_ 2566900119 IVI_FindMyCarSet 4;
BA_ "GenSigSendType" SG_ 2566900119 IVI_SmartWelcomeSet 4;
BA_ "GenSigSendType" SG_ 2566900119 IVI_LogoLightSwitch 4;
BA_ "GenSigSendType" SG_ 2566900119 IVI_ADBSwitch 4;
BA_ "GenSigSendType" SG_ 2566900119 IVI_RainAutoCloseWinSet 4;
BA_ "GenSigSendType" SG_ 2566900119 IVI_LockAutoCloseWinSet 4;
BA_ "GenSigSendType" SG_ 2566900119 IVI_UnlockSet 4;
BA_ "GenSigSendType" SG_ 2566900119 IVI_SpeedAutoLockSet 4;
BA_ "GenSigSendType" SG_ 2566900119 IVI_StopAutoUnlockSet 4;
BA_ "GenSigSendType" SG_ 2566900119 IVI_ApproachAutoUnlockSet 4;
BA_ "GenSigSendType" SG_ 2566900119 IVI_AwayAutoLockSet 4;
BA_ "GenSigSendType" SG_ 2566900119 IVI_SpeedLimitSet_Sleeper 4;
BA_ "GenSigSendType" SG_ 2566900119 IVI_WCMEnableSwitch 4;
BA_ "GenSigSendType" SG_ 2566900119 IVI_BackLightBriSet 4;
BA_ "GenSigSendType" SG_ 2566900119 CeilingLightSet 4;
BA_ "GenSigSendType" SG_ 2566900119 IVI_VSPOpenSet 4;
BA_ "SPN" SG_ 2566907927 CDCU_MLS_Page 520002;
BA_ "GenSigSendType" SG_ 2566907927 CDCU_MLS_Page 6;
BA_ "SPN" SG_ 2566907927 CDCU_MLS_truck_trailer 520003;
BA_ "GenSigSendType" SG_ 2566907927 CDCU_MLS_truck_trailer 6;
BA_ "SPN" SG_ 2566907927 CDCU_MLS 520004;
BA_ "GenSigSendType" SG_ 2566907927 CDCU_MLS 6;
BA_ "SPN" SG_ 2566907927 CDCU_MLS_Tyre_Loc 520005;
BA_ "GenSigStartValue" SG_ 2566907927 CDCU_MLS_Tyre_Loc 23;
BA_ "GenSigSendType" SG_ 2566907927 CDCU_MLS_Tyre_Loc 6;
BA_ "SPN" SG_ 2566723351 DriverBeltlockStatus 4952;
BA_ "GenSigInactiveValue" SG_ 2566723351 DriverBeltlockStatus 2;
BA_ "SPN" SG_ 2566723351 PassengerBeltlockStatus 4952;
BA_ "GenSigInactiveValue" SG_ 2566723351 PassengerBeltlockStatus 2;
BA_ "GenSigStartValue" SG_ 2566850171 DMS_SeatShakeSts 7;
BA_ "GenSigSendType" SG_ 2566850171 DMS_SeatShakeSts 4;
BA_ "SPN" SG_ 2563833751 IlluminationBrightnessPercent 1487;
BA_ "GenSigSendType" SG_ 2566905239 IVI_ACOffSwt 4;
BA_ "GenSigSendType" SG_ 2566905239 IVI_ACAutoSwt 4;
BA_ "GenSigSendType" SG_ 2566905239 IVI_ACModeMotorSwt 4;
BA_ "GenSigSendType" SG_ 2566905239 IVI_ACACSwt 4;
BA_ "GenSigSendType" SG_ 2566905239 IVI_ACPTCSwt 4;
BA_ "GenSigSendType" SG_ 2566905239 IVI_ACCycleMotorSwt 4;
BA_ "ASIL" SG_ 2566905239 IVI_ACFrontDefrostSwt "A";
BA_ "GenSigSendType" SG_ 2566905239 IVI_ACFrontDefrostSwt 4;
BA_ "GenSigSendType" SG_ 2566905239 IVI_ACTempPlusSwt 4;
BA_ "GenSigSendType" SG_ 2566905239 IVI_ACTempMinusSwt 4;
BA_ "GenSigSendType" SG_ 2566905239 IVI_ACTempLevelSwt 4;
BA_ "GenSigSendType" SG_ 2566905239 IVI_ACBlowerLvlSeltSwt 4;
BA_ "GenSigSendType" SG_ 2566905239 IVI_LonizerSwt 4;
BA_ "GenSigSendType" SG_ 2566905239 IVI_AirPurgeSwt 4;
BA_ "GenSigSendType" SG_ 2566905239 IVI_AcMaxSwt 4;
BA_ "GenSigSendType" SG_ 2566905239 IVI_HeatingMaxSwt 4;
BA_ "GenSigSendType" SG_ 2566905239 IVI_TempZoneSyncSwt 4;
BA_ "SPN" SG_ 2566905239 IVI_ACBlowerLvlSeltSwt_Slpr 520392;
BA_ "GenSigSendType" SG_ 2566905239 IVI_ACBlowerLvlSeltSwt_Slpr 4;
BA_ "GenSigSendType" SG_ 2566905239 IVI_ACTempPlusSwt_Slpr 4;
BA_ "GenSigSendType" SG_ 2566905239 IVI_ACTempMinusSwt_Slpr 4;
BA_ "GenSigSendType" SG_ 2566905239 IVI_ACTempLevelSwt_Slpr 4;
BA_ "GenSigSendType" SG_ 2566905239 IVI_ACBlowerPlusSwt_Slpr 4;
BA_ "GenSigSendType" SG_ 2566905239 IVI_ACBlowerMinusSwt_Slpr 4;
BA_ "GenSigSendType" SG_ 2566905239 IVI_ACBlowerLvlMinusSwt 4;
BA_ "SPN" SG_ 2566905239 IVI_ACOffSwt_Slpr 520391;
BA_ "GenSigSendType" SG_ 2566905239 IVI_ACOffSwt_Slpr 4;
BA_ "GenSigSendType" SG_ 2566905239 IVI_ACTimingRunSwt_Slpr 4;
BA_ "SPN" SG_ 2566854551 WheelDifferentialLock_Sw 516130;
BA_ "GenSigSendType" SG_ 2566854551 WheelDifferentialLock_Sw 4;
BA_ "SPN" SG_ 2566854551 AxleDifferentialLockSwt 516131;
BA_ "GenSigInactiveValue" SG_ 2566854551 AxleDifferentialLockSwt 2;
BA_ "GenSigSendType" SG_ 2566854551 AxleDifferentialLockSwt 4;
BA_ "GenSigSendType" SG_ 2566854551 V2V_Sw 4;
BA_ "GenSigSendType" SG_ 2566854551 V2G_Sw 4;
BA_ "GenSigStartValue" SG_ 2566854551 V2V_V2G_StopSoc_Set 255;
BA_ "GenSigSendType" SG_ 2566854551 V2V_V2G_StopSoc_Set 4;
BA_ "GenSigStartValue" SG_ 2566854551 BattIIntlgntRecharge_Set 1;
BA_ "GenSigSendType" SG_ 2566854551 BattIIntlgntRecharge_Set 4;
BA_ "GenSigSendType" SG_ 2566854551 IVI_220VSocket_Sw 4;
BA_ "GenSigSendType" SG_ 2566854551 EnergyMode_Set 4;
BA_ "GenSigSendType" SG_ 2566854551 IVI_VehicleCreepSet 4;
BA_ "GenSigSendType" SG_ 2566854551 IVI_VehicleDragModeSet 4;
BA_ "GenSigSendType" SG_ 2566854551 IVI_EPModeSet 4;
BA_ "GenSigSendType" SG_ 2566854551 IVI_ServiceModeSet 4;
BA_ "GenSigSendType" SG_ 2566854551 IVI_DrivngMileageDisplaySet 4;
BA_ "GenSigSendType" SG_ 2566850711 IVI_ChargingKeepWarmSet 4;
BA_ "GenSigSendType" SG_ 2566850711 IVI_HeatByApntmntSet 4;
BA_ "GenSigSendType" SG_ 2566850711 IVI_HeatByApntmntReplicationSet 4;
BA_ "GenSigStartValue" SG_ 2566850711 IVI_HeatByApntmntHourStart 31;
BA_ "GenSigSendType" SG_ 2566850711 IVI_HeatByApntmntHourStart 4;
BA_ "GenSigStartValue" SG_ 2566850711 IVI_HeatByApntmntMinuteStart 63;
BA_ "GenSigSendType" SG_ 2566850711 IVI_HeatByApntmntMinuteStart 4;
BA_ "GenSigSendType" SG_ 2566850711 IVI_ChargngByApntmntSet 4;
BA_ "GenSigStartValue" SG_ 2566850711 IVI_ChargngByApntmntHourStart 31;
BA_ "GenSigSendType" SG_ 2566850711 IVI_ChargngByApntmntHourStart 4;
BA_ "GenSigSendType" SG_ 2566850711 IVI_ImmediatStartChargngSet 4;
BA_ "GenSigStartValue" SG_ 2566850711 IVI_ChargngByApntmntMinuteStart 63;
BA_ "GenSigSendType" SG_ 2566850711 IVI_ChargngByApntmntMinuteStart 4;
BA_ "GenSigSendType" SG_ 2566850711 IVI_ChargngByApntmntReplicationSet 4;
BA_ "GenSigStartValue" SG_ 2566850711 IVI_ChargngByApntmntHourEnd 31;
BA_ "GenSigSendType" SG_ 2566850711 IVI_ChargngByApntmntHourEnd 4;
BA_ "GenSigStartValue" SG_ 2566850711 IVI_ChargngByApntmntMinuteEnd 63;
BA_ "GenSigSendType" SG_ 2566850711 IVI_ChargngByApntmntMinuteEnd 4;
BA_ "GenSigSendType" SG_ 2566850711 IVI_ChargingStopSwt 4;
BA_ "GenSigStartValue" SG_ 2566853015 IVI_SwSet_V2GByApntmntHourStart 31;
BA_ "GenSigSendType" SG_ 2566853015 IVI_SwSet_V2GByApntmntHourStart 4;
BA_ "GenSigSendType" SG_ 2566853015 IVI_SwSet_V2GByApntmntMinuteStart 4;
BA_ "GenSigSendType" SG_ 2566853015 IVI_Sw_V2GExpectedSOCForVehicleUse 4;
BA_ "GenSigSendType" SG_ 2566853015 IVI_Sw_StopDCDisCharging 4;
BA_ "GenSigStartValue" SG_ 2566865177 ACTempLevelDisp 1;
BA_ "GenSigStartValue" SG_ 2566865177 ACModeMotorDisp 4;
BA_ "GenSigStartValue" SG_ 2566865177 ACModeMotorCtrl 4;
BA_ "ASIL" SG_ 2566865177 ACModeMotorCtrl "A";
BA_ "GenSigStartValue" SG_ 2566865177 ACCycleMotorDisp 2;
BA_ "GenSigStartValue" SG_ 2566865177 ACCycleMotorPosnCtrl 2;
BA_ "ASIL" SG_ 2566865177 ACBlowerLevelCtrl "A";
BA_ "ASIL" SG_ 2566865433 FAN_LowRelayCtrl "A";
BA_ "ASIL" SG_ 2566865433 Blower_RelayCtrl "A";
BA_ "ASIL" SG_ 2566865689 LFAN1_PWM "A";
BA_ "ASIL" SG_ 2566865689 LFAN2_PWM "A";
BA_ "ASIL" SG_ 2566865689 LFAN3_PWM "A";
BA_ "ASIL" SG_ 2566865689 LFAN4_PWM "A";
BA_ "ASIL" SG_ 2566865689 EAC1_ACFrontDefrostSysSts "A";
BA_ "ASIL" SG_ 2566865689 EAC2_ACFrontDefrostSysSts "A";
BA_ "GenSigSendType" SG_ 2566907722 T_boxEncryptData_Byte1 5;
BA_ "GenSigSendType" SG_ 2566907722 T_boxEncryptData_Byte2 5;
BA_ "GenSigSendType" SG_ 2566907722 T_boxEncryptData_Byte3 5;
BA_ "GenSigSendType" SG_ 2566907722 T_boxEncryptData_Byte4 5;
BA_ "GenSigSendType" SG_ 2566907722 T_boxEncryptData_Byte5 5;
BA_ "GenSigSendType" SG_ 2566907722 T_boxEncryptData_Byte6 5;
BA_ "GenSigSendType" SG_ 2566907722 T_boxEncryptData_Byte7 5;
BA_ "GenSigSendType" SG_ 2566907722 T_boxEncryptData_Byte8 5;
BA_ "GenSigSendType" SG_ 2566907722 T_boxEncryptData_Byte9 5;
BA_ "GenSigSendType" SG_ 2566907722 T_boxEncryptData_Byte10 5;
BA_ "GenSigSendType" SG_ 2566907722 T_boxEncryptData_Byte11 5;
BA_ "GenSigSendType" SG_ 2566907722 T_boxEncryptData_Byte12 5;
BA_ "GenSigSendType" SG_ 2566907722 T_boxEncryptData_Byte13 5;
BA_ "GenSigSendType" SG_ 2566907722 T_boxEncryptData_Byte14 5;
BA_ "GenSigSendType" SG_ 2566907722 T_boxEncryptData_Byte15 5;
BA_ "GenSigSendType" SG_ 2566907722 T_boxEncryptData_Byte16 5;
BA_ "GenSigSendType" SG_ 2566908234 VehicleID_Tbox 5;
BA_ "GenSigSendType" SG_ 2566908490 SecretKey_Tbox_Byte1 5;
BA_ "GenSigSendType" SG_ 2566908490 SecretKey_Tbox_Byte2 5;
BA_ "GenSigSendType" SG_ 2566908490 SecretKey_Tbox_Byte3 5;
BA_ "GenSigSendType" SG_ 2566908490 SecretKey_Tbox_Byte4 5;
BA_ "GenSigSendType" SG_ 2566908490 SecretKey_Tbox_Byte5 5;
BA_ "GenSigSendType" SG_ 2566908490 SecretKey_Tbox_Byte6 5;
BA_ "GenSigSendType" SG_ 2566908490 SecretKey_Tbox_Byte7 5;
BA_ "GenSigSendType" SG_ 2566908490 SecretKey_Tbox_Byte8 5;
BA_ "GenSigSendType" SG_ 2566908490 SecretKey_Tbox_Byte9 5;
BA_ "GenSigSendType" SG_ 2566908490 SecretKey_Tbox_Byte10 5;
BA_ "GenSigSendType" SG_ 2566908490 SecretKey_Tbox_Byte11 5;
BA_ "GenSigSendType" SG_ 2566908490 SecretKey_Tbox_Byte12 5;
BA_ "GenSigSendType" SG_ 2566908490 SecretKey_Tbox_Byte13 5;
BA_ "GenSigSendType" SG_ 2566908490 SecretKey_Tbox_Byte14 5;
BA_ "GenSigSendType" SG_ 2566908490 SecretKey_Tbox_Byte15 5;
BA_ "GenSigSendType" SG_ 2566908490 SecretKey_Tbox_Byte16 5;
BA_ "GenSigSendType" SG_ 2565537610 Tbox_RQST_PGN 5;
BA_ "GenSigSendType" SG_ 2566907210 ControlIdentifier 5;
BA_ "GenSigSendType" SG_ 2566907210 AwakeNetwork 5;
BA_ "GenSigSendType" SG_ 2566907210 TBOX_ACTempLevelReq_TM1 5;
BA_ "GenSigSendType" SG_ 2566907210 TBOX_ACFrontDefrostReq_TM1 5;
BA_ "GenSigSendType" SG_ 2566907210 TBOX_Cockpit_Cleaning_TM1 5;
BA_ "GenSigSendType" SG_ 2566907210 TBOX_AcMaxSwt 5;
BA_ "GenSigSendType" SG_ 2566907210 TBOX_HeatingMaxSwt 5;
BA_ "GenSigSendType" SG_ 2566907210 TBOX_DrSeatHeatSw 5;
BA_ "GenSigSendType" SG_ 2566907210 TBOX_SteerWheelHeatSwt 5;
BA_ "GenSigSendType" SG_ 2566907210 TBOX_ChargngByApntmntHourStartFb 5;
BA_ "GenSigSendType" SG_ 2566907210 TBOX_ChargngByApntmntMinuteStartFb 5;
BA_ "GenSigSendType" SG_ 2566907210 TBOX_DCChargingByApntmnReplication_St 5;
BA_ "GenSigSendType" SG_ 2566907210 TBOX_ChargngByApntmntHourEndFb 5;
BA_ "GenSigSendType" SG_ 2566907210 TBOX_ChargngByApntmntMinuteEndFb 5;
BA_ "GenSigSendType" SG_ 2566901834 TBOX_4_DischargeCutoffSOC 5;
BA_ "GenSigSendType" SG_ 2566901834 TBOX4_N_ExpectedSOCForVehicleUse 5;
BA_ "GenSigSendType" SG_ 2566901834 TBOX_4_Discharge_St 5;
BA_ "GenSigSendType" SG_ 2566901834 TBOX4_ChargingKeepWarmSet_St 5;
BA_ "GenSigSendType" SG_ 2566901834 TBOX4_DisChargingStop_St 5;
BA_ "GenSigStartValue" SG_ 2566901834 TBOX4_N_ExternalDischargeAppointmentForPickupMinutes 63;
BA_ "GenSigSendType" SG_ 2566901834 TBOX4_N_ExternalDischargeAppointmentForPickupMinutes 5;
BA_ "GenSigStartValue" SG_ 2566901834 TBOX4_N_ExternalDischargeAppointmentForPickupHours 31;
BA_ "GenSigSendType" SG_ 2566901834 TBOX4_N_ExternalDischargeAppointmentForPickupHours 5;
BA_ "GenSigSendType" SG_ 2566901834 TBOX4_V2L_St 5;
BA_ "GenSigSendType" SG_ 2566902602 TBOX5_DCChargingByApntmnt_St 5;
BA_ "GenSigSendType" SG_ 2566902602 TBOX5_InstantCharging_St 5;
BA_ "GenSigSendType" SG_ 2566902602 TBOX5_ChargingStop_St 5;
BA_ "GenSigSendType" SG_ 2566907431 VDCU_RandomData 5;
BA_ "GenSigSendType" SG_ 2566908199 VehicleID_VDCU 5;
BA_ "GenSigSendType" SG_ 2566908455 SecretKey_VDCU_Byte1 5;
BA_ "GenSigSendType" SG_ 2566908455 SecretKey_VDCU_Byte2 5;
BA_ "GenSigSendType" SG_ 2566908455 SecretKey_VDCU_Byte3 5;
BA_ "GenSigSendType" SG_ 2566908455 SecretKey_VDCU_Byte4 5;
BA_ "GenSigSendType" SG_ 2566908455 SecretKey_VDCU_Byte5 5;
BA_ "GenSigSendType" SG_ 2566908455 SecretKey_VDCU_Byte6 5;
BA_ "GenSigSendType" SG_ 2566908455 SecretKey_VDCU_Byte7 5;
BA_ "GenSigSendType" SG_ 2566908455 SecretKey_VDCU_Byte8 5;
BA_ "GenSigSendType" SG_ 2566908455 SecretKey_VDCU_Byte9 5;
BA_ "GenSigSendType" SG_ 2566908455 SecretKey_VDCU_Byte10 5;
BA_ "GenSigSendType" SG_ 2566908455 SecretKey_VDCU_Byte11 5;
BA_ "GenSigSendType" SG_ 2566908455 SecretKey_VDCU_Byte12 5;
BA_ "GenSigSendType" SG_ 2566908455 SecretKey_VDCU_Byte13 5;
BA_ "GenSigSendType" SG_ 2566908455 SecretKey_VDCU_Byte14 5;
BA_ "GenSigSendType" SG_ 2566908455 SecretKey_VDCU_Byte15 5;
BA_ "GenSigSendType" SG_ 2566908455 SecretKey_VDCU_Byte16 5;
BA_ "GenSigSendType" SG_ 2565537575 VDCU_RQST_PGN 5;
BA_ "GenSigSendType" SG_ 2566907943 VDCU_St_AuthenticationResultResponse 1;
BA_ "GenSigSendType" SG_ 2566907943 ValidDKM 1;
BA_ "GenSigStartValue" SG_ 2566856687 VBUS_VCU3_N_DCCurrent 10000;
BA_ "GenSigStartValue" SG_ 2566856687 VBUS_VCU3_N_ConsumedPower 1000;
BA_ "ASIL" SG_ 2566856687 VBUS_VCU3_St_Isolation_clc "A";
BA_ "GenSigStartValue" SG_ 2566858991 VBUS_VCU13_N_MotorSpeed 10000;
BA_ "GenSigStartValue" SG_ 2566858991 VBUS_VCU13_N_MotorTorque 5000;
BA_ "GenSigStartValue" SG_ 2566858991 VBUS_VCU13_N_BRAKE_TOR_MAX 3000;
BA_ "GenSigStartValue" SG_ 2566857967 VBUS_VCU14_N_MotorSpeed 10000;
BA_ "GenSigStartValue" SG_ 2566857967 VBUS_VCU14_N_MotorTorque 5000;
BA_ "ASIL" SG_ 2566858223 VBUS_VCU7_BATT_HVIL_Err "A";
BA_ "GenSigStartValue" SG_ 2566857711 VBUS_VCU9_N_Avail_Remin_Power 1000;
BA_ "GenSigStartValue" SG_ 2566857711 VBUS_VCU9_N_VehInsPow_PER 100;
BA_ "ASIL" SG_ 2566866215 VBUS_VCU20_GSMFltSts "B";
BA_ "GenSigStartValue" SG_ 2566870288 IntarderPilotLampState 3;
BA_ "SPN" SG_ 2566708224 ACCReadinessStatus 5606;
BA_ "SPN" SG_ 2566708224 AEBSReadinessState 6208;
BA_ "GenSigStartValue" SG_ 2566708224 AEBSReadinessState 3;
BA_ "SPN" SG_ 2566719232 EngAmberWarningLampCmd 5078;
BA_ "GenSigStartValue" SG_ 2566719232 EngAmberWarningLampCmd 3;
BA_ "GenSigStartValue" SG_ 2566719232 EngRedStopLampCmd 3;
BA_ "SPN" SG_ 2566719232 OBDMalfunctionIndicatorLampCmd 5080;
BA_ "GenSigStartValue" SG_ 2566719232 OBDMalfunctionIndicatorLampCmd 3;
BA_ "SPN" SG_ 2566719232 EngBrakeActiveLampCmd 5081;
BA_ "GenSigStartValue" SG_ 2566719232 EngBrakeActiveLampCmd 3;
BA_ "SPN" SG_ 2566719232 EngOilPressLowLampCmd 5082;
BA_ "SPN" SG_ 2566719232 EngCoolantTempHighLampCmd 5083;
BA_ "GenSigStartValue" SG_ 2566719232 EngCoolantTempHighLampCmd 3;
BA_ "SPN" SG_ 2566719232 EngCoolantLevelLowLampCmd 5084;
BA_ "SPN" SG_ 2566719232 EngineAirFilterRestrictionLampCommand 5086;
BA_ "ASIL" SG_ 2566853359 VBUS_VCU4_N_VehicleSpeed "B";
BA_ "ASIL" SG_ 2566853359 VBUS_VCU4_St_Gears "B";
BA_ "ASIL" SG_ 2566853359 VBUS_VCU4_St_Vehicle "A";
BA_ "ASIL" SG_ 2566853359 VBUS_VCU4_St_Interlocking "A";
BA_ "ASIL" SG_ 2566853359 VBUS_VCU4_F_Motor "A";
BA_ "ASIL" SG_ 2566853359 VBUS_VCU4_St_Thermal_runaway "A";
BA_ "GenSigStartValue" SG_ 2566853615 VBUS_VCU5_N_DCCurrent 10000;
BA_ "ASIL" SG_ 2566853615 VBUS_VCU5_F_Battery "A";
BA_ "ASIL" SG_ 2566853615 VBUS_VCU5_F_OverTemperature "A";
BA_ "ASIL" SG_ 2566853615 VBUS_VCU5_F_Isolation "A";
BA_ "ASIL" SG_ 2566853615 VBUS_VCU5_St_ChargerIndicator "A";
BA_ "ASIL" SG_ 2566893351 LowBeamFltWarn_VDCU "B";
BA_ "ASIL" SG_ 2566893351 MainBrkLightFltWarn_VDCU "B";
BA_ "ASIL" SG_ 2566893351 TrailerBrkLightFltWarn_VDCU "B";
BA_ "ASIL" SG_ 2566893351 HighBeamFltWarn_VDCU "A";
BA_ "ASIL" SG_ 2566893351 OvertakinglampWarn_VDCU "A";
BA_ "ASIL" SG_ 2566893351 FrontOperatorWiperFltWarn_VDCU "A";
BA_ "ASIL" SG_ 2566893351 WinCtrlFlt_Drvr_VDCU "A";
BA_ "ASIL" SG_ 2566893351 WinCtrlFlt_Pass_VDCU "A";
BA_ "ASIL" SG_ 2566893351 VDCU_ACFrontDefrostSysSts "A";
BA_ "ASIL" SG_ 2566893351 LowPowerModeWarn_VDCU "B";
BA_ "GenSigStartValue" SG_ 2566875943 VBUS_VCU24_N_TripA_AveConsPower 4095;
BA_ "GenSigStartValue" SG_ 2566875943 VBUS_VCU24_N_TripB_AveConsPower 4095;
BA_ "ASIL" SG_ 2566861351 LowBeamReq "B";
BA_ "ASIL" SG_ 2566861351 HighBeamReq "A";
BA_ "ASIL" SG_ 2566861351 MainBrkLightReq "B";
BA_ "ASIL" SG_ 2566861351 TrailerBrkLightReq "B";
BA_ "ASIL" SG_ 2566861607 WiperReq "A";
BA_ "ASIL" SG_ 2566861607 LowPowerMode "B";
BA_ "SPN" SG_ 2566845721 AmbAirT 171;
BA_ "ASIL" SG_ 2566872611 RLS_RQ_WiperSPD "A";
BA_ "ASIL" SG_ 2566872611 RLS_RQ_LowBeam "B";
BA_ "ASIL" SG_ 2566872611 RLS_RQ_LowBeam_FuncErr "B";
BA_ "GenSigSendType" SG_ 2566900371 LOG_LogoLightSet_Sts 4;
BA_ "SPN" SG_ 2566872532 LCM_L_St_RunningLight 2404;
BA_ "GenSigInvalidValue" SG_ 2566872532 LCM_L_St_RunningLight 3;
BA_ "GenSigStartValue" SG_ 2566872532 LCM_L_St_RunningLight 3;
BA_ "SPN" SG_ 2566872532 LCM_L_St_LeftTurnLight 2368;
BA_ "GenSigInvalidValue" SG_ 2566872532 LCM_L_St_LeftTurnLight 3;
BA_ "GenSigStartValue" SG_ 2566872532 LCM_L_St_LeftTurnLight 3;
BA_ "SPN" SG_ 2566872532 LCM_L_St_TractorMarkerLight 2378;
BA_ "GenSigInvalidValue" SG_ 2566872532 LCM_L_St_TractorMarkerLight 3;
BA_ "GenSigStartValue" SG_ 2566872532 LCM_L_St_TractorMarkerLight 3;
BA_ "GenSigInvalidValue" SG_ 2566872532 LCM_L_St_LampFlicker 15;
BA_ "GenSigStartValue" SG_ 2566872532 LCM_L_St_LampFlicker 15;
BA_ "SPN" SG_ 2566872789 LCM_R_St_RunningLight 2404;
BA_ "GenSigInvalidValue" SG_ 2566872789 LCM_R_St_RunningLight 3;
BA_ "GenSigStartValue" SG_ 2566872789 LCM_R_St_RunningLight 3;
BA_ "SPN" SG_ 2566872789 LCM_R_St_RightTurnLight 2370;
BA_ "GenSigInvalidValue" SG_ 2566872789 LCM_R_St_RightTurnLight 3;
BA_ "GenSigStartValue" SG_ 2566872789 LCM_R_St_RightTurnLight 3;
BA_ "SPN" SG_ 2566872789 LCM_R_St_TractorMarkerLight 2378;
BA_ "GenSigInvalidValue" SG_ 2566872789 LCM_R_St_TractorMarkerLight 3;
BA_ "GenSigStartValue" SG_ 2566872789 LCM_R_St_TractorMarkerLight 3;
BA_ "GenSigInvalidValue" SG_ 2566872789 LCM_R_St_LampFlicker 15;
BA_ "GenSigStartValue" SG_ 2566872789 LCM_R_St_LampFlicker 15;
BA_ "ASIL" SG_ 2365536412 EngRqedTorque_TorqueLimit_Auto_Control "B";
BA_ "GenSigStartValue" SG_ 2365537692 SetACFrontDefrostSt 3;
BA_ "GenSigStartValue" SG_ 2365537692 SetWasherSt 3;
BA_ "GenSigStartValue" SG_ 2365537692 EPModeDemand 3;
BA_ "GenSigStartValue" SG_ 2365537692 LidarWashSwitch 3;
BA_ "GenSigStartValue" SG_ 2365537692 SeatbeltTightenRequest 3;
BA_ "GenSigStartValue" SG_ 2365537692 SetHazardSt 3;
BA_ "GenSigStartValue" SG_ 2365537692 SetDoorUnlockingSt 3;
BA_ "GenSigStartValue" SG_ 2365537692 SetWindowSt 3;
BA_ "SPN" SG_ 2348810400 EngOverrideCtrlMode_C0000A0 695;
BA_ "GenSigSendType" SG_ 2348810400 EngOverrideCtrlMode_C0000A0 5;
BA_ "SPN" SG_ 2348810400 EngRqedSpeedCtrlConditions_C0000A0 696;
BA_ "GenSigSendType" SG_ 2348810400 EngRqedSpeedCtrlConditions_C0000A0 5;
BA_ "SPN" SG_ 2348810400 OverrideCtrlModePriority_TSC1 897;
BA_ "GenSigSendType" SG_ 2348810400 OverrideCtrlModePriority_TSC1 5;
BA_ "SPN" SG_ 2348810400 EngRqedSpeed_SpeedLimit_C0000A0 898;
BA_ "GenSigSendType" SG_ 2348810400 EngRqedSpeed_SpeedLimit_C0000A0 5;
BA_ "SPN" SG_ 2348810400 EngRqedTorque_TorqueLimit_C0000A0 518;
BA_ "GenSigSendType" SG_ 2348810400 EngRqedTorque_TorqueLimit_C0000A0 5;
BA_ "SPN" SG_ 2348810400 TransmissionRate_C0000A0 3349;
BA_ "GenSigSendType" SG_ 2348810400 TransmissionRate_C0000A0 5;
BA_ "SPN" SG_ 2348810400 ControlPurpose_C0000A0 3350;
BA_ "GenSigSendType" SG_ 2348810400 ControlPurpose_C0000A0 5;
BA_ "SPN" SG_ 2348810400 EngineRequestedTorqueHiRes_C0000A0 4191;
BA_ "GenSigSendType" SG_ 2348810400 EngineRequestedTorqueHiRes_C0000A0 5;
BA_ "SPN" SG_ 2348810400 MessageCounter_C0000A0 4206;
BA_ "GenSigSendType" SG_ 2348810400 MessageCounter_C0000A0 5;
BA_ "SPN" SG_ 2348810400 MessageChecksum_C0000A0 4207;
BA_ "GenSigSendType" SG_ 2348810400 MessageChecksum_C0000A0 5;
BA_ "SPN" SG_ 2348814492 EngOverrideCtrlMode_C00009C 695;
BA_ "GenSigSendType" SG_ 2348814492 EngOverrideCtrlMode_C00009C 5;
BA_ "SPN" SG_ 2348814492 EngRqedSpeedCtrlConditions_C00009C 696;
BA_ "GenSigSendType" SG_ 2348814492 EngRqedSpeedCtrlConditions_C00009C 5;
BA_ "SPN" SG_ 2348814492 OverrideCtrlModePriority_C00009C 897;
BA_ "GenSigSendType" SG_ 2348814492 OverrideCtrlModePriority_C00009C 5;
BA_ "SPN" SG_ 2348814492 EngRqedSpeed_SpeedLimit_C00009C 898;
BA_ "GenSigSendType" SG_ 2348814492 EngRqedSpeed_SpeedLimit_C00009C 5;
BA_ "SPN" SG_ 2348814492 EngRqedTorque_TorqueLimit_C00009C 518;
BA_ "GenSigSendType" SG_ 2348814492 EngRqedTorque_TorqueLimit_C00009C 5;
BA_ "SPN" SG_ 2348814492 TransmissionRate_C00009C 3349;
BA_ "GenSigSendType" SG_ 2348814492 TransmissionRate_C00009C 5;
BA_ "SPN" SG_ 2348814492 ControlPurpose_C00009C 3350;
BA_ "GenSigSendType" SG_ 2348814492 ControlPurpose_C00009C 5;
BA_ "SPN" SG_ 2348814492 EngineRequestedTorqueHiRes_C00009C 4191;
BA_ "GenSigSendType" SG_ 2348814492 EngineRequestedTorqueHiRes_C00009C 5;
BA_ "SPN" SG_ 2348814492 MessageCounter_C00009C 4206;
BA_ "GenSigSendType" SG_ 2348814492 MessageCounter_C00009C 5;
BA_ "SPN" SG_ 2348814492 MessageChecksum_C00009C 4207;
BA_ "GenSigSendType" SG_ 2348814492 MessageChecksum_C00009C 5;
BA_ "SPN" SG_ 2349465760 CruiseCtrlDisableCommand 5603;
VAL_ 2566889511 VDCU_ActiveWakeUpBit 1 "Active" 0 "Inactive";
VAL_ 2566889511 VDCU_RepeatMessageRequest 1 "RepeatMessageRequest" 0 "Inactive";
VAL_ 2566889511 VDCU_NMState_RMSfromBSM 1 "RepeatMessageState" 0 "Inactive";
VAL_ 2566889511 VDCU_NMState_RMSfromPBSM 1 "RepeatMessageState" 0 "Inactive";
VAL_ 2566889511 VDCU_NMState_RMSfromNOS 1 "RepeatMessageState" 0 "Inactive";
VAL_ 2566889511 VDCU_NMState_RMSfromRSS 1 "RepeatMessageState" 0 "Inactive";
VAL_ 2566889511 VDCU_NMState_NOSfromRMS 1 "NormalOperationState" 0 "Inactive";
VAL_ 2566889511 VDCU_NMState_NOSfromRSS 1 "NormalOperationState" 0 "Inactive";
VAL_ 2566889511 VDCU_WakeupSource 255 "Reserved" 254 "Reserved" 253 "Reserved" 252 "Reserved" 251 "Reserved" 250 "Reserved" 249 "Reserved" 248 "Reserved" 247 "Reserved" 246 "Reserved" 245 "Reserved" 244 "Reserved" 243 "Reserved" 242 "Reserved" 241 "Reserved" 240 "Reserved" 239 "Reserved" 238 "Reserved" 237 "Reserved" 236 "Reserved" 235 "Reserved" 234 "Reserved" 233 "Reserved" 232 "Reserved" 231 "Reserved" 230 "Reserved" 229 "Reserved" 228 "Reserved" 227 "Reserved" 226 "Reserved" 225 "Reserved" 224 "Reserved" 223 "Reserved" 222 "Reserved" 221 "Reserved" 220 "Reserved" 219 "Reserved" 218 "Reserved" 217 "Reserved" 216 "Reserved" 215 "Reserved" 214 "Reserved" 213 "Reserved" 212 "Reserved" 211 "Reserved" 210 "Reserved" 209 "Reserved" 208 "Reserved" 207 "Reserved" 206 "Reserved" 205 "Reserved" 204 "Reserved" 203 "Reserved" 202 "Reserved" 201 "Reserved" 200 "Reserved" 199 "Reserved" 198 "Reserved" 197 "Reserved" 196 "Reserved" 195 "Reserved" 194 "Reserved" 193 "Reserved" 192 "Reserved" 191 "Reserved" 190 "Reserved" 189 "Reserved" 188 "Reserved" 187 "Reserved" 186 "Reserved" 185 "Reserved" 184 "Reserved" 183 "Reserved" 182 "Reserved" 181 "Reserved" 180 "Reserved" 179 "Reserved" 178 "Reserved" 177 "Reserved" 176 "Reserved" 175 "Reserved" 174 "Reserved" 173 "Reserved" 172 "Reserved" 171 "Reserved" 170 "Reserved" 169 "Reserved" 168 "Reserved" 167 "Reserved" 166 "Reserved" 165 "Reserved" 164 "Reserved" 163 "Reserved" 162 "Reserved" 161 "Reserved" 160 "Reserved" 159 "Reserved" 158 "Reserved" 157 "Reserved" 156 "Reserved" 155 "Reserved" 154 "Reserved" 153 "Reserved" 152 "Reserved" 151 "Reserved" 150 "Reserved" 149 "Reserved" 148 "Reserved" 147 "Reserved" 146 "Reserved" 145 "Reserved" 144 "Reserved" 143 "Reserved" 142 "Reserved" 141 "Reserved" 140 "Reserved" 139 "Reserved" 138 "Reserved" 137 "Reserved" 136 "Reserved" 135 "Reserved" 134 "Reserved" 133 "Reserved" 132 "Reserved" 131 "Reserved" 130 "Reserved" 129 "Reserved" 128 "Reserved" 127 "Reserved" 126 "Reserved" 125 "Reserved" 124 "Reserved" 123 "Reserved" 122 "Reserved" 121 "Reserved" 120 "Reserved" 119 "Reserved" 118 "Reserved" 117 "Reserved" 116 "Reserved" 115 "Reserved" 114 "Reserved" 113 "Reserved" 112 "Reserved" 111 "Reserved" 110 "Reserved" 109 "Reserved" 108 "Reserved" 107 "Reserved" 106 "Reserved" 105 "Reserved" 104 "Reserved" 103 "Reserved" 102 "Reserved" 101 "Reserved" 100 "Reserved" 99 "Reserved" 98 "Reserved" 97 "Reserved" 96 "Reserved" 95 "Reserved" 94 "Reserved" 93 "Reserved" 92 "Reserved" 91 "Reserved" 90 "Reserved" 89 "Reserved" 88 "Reserved" 87 "Reserved" 86 "Reserved" 85 "Reserved" 84 "Reserved" 83 "Reserved" 82 "Reserved" 81 "Reserved" 80 "Reserved" 79 "Reserved" 78 "Reserved" 77 "Reserved" 76 "Reserved" 75 "Reserved" 74 "Reserved" 73 "Reserved" 72 "Reserved" 71 "Reserved" 70 "Reserved" 69 "Reserved" 68 "Reserved" 67 "Reserved" 66 "Reserved" 65 "Reserved" 64 "Reserved" 63 "Reserved" 62 "Reserved" 61 "Reserved" 60 "Reserved" 59 "Reserved" 58 "Reserved" 57 "Reserved" 56 "Reserved" 55 "Reserved" 54 "Reserved" 53 "Reserved" 52 "Reserved" 51 "Reserved" 50 "Reserved" 49 "Reserved" 48 "Reserved" 47 "Reserved" 46 "Reserved" 45 "Reserved" 44 "Reserved" 43 "Reserved" 42 "Reserved" 41 "Reserved" 40 "Reserved" 39 "Reserved" 38 "Reserved" 37 "Reserved" 36 "Reserved" 35 "Reserved" 34 "Reserved" 33 "Reserved" 32 "Reserved" 31 "Reserved" 30 "Reserved" 29 "Reserved" 28 "Reserved" 27 "Reserved" 26 "Reserved" 25 "Reserved" 24 "Reserved" 23 "Reserved" 22 "Reserved" 21 "Reserved" 20 "Reserved" 19 "Reserved" 18 "Reserved" 17 "Reserved" 16 "Reserved" 15 "Reserved" 14 "Reserved" 13 "Reserved" 12 "Reserved" 11 "Reserved" 10 "Reserved" 9 "蓄电池智能补电激活" 8 "电池充电保温" 7 "ACChargeActive" 6 "DCChargeActive" 5 "下电延时监控" 4 "BrakePadelPressed" 3 "LIN WakeupFrame" 2 "Diagnose" 1 "NM PDU Received" 0 "Default";
VAL_ 2566889511 VDCU_NMKpARson_NMPduReceived 1 "Active" 0 "Inactive";
VAL_ 2566889511 VDCU_NMKpARson_TimeOut 1 "Active" 0 "Inactive";
VAL_ 2566889511 VDCU_NMKpARson_Diag 1 "Active" 0 "Inactive";
VAL_ 2566889511 VDCU_NMKpARson_KL15 1 "Active" 0 "Inactive";
VAL_ 2566889511 VDCU_NMKpARson_LINReq 1 "Active" 0 "Inactive";
VAL_ 2566889511 VDCU_NMKpARson_WinCtrl_L 1 "Active" 0 "Inactive";
VAL_ 2566889511 VDCU_NMKpARson_WinCtrl_R 1 "Active" 0 "Inactive";
VAL_ 2566889511 VDCU_NMKpARson_BrakePedalPressed 1 "Active" 0 "Inactive";
VAL_ 2566889511 VDCU_NMKpARson_LowBeamReq 1 "Active" 0 "Inactive";
VAL_ 2566889511 VDCU_NMKpARson_PosnLigjtReq 1 "Active" 0 "Inactive";
VAL_ 2566889511 VDCU_NMKpARson_DCChargeActive 1 "Active" 0 "Inactive";
VAL_ 2566889511 VDCU_NMKpARson_PowerOFFdelayMonitor 1 "Active" 0 "Inactive";
VAL_ 2566889511 VDCU_NMKpARson_ACChargeActive 1 "Active" 0 "Inactive";
VAL_ 2566889511 VDCU_NMKpARson_HVConnected 1 "Active" 0 "Inactive";
VAL_ 2566889511 VDCU_NMKpARson_ChargeWarmer 1 "Active" 0 "Inactive";
VAL_ 2566889511 VDCU_NMKpARson_Ready 1 "Active" 0 "Inactive";
VAL_ 2566889511 VDCU_NMKpARson_SmartCharge 1 "Active" 0 "Inactive";
VAL_ 2566870679 WinCtrlReq_Drvr 6 "NotAvailable" 5 "voice control driver window 100%" 4 "voice control driver window 75%" 3 "voice control driver window 50%" 2 "voice control driver window 25%" 1 "voice control driver window 0%" 0 "No Req";
VAL_ 2566870679 WinCtrlReq_Pass 6 "NotAvailable" 5 "voice control driver window 100%" 4 "voice control driver window 75%" 3 "voice control driver window 50%" 2 "voice control driver window 25%" 1 "voice control driver window 0%" 0 "No Req";
VAL_ 2566870679 WinCtrl_VoiceFlag 1 "Active" 0 "Inactive";
VAL_ 2566870679 IVI_DrSeatHeatSw 7 "Res" 6 "Res" 5 "Res" 4 "Level3" 3 "Level2" 2 "Level1" 1 "OFF" 0 "No Req";
VAL_ 2566870679 IVI_DrSeatWindLevelSet 7 "Res" 6 "Res" 5 "Res" 4 "Level3" 3 "Level2" 2 "Level1" 1 "OFF" 0 "No Req";
VAL_ 2566870679 IVI_DrSeatMassageModSet 15 "Res" 14 "Res" 13 "Res" 12 "Res" 11 "Res" 10 "Res" 9 "Res" 8 "Res" 7 "Res" 6 "Res" 5 "Res" 4 "伸展" 3 "猫步" 2 "波浪" 1 "OFF" 0 "No Req";
VAL_ 2566870679 IVI_HeatlinkageSet 1 "Seat and SteeringWheel Heat" 0 "Seat Heat";
VAL_ 2566870679 IVI_ExtrMirrHeatSwt 3 "Reserved" 2 "ExtrMirrHeatOn" 1 "ExtrMirrHeatOff" 0 "No Req/NotAvailable";
VAL_ 2566870679 IVI_SWS_UserDifined 7 "Reserved" 6 "Reserved" 5 "Reserved" 4 "Reserved" 3 "Reserved" 2 "Fun2 Req" 1 "Fun1 Req" 0 "No Req";
VAL_ 2566870679 IVI_SteerWheelHeatSwt 7 "Reserved" 6 "Reserved" 5 "Reserved" 4 "SWH_Hi" 3 "SWH_Mid" 2 "SWH_Low/On" 1 "OFF" 0 "No Req";
VAL_ 2566900119 IVI_HornShiftSwitch 3 "Reserved" 2 "ElecHorn Enable" 1 "AirHorn Enable" 0 "No Req/Initial";
VAL_ 2566900119 IVI_VehLockRemindSet 3 "Reserved" 2 "Light and Horn" 1 "Light" 0 "No Req/Initial";
VAL_ 2566900119 IVI_LampFollowMeHomeSet 4 "90s" 3 "60s" 2 "30s" 1 "OFF" 0 "No Req/Initial";
VAL_ 2566900119 IVI_LampAwayHomeSet 4 "90s" 3 "60s" 2 "30s" 1 "OFF" 0 "No Req/Initial";
VAL_ 2566900119 IVI_FindMyCarSet 3 "Reserved" 2 "Light and Horn" 1 "Light" 0 "No Req/Initial";
VAL_ 2566900119 IVI_SmartWelcomeSet 2 "Enable" 1 "Disable" 0 "No Req/Initial";
VAL_ 2566900119 IVI_LogoLightSwitch 3 "Res" 2 "OFF" 1 "ON" 0 "Initial";
VAL_ 2566900119 IVI_ADBSwitch 2 "Enable" 1 "Disable" 0 "No Req/Initial";
VAL_ 2566900119 IVI_RainAutoCloseWinSet 2 "Enable" 1 "Disable" 0 "No Req/Initial";
VAL_ 2566900119 IVI_LockAutoCloseWinSet 2 "Enable" 1 "Disable" 0 "No Req/Initial";
VAL_ 2566900119 IVI_UnlockSet 2 "~0xFF Doors Unlock" 1 "Driver Door Unlock" 0 "No Req/Initial";
VAL_ 2566900119 IVI_SpeedAutoLockSet 3 "Enable 8km/h" 2 "Enable 15km/h" 1 "Disable" 0 "No Req/Initial";
VAL_ 2566900119 IVI_StopAutoUnlockSet 2 "Enable" 1 "Disable" 0 "No Req/Initial";
VAL_ 2566900119 IVI_ApproachAutoUnlockSet 2 "Enable" 1 "Disable" 0 "No Req/Initial";
VAL_ 2566900119 IVI_AwayAutoLockSet 2 "Enable" 1 "Disable" 0 "No Req/Initial";
VAL_ 2566900119 IVI_SpeedLimitSet_Sleeper 2 "Enable" 1 "Disable" 0 "No Req/Initial";
VAL_ 2566900119 IVI_WCMEnableSwitch 3 "Reserved" 2 "OFF" 1 "ON(Default)" 0 "No Operation";
VAL_ 2566900119 IVI_BackLightBriSet 10 "100%" 9 "90%" 8 "80%" 7 "70%" 6 "60%" 5 "50%" 4 "40%" 3 "30%" 2 "20%" 1 "10%" 0 "Not Request";
VAL_ 2566900119 CeilingLightSet 2 "ON" 1 "OFF" 0 "No Req/Initial";
VAL_ 2566900119 IVI_VSPOpenSet 3 "Reserved" 2 "ON" 1 "OFF" 0 "No Req/Initial";
VAL_ 2566854039 ExtrMirrorCtrlMode_ 1 "Active" 0 "Inactive";
VAL_ 2566854039 ExtrMirrDirAdjmtSoftSwt_L 4 "TurnRight" 3 "TurnLeft" 2 "TurnDown" 1 "TurnUp" 0 "Inactive";
VAL_ 2566854039 ExtrMirrDirAdjmtSoftSwt_R 4 "TurnRight" 3 "TurnLeft" 2 "TurnDown" 1 "TurnUp" 0 "Inactive";
VAL_ 2566854039 ExtrMirrDirAdjmtLogicSwt_L 7 "Reserved" 6 "Reserved" 5 "Reserved" 4 "L_ExtrMirrTurnRightReq" 3 "L_ExtrMirrTurnLeftReq" 2 "L_ExtrMirrTurnDownReq" 1 "L_ExtrMirrTurnUpReq" 0 "No Req/NotAvailable";
VAL_ 2566854039 ExtrMirrDirAdjmtLogicSwt_R 7 "Reserved" 6 "Reserved" 5 "Reserved" 4 "R_ExtrMirrTurnRightReq" 3 "R_ExtrMirrTurnLeftReq" 2 "R_ExtrMirrTurnDownReq" 1 "R_ExtrMirrTurnUpReq" 0 "No Req/NotAvailable";
VAL_ 2566854039 CMS_TemporaryViewSwt 7 "Reserved" 6 "Reserved" 5 "Reserved" 4 "ON_both" 3 "ON_reverse" 2 "ON_turn" 1 "OFF" 0 "Initial/NoReq/NotAvailable";
VAL_ 2566854039 CMS_BrightnessAdjMod 3 "Reserved" 2 "Auto Mode" 1 "Manual Mode" 0 "Inial/NoReq/NotAvailable";
VAL_ 2566854039 CMS_DefaultView_R 3 "Reserved" 2 "Reserved" 1 "Req" 0 "No Req/NotAvailable";
VAL_ 2566854039 CMS_DefaultView 3 "Reserved" 2 "Reserved" 1 "Req" 0 "No Req/NotAvailable";
VAL_ 2566854039 CMS_BrightnessAdj 15 "Reserved" 14 "Reserved" 13 "Reserved" 12 "Reserved" 11 "Reserved" 10 "10档" 9 "9档" 8 "8档" 7 "7档" 6 "6档" 5 "5档" 4 "4档" 3 "3档" 2 "2档" 1 "1档" 0 "NoReq/NotAvailable";
VAL_ 2566854039 CMS_AuxiliaryLines_Enable 3 "Reserved" 2 "AuxiliaryLines OFF" 1 "AuxiliaryLines ON" 0 "NoReq/NotAvailable";
VAL_ 2566854039 CMS_AuxiliaryLines 3 "Reserved" 2 "Down" 1 "Up" 0 "NoReq/NotAvailable";
VAL_ 2566907927 CDCU_MLS_Page 15 "Reserved" 14 "Reserved" 13 "Reserved" 12 "Reserved" 11 "Reserved" 10 "Reserved" 9 "Reserved" 8 "Reserved" 7 "Reserved" 6 "Reserved" 5 "Reserved" 4 "Reserved" 3 "Reserved" 2 "Reserved" 1 "Reserved" 0 "Field definations as defined";
VAL_ 2566907927 CDCU_MLS_truck_trailer 3 "Reserved" 2 "Reserved" 1 "trailer use" 0 "tractor use";
VAL_ 2566907927 CDCU_MLS 15 "Reserved" 14 "Reserved" 13 "Reserved" 12 "Reserved" 11 "Reserved" 10 "Reserved" 9 "Reserved" 8 "Reserved" 7 "Reserved" 6 "Reserved" 5 "Reserved" 4 "Reserved" 3 "Reserved" 2 "Active" 1 "Inactive" 0 "Not request";
VAL_ 2566907927 CDCU_MLS_Tyre_Loc 58 "Location 0x3A-axle 3 OR" 57 "Location 0x39-axle 3 IR" 25 "Location 0x19-axle 1 IR" 55 "Location 0x37-axle 3 IL" 23 "Location 0x17-axle 1 IL" 54 "Location 0x36-axle 3 OL" 74 "Location 0x4A-axle 4 OR" 42 "Location 0x2A-axle 2 OR" 73 "Location 0x49-axle 4 IR" 41 "Location 0x29-axle 2 IR" 71 "Location 0x47-axle 4 IL" 39 "Location 0x27-axle 2 IL" 70 "Location 0x46-axle 4 OL" 38 "Location 0x26-axle 2 OL";
VAL_ 2566723351 DriverBeltlockStatus 3 "Not available" 2 "Error" 1 "locked" 0 "unlocked";
VAL_ 2566723351 PassengerBeltlockStatus 3 "Not available" 2 "Error" 1 "locked" 0 "unlocked";
VAL_ 2566850171 DMS_SeatShakeSts 7 "Reserved" 6 "Reserved" 5 "Reserved" 4 "Req_LV4_alwayson" 3 "Req_LV3_0.25son0.25soffasaperiod" 2 "Req_LV2_0.5son0.5soffasaperiod" 1 "Req_LV1_1son1soffasaperiod" 0 "No Request";
VAL_ 2566905239 IVI_ACOffSwt 3 "Reserved" 2 "ON" 1 "OFF" 0 "No Req";
VAL_ 2566905239 IVI_ACAutoSwt 3 "Reserved" 2 "ON" 1 "OFF" 0 "No Req";
VAL_ 2566905239 IVI_ACModeMotorSwt 7 "Reserved" 6 "Reserved" 5 "Defrost" 4 "Foot&Defrost" 3 "Foot" 2 "Face&Foot" 1 "Face" 0 "No Req";
VAL_ 2566905239 IVI_ACACSwt 3 "Reserved" 2 "ON" 1 "OFF" 0 "No Req";
VAL_ 2566905239 IVI_ACPTCSwt 3 "Reserved" 2 "ON" 1 "OFF" 0 "No Req";
VAL_ 2566905239 IVI_ACCycleMotorSwt 3 "Reserved" 2 "Outside Cycle" 1 "Inside Cycle" 0 "No Req";
VAL_ 2566905239 IVI_ACFrontDefrostSwt 3 "Reserved" 2 "ON" 1 "OFF" 0 "No Req";
VAL_ 2566905239 IVI_ACTempPlusSwt 1 "Plus" 0 "Not Req";
VAL_ 2566905239 IVI_ACTempMinusSwt 1 "Minus" 0 "Not Req";
VAL_ 2566905239 IVI_ACTempLevelSwt 63 "Reserved" 62 "Reserved" 61 "Reserved" 60 "Reserved" 59 "Reserved" 58 "Reserved" 57 "Reserved" 56 "Reserved" 55 "Reserved" 54 "Reserved" 53 "Reserved" 52 "Reserved" 51 "Reserved" 50 "Reserved" 49 "Reserved" 48 "Reserved" 47 "Reserved" 46 "Reserved" 45 "Reserved" 44 "Reserved" 43 "Reserved" 42 "Reserved" 41 "Reserved" 40 "Reserved" 39 "Reserved" 38 "Reserved" 37 "Reserved" 36 "Reserved" 35 "Reserved" 34 "Reserved" 33 "Reserved" 32 "Reserved" 31 "32℃" 30 "31.5℃" 29 "31℃" 28 "30.5℃" 27 "30℃" 26 "29.5℃" 25 "29℃" 24 "28.5℃" 23 "28℃" 22 "27.5℃" 21 "27℃" 20 "26.5℃" 19 "26℃" 18 "25.5" 17 "25℃" 16 "24.5℃" 15 "24℃" 14 "23.5℃" 13 "23℃" 12 "22.5℃" 11 "22℃" 10 "21.5℃" 9 "21℃" 8 "20.5℃" 7 "20℃" 6 "19.5℃" 5 "19℃" 4 "18.5℃" 3 "18℃" 2 "17.5℃" 1 "17℃" 0 "No Req";
VAL_ 2566905239 IVI_ACBlowerLvlSeltSwt 15 "Reserved" 14 "Reserved" 13 "Reserved" 12 "Reserved" 11 "Reserved" 10 "Reserved" 9 "Reserved" 8 "7" 7 "6" 6 "5" 5 "4" 4 "3" 3 "2" 2 "1" 1 "Off" 0 "No Req";
VAL_ 2566905239 IVI_LonizerSwt 3 "Reserved" 2 "ON" 1 "OFF" 0 "No Req";
VAL_ 2566905239 IVI_AirPurgeSwt 3 "Reserved" 2 "ON" 1 "OFF" 0 "No Req";
VAL_ 2566905239 IVI_AcMaxSwt 3 "Reserved" 2 "ON" 1 "OFF" 0 "No Req";
VAL_ 2566905239 IVI_HeatingMaxSwt 3 "Reserved" 2 "ON" 1 "OFF" 0 "No Req";
VAL_ 2566905239 IVI_TempZoneSyncSwt 3 "Reserved" 2 "Sync" 1 "Not Sync" 0 "No Req";
VAL_ 2566905239 IVI_ACBlowerLvlSeltSwt_Slpr 15 "Reserved" 14 "Reserved" 13 "Reserved" 12 "Reserved" 11 "Reserved" 10 "Reserved" 9 "Reserved" 8 "7" 7 "6" 6 "5" 5 "4" 4 "3" 3 "2" 2 "1" 1 "Off" 0 "No Req";
VAL_ 2566905239 IVI_ACTempPlusSwt_Slpr 1 "Plus" 0 "Not Req";
VAL_ 2566905239 IVI_ACTempMinusSwt_Slpr 1 "Minus" 0 "Not Req";
VAL_ 2566905239 IVI_ACTempLevelSwt_Slpr 63 "Reserved" 62 "Reserved" 61 "Reserved" 60 "Reserved" 59 "Reserved" 58 "Reserved" 57 "Reserved" 56 "Reserved" 55 "Reserved" 54 "Reserved" 53 "Reserved" 52 "Reserved" 51 "Reserved" 50 "Reserved" 49 "Reserved" 48 "Reserved" 47 "Reserved" 46 "Reserved" 45 "Reserved" 44 "Reserved" 43 "Reserved" 42 "Reserved" 41 "Reserved" 40 "Reserved" 39 "Reserved" 38 "Reserved" 37 "Reserved" 36 "Reserved" 35 "Reserved" 34 "Reserved" 33 "Reserved" 32 "Reserved" 31 "32℃" 30 "31.5℃" 29 "31℃" 28 "30.5℃" 27 "30℃" 26 "29.5℃" 25 "29℃" 24 "28.5℃" 23 "28℃" 22 "27.5℃" 21 "27℃" 20 "26.5℃" 19 "26℃" 18 "25.5" 17 "25℃" 16 "24.5℃" 15 "24℃" 14 "23.5℃" 13 "23℃" 12 "22.5℃" 11 "22℃" 10 "21.5℃" 9 "21℃" 8 "20.5℃" 7 "20℃" 6 "19.5℃" 5 "19℃" 4 "18.5℃" 3 "18℃" 2 "17.5℃" 1 "17℃" 0 "No Req";
VAL_ 2566905239 IVI_ACBlowerPlusSwt_Slpr 1 "Plus" 0 "Not Req";
VAL_ 2566905239 IVI_ACBlowerMinusSwt_Slpr 1 "Minus" 0 "Not Req";
VAL_ 2566905239 IVI_ACBlowerLvlMinusSwt 1 "Minus" 0 "Not Req";
VAL_ 2566905239 IVI_ACOffSwt_Slpr 3 "Reserved" 2 "ON" 1 "OFF" 0 "No Req";
VAL_ 2566905239 IVI_ACTimingRunSwt_Slpr 3 "Reserved" 2 "ON" 1 "OFF" 0 "No Req";
VAL_ 2566854551 WheelDifferentialLock_Sw 2 "On" 1 "Off" 0 "No Req";
VAL_ 2566854551 AxleDifferentialLockSwt 3 "Not available" 2 "Error" 1 "Work" 0 "Not work";
VAL_ 2566854551 V2V_Sw 2 "On" 1 "Off" 0 "No Req";
VAL_ 2566854551 V2G_Sw 2 "On" 1 "Off" 0 "No Req";
VAL_ 2566854551 BattIIntlgntRecharge_Set 2 "On" 1 "Off" 0 "No Req";
VAL_ 2566854551 IVI_220VSocket_Sw 2 "On" 1 "Off" 0 "No Req";
VAL_ 2566854551 EnergyMode_Set 2 "FCV" 1 "EV" 0 "No Req";
VAL_ 2566854551 IVI_VehicleCreepSet 2 "On" 1 "Off" 0 "No Req";
VAL_ 2566854551 IVI_VehicleDragModeSet 2 "On" 1 "Off" 0 "No Req";
VAL_ 2566854551 IVI_EPModeSet 15 "Reserved" 14 "Reserved" 13 "Reserved" 12 "Reserved" 11 "Reserved" 10 "Reserved" 9 "Reserved" 8 "Reserved" 7 "Reserved" 6 "Reserved" 5 "Reserved" 4 "Reserved" 3 "SportMode" 2 "ECOMode" 1 "NormalMode" 0 "No Req";
VAL_ 2566854551 IVI_ServiceModeSet 3 "Reserved" 2 "On" 1 "Off" 0 "No Req";
VAL_ 2566854551 IVI_DrivngMileageDisplaySet 7 "Reserved" 6 "Reserved" 5 "Reserved" 4 "CHTC工况里程" 3 "WLTC工况里程" 2 "CLTC工况里程" 1 "动态里程；" 0 "No Req；";
VAL_ 2566850711 IVI_ChargingKeepWarmSet 2 "On" 1 "Off" 0 "No Req";
VAL_ 2566850711 IVI_HeatByApntmntSet 2 "On" 1 "Off" 0 "No Req";
VAL_ 2566850711 IVI_HeatByApntmntReplicationSet 2 "Replication" 1 "No Replication" 0 "No Req";
VAL_ 2566850711 IVI_HeatByApntmntHourStart 31 "Invalid";
VAL_ 2566850711 IVI_HeatByApntmntMinuteStart 63 "Invalid";
VAL_ 2566850711 IVI_ChargngByApntmntSet 2 "On" 1 "Off" 0 "No Req";
VAL_ 2566850711 IVI_ChargngByApntmntHourStart 31 "Invalid";
VAL_ 2566850711 IVI_ImmediatStartChargngSet 3 "Reserved" 2 "Reserved" 1 "请求立即充电" 0 "No Req";
VAL_ 2566850711 IVI_ChargngByApntmntMinuteStart 63 "Invalid";
VAL_ 2566850711 IVI_ChargngByApntmntReplicationSet 2 "No Replication" 1 "Replication" 0 "No Req";
VAL_ 2566850711 IVI_ChargngByApntmntHourEnd 31 "Invalid" 30 "FullCharge";
VAL_ 2566850711 IVI_ChargngByApntmntMinuteEnd 31 "Invalid" 62 "FullCharge";
VAL_ 2566850711 IVI_ChargingStopSwt 3 "Reserved" 2 "Reserved" 1 "请求充电停止" 0 "No Req";
VAL_ 2566853015 IVI_Sw_StopDCDisCharging 3 "Reserved" 2 "开启" 1 "关闭" 0 "Not Request";
VAL_ 2566865177 ACTempLevelDisp 63 "Reserved" 62 "Reserved" 61 "Reserved" 60 "Reserved" 59 "Reserved" 58 "Reserved" 57 "Reserved" 56 "Reserved" 55 "Reserved" 54 "Reserved" 53 "Reserved" 52 "Reserved" 51 "Reserved" 50 "Reserved" 49 "Reserved" 48 "Reserved" 47 "Reserved" 46 "Reserved" 45 "Reserved" 44 "Reserved" 43 "Reserved" 42 "Reserved" 41 "Reserved" 40 "Reserved" 39 "Reserved" 38 "Reserved" 37 "Reserved" 36 "Reserved" 35 "Reserved" 34 "Reserved" 33 "Reserved" 32 "Reserved" 31 "32℃" 30 "31.5℃" 29 "31℃" 28 "30.5℃" 27 "30℃" 26 "29.5℃" 25 "29℃" 24 "28.5℃" 23 "28℃" 22 "27.5℃" 21 "27℃" 20 "26.5℃" 19 "26℃" 18 "25.5" 17 "25℃" 16 "24.5℃" 15 "24℃" 14 "23.5℃" 13 "23℃" 12 "22.5℃" 11 "22℃" 10 "21.5℃" 9 "21℃" 8 "20.5℃" 7 "20℃" 6 "19.5℃" 5 "19℃" 4 "18.5℃" 3 "18℃" 2 "17.5℃" 1 "17℃" 0 "TakeNoAction";
VAL_ 2566865177 ACPTCDisp 3 "Reserved" 2 "On" 1 "Off" 0 "TakeNoAction";
VAL_ 2566865177 ACTempLevelCtrl 63 "Reserved" 62 "Reserved" 61 "Reserved" 60 "Reserved" 59 "Reserved" 58 "Reserved" 57 "Reserved" 56 "Reserved" 55 "Reserved" 54 "Reserved" 53 "Reserved" 52 "Reserved" 51 "Reserved" 50 "Reserved" 49 "Reserved" 48 "Reserved" 47 "Reserved" 46 "Reserved" 45 "Reserved" 44 "Reserved" 43 "Reserved" 42 "Reserved" 41 "Reserved" 40 "Reserved" 39 "Reserved" 38 "Reserved" 37 "Reserved" 36 "Reserved" 35 "Reserved" 34 "Reserved" 33 "Reserved" 32 "Reserved" 31 "32℃" 30 "31.5℃" 29 "31℃" 28 "30.5℃" 27 "30℃" 26 "29.5℃" 25 "29℃" 24 "28.5℃" 23 "28℃" 22 "27.5℃" 21 "27℃" 20 "26.5℃" 19 "26℃" 18 "25.5" 17 "25℃" 16 "24.5℃" 15 "24℃" 14 "23.5℃" 13 "23℃" 12 "22.5℃" 11 "22℃" 10 "21.5℃" 9 "21℃" 8 "20.5℃" 7 "20℃" 6 "19.5℃" 5 "19℃" 4 "18.5℃" 3 "18℃" 2 "17.5℃" 1 "17℃" 0 "No Cmd";
VAL_ 2566865177 ACModeMotorDisp 7 "Reserved" 6 "Auto" 5 "Defrost" 4 "Foot&Defrost" 3 "Foot" 2 "Face&Foot" 1 "Face" 0 "TakeNoAction";
VAL_ 2566865177 ACModeMotorCtrl 7 "Reserved" 6 "Reserved" 5 "Defrost" 4 "Foot&Defrost" 3 "Foot" 2 "Face&Foot" 1 "Face" 0 "No Cmd";
VAL_ 2566865177 ACCycleMotorDisp 3 "Auto" 2 "Outside Cycle" 1 "Inside Cycle" 0 "TakeNoAction";
VAL_ 2566865177 ACCycleMotorPosnCtrl 3 "Reserved" 2 "Outside Cycle" 1 "Inside Cycle" 0 "No Cmd";
VAL_ 2566865177 ACBlowerLevelDisp 15 "Reserved" 14 "Reserved" 13 "Reserved" 12 "Reserved" 11 "Reserved" 10 "Reserved" 9 "Auto" 8 "7" 7 "6" 6 "5" 5 "4" 4 "3" 3 "2" 2 "1" 1 "Off" 0 "TakeNoAction";
VAL_ 2566865177 ACBlowerLevelCtrl 15 "Reserved" 14 "Reserved" 13 "Reserved" 12 "Reserved" 11 "Reserved" 10 "Reserved" 9 "Reserved" 8 "7" 7 "6" 6 "5" 5 "4" 4 "3" 3 "2" 2 "1" 1 "Off" 0 "No Cmd";
VAL_ 2566865177 ACFrontDefrostDisp 3 "Reserved" 2 "On" 1 "Off" 0 "TakeNoAction";
VAL_ 2566865177 ACAcDisp 3 "Reserved" 2 "On" 1 "Off" 0 "TakeNoAction";
VAL_ 2566865177 ACMaxDisp 3 "Reserved" 2 "On" 1 "Off" 0 "TakeNoAction";
VAL_ 2566865177 ACAutoDisp 3 "Reserved" 2 "On" 1 "Off" 0 "TakeNoAction";
VAL_ 2566865177 ACOffDisp 3 "Reserved" 2 "On" 1 "Off" 0 "TakeNoAction";
VAL_ 2566865177 ACAirPurgeDisp 3 "Reserved" 2 "On" 1 "Off" 0 "TakeNoAction";
VAL_ 2566865177 ACAirPurgeCtrl 3 "Reserved" 2 "On" 1 "Off" 0 "No Cmd";
VAL_ 2566865177 ACLonizerDisp 3 "Reserved" 2 "On" 1 "Off" 0 "TakeNoAction";
VAL_ 2566865177 ACLonizerCtrl 3 "Reserved" 2 "On" 1 "Off" 0 "No Cmd";
VAL_ 2566865177 AC_TempZoneSyncSts 3 "Reserved" 2 "Sync On" 1 "Sync Off" 0 "TakeNoAction";
VAL_ 2566865177 AC_HeatingMaxSts 3 "Reserved" 2 "On" 1 "Off" 0 "TakeNoAction";
VAL_ 2566865177 ElecACTempLevelDisp 31 "Reserved" 30 "Reserved" 29 "Reserved" 28 "Reserved" 27 "Reserved" 26 "Reserved" 25 "Reserved" 24 "Reserved" 23 "Reserved" 22 "Reserved" 21 "Reserved" 20 "Reserved" 19 "Reserved" 18 "Reserved" 17 "Reserved" 16 "Warm Level_8" 15 "Warm Level_7" 14 "Warm Level_6" 13 "Warm Level_5" 12 "Warm Level_4" 11 "Warm Level_3" 10 "Warm Level_2" 9 "Warm Level_1" 8 "Cold Level_1" 7 "Cold Level_2" 6 "Cold Level_3" 5 "Cold Level_4" 4 "Cold Level_5" 3 "Cold Level_6" 2 "Cold Level_7" 1 "Cold Level_8" 0 "TakeNoAction";
VAL_ 2566868505 HVPowerOnReq_HBattFan 3 "Reserved" 2 "Reserved" 1 "HV On Req" 0 "No Req";
VAL_ 2566868505 HVPowerOnReq_HMotorFan 3 "Reserved" 2 "Reserved" 1 "HV On Req" 0 "No Req";
VAL_ 2566868505 HVPowerOnReq_EAS1 3 "Reserved" 2 "Reserved" 1 "HV On Req" 0 "No Req";
VAL_ 2566868505 HVPowerOnReq_EAS2 3 "Reserved" 2 "Reserved" 1 "HV On Req" 0 "No Req";
VAL_ 2566868505 HVPowerOnReq_EAS3 3 "Reserved" 2 "Reserved" 1 "HV On Req" 0 "No Req";
VAL_ 2566868505 HVPowerOnReq_WPTC1 3 "Reserved" 2 "Reserved" 1 "HV On Req" 0 "No Req";
VAL_ 2566868505 HVPowerOnReq_WPTC2 3 "Reserved" 2 "Reserved" 1 "HV On Req" 0 "No Req";
VAL_ 2566868505 HVPowerOnReq_WPTC3 3 "Reserved" 2 "Reserved" 1 "HV On Req" 0 "No Req";
VAL_ 2566868505 HVPowerOnReq_APTC 3 "Reserved" 2 "Reserved" 1 "HV On Req" 0 "No Req";
VAL_ 2566865433 ACTempLevelDispSlpr 63 "Reserved" 62 "Reserved" 61 "Reserved" 60 "Reserved" 59 "Reserved" 58 "Reserved" 57 "Reserved" 56 "Reserved" 55 "Reserved" 54 "Reserved" 53 "Reserved" 52 "Reserved" 51 "Reserved" 50 "Reserved" 49 "Reserved" 48 "Reserved" 47 "Reserved" 46 "Reserved" 45 "Reserved" 44 "Reserved" 43 "Reserved" 42 "Reserved" 41 "Reserved" 40 "Reserved" 39 "Reserved" 38 "Reserved" 37 "Reserved" 36 "Reserved" 35 "Reserved" 34 "Reserved" 33 "Reserved" 32 "Reserved" 31 "32℃" 30 "31.5℃" 29 "31℃" 28 "30.5℃" 27 "30℃" 26 "29.5℃" 25 "29℃" 24 "28.5℃" 23 "28℃" 22 "27.5℃" 21 "27℃" 20 "26.5℃" 19 "26℃" 18 "25.5" 17 "25℃" 16 "24.5℃" 15 "24℃" 14 "23.5℃" 13 "23℃" 12 "22.5℃" 11 "22℃" 10 "21.5℃" 9 "21℃" 8 "20.5℃" 7 "20℃" 6 "19.5℃" 5 "19℃" 4 "18.5℃" 3 "18℃" 2 "17.5℃" 1 "17℃" 0 "TakeNoAction";
VAL_ 2566865433 ACTempLevelCtrl_Slpr 63 "Reserved" 62 "Reserved" 61 "Reserved" 60 "Reserved" 59 "Reserved" 58 "Reserved" 57 "Reserved" 56 "Reserved" 55 "Reserved" 54 "Reserved" 53 "Reserved" 52 "Reserved" 51 "Reserved" 50 "Reserved" 49 "Reserved" 48 "Reserved" 47 "Reserved" 46 "Reserved" 45 "Reserved" 44 "Reserved" 43 "Reserved" 42 "Reserved" 41 "Reserved" 40 "Reserved" 39 "Reserved" 38 "Reserved" 37 "Reserved" 36 "Reserved" 35 "Reserved" 34 "Reserved" 33 "Reserved" 32 "Reserved" 31 "32℃" 30 "31.5℃" 29 "31℃" 28 "30.5℃" 27 "30℃" 26 "29.5℃" 25 "29℃" 24 "28.5℃" 23 "28℃" 22 "27.5℃" 21 "27℃" 20 "26.5℃" 19 "26℃" 18 "25.5" 17 "25℃" 16 "24.5℃" 15 "24℃" 14 "23.5℃" 13 "23℃" 12 "22.5℃" 11 "22℃" 10 "21.5℃" 9 "21℃" 8 "20.5℃" 7 "20℃" 6 "19.5℃" 5 "19℃" 4 "18.5℃" 3 "18℃" 2 "17.5℃" 1 "17℃" 0 "TakeNoAction";
VAL_ 2566865433 ACBlowerLevelDisp_Slpr 15 "Reserved" 14 "Reserved" 13 "Reserved" 12 "Reserved" 11 "Reserved" 10 "Reserved" 9 "Auto" 8 "7" 7 "6" 6 "5" 5 "4" 4 "3" 3 "2" 2 "1" 1 "Off" 0 "TakeNoAction";
VAL_ 2566865433 ACBlowerLevelCtrl_Slpr 15 "Reserved" 14 "Reserved" 13 "Reserved" 12 "Reserved" 11 "Reserved" 10 "Reserved" 9 "Reserved" 8 "7" 7 "6" 6 "5" 5 "4" 4 "3" 3 "2" 2 "1" 1 "Off" 0 "No Cmd";
VAL_ 2566865433 ACTimingRunDisp_Slpr 3 "Reserved" 2 "On" 1 "Off" 0 "TakeNoAction";
VAL_ 2566865433 ACOffDisp_Slpr 3 "Reserved" 2 "On" 1 "Off" 0 "TakeNoAction";
VAL_ 2566865433 ESC_PTC_LowRelayCtrl 3 "Reserved" 2 "Close" 1 "Open" 0 "TakeNoAction";
VAL_ 2566865433 FAN_LowRelayCtrl 3 "Reserved" 2 "Close" 1 "Open" 0 "TakeNoAction";
VAL_ 2566865433 Blower_RelayCtrl 3 "Reserved" 2 "Close" 1 "Open" 0 "TakeNoAction";
VAL_ 2566865433 Blower_RelayCtrl_Slpr 3 "Reserved" 2 "Close" 1 "Open" 0 "TakeNoAction";
VAL_ 2566865433 BattPump_RelayCtrl 3 "Reserved" 2 "Close" 1 "Open" 0 "TakeNoAction";
VAL_ 2566865433 WarmPump_RelayCtrl 3 "Reserved" 2 "Close" 1 "Open" 0 "TakeNoAction";
VAL_ 2566865433 DrivePump_RelayCtrl 3 "Reserved" 2 "Close" 1 "Open" 0 "TakeNoAction";
VAL_ 2566865433 SOVFront_Ctrl 1 "On" 0 "Off";
VAL_ 2566865433 SOVRear_Ctrl 1 "On" 0 "Off";
VAL_ 2566865433 Wasteheat_use_2way_SOV 3 "Reserved" 2 "Close" 1 "Open" 0 "TakeNoAction";
VAL_ 2566865433 Temp_Ambt_Accurate 255 "Invalid";
VAL_ 2566865689 EAC1_ACFrontDefrostSysSts 3 "Reserved" 2 "PotentialFailures" 1 "Fault" 0 "Normal";
VAL_ 2566865689 EAC2_ACFrontDefrostSysSts 3 "Reserved" 2 "PotentialFailures" 1 "Fault" 0 "Normal";
VAL_ 2566866713 FrontHVACSts 7 "通风" 6 "混合制热" 5 "氢堆余热利用制热" 4 "除霜除雾" 3 "WPTC制热" 2 "热泵制热" 1 "制冷" 0 "无请求";
VAL_ 2566866713 RearHVACSts 6 "通风" 5 "混合制热" 4 "氢堆余热利用制热" 3 "WPTC制热" 2 "热泵制热" 1 "制冷" 0 "无请求";
VAL_ 2566866713 LiquidColdOrHeatingMode 3 "制热模式；" 2 "制冷模式；" 1 "自循环模式；" 0 "未请求；";
VAL_ 2566866713 BTMSSts 7 "电堆余热利用加热" 6 "WPTC加热" 5 "热泵+WPTC加热" 4 "电池余热利用" 3 "主动冷却" 2 "被动冷却" 1 "自循环" 0 "无请求";
VAL_ 2566866713 FuelcellTMSts 3 "Reserved" 2 "电堆加热" 1 "电堆冷却" 0 "无请求";
VAL_ 2566866713 MotorcoolingSts 3 "Reserved" 2 "电机余热利用" 1 "风扇冷却" 0 "无请求";
VAL_ 2566908234 VehicleID_Tbox 3 "Package 3" 2 "Package 2" 1 "Package 1";
VAL_ 2566907210 AwakeNetwork 3 "NotUsed" 2 "NotUsed" 1 "Wkakeup" 0 "NoCommand";
VAL_ 2566907210 TBOX_ACTempLevelReq_TM1 63 "Reserved" 62 "Reserved" 61 "Reserved" 60 "Reserved" 59 "Reserved" 58 "Reserved" 57 "Reserved" 56 "Reserved" 55 "Reserved" 54 "Reserved" 53 "Reserved" 52 "Reserved" 51 "Reserved" 50 "Reserved" 49 "Reserved" 48 "Reserved" 47 "Reserved" 46 "Reserved" 45 "Reserved" 44 "Reserved" 43 "Reserved" 42 "Reserved" 41 "Reserved" 40 "Reserved" 39 "Reserved" 38 "Reserved" 37 "Reserved" 36 "Reserved" 35 "Reserved" 34 "Reserved" 33 "Reserved" 32 "Reserved" 31 "32℃" 30 "31.5℃" 29 "31℃" 28 "30.5℃" 27 "30℃" 26 "29.5℃" 25 "29℃" 24 "28.5℃" 23 "28℃" 22 "27.5℃" 21 "27℃" 20 "26.5℃" 19 "26℃" 18 "25.5" 17 "25℃" 16 "24.5℃" 15 "24℃" 14 "23.5℃" 13 "23℃" 12 "22.5℃" 11 "22℃" 10 "21.5℃" 9 "21℃" 8 "20.5℃" 7 "20℃" 6 "19.5℃" 5 "19℃" 4 "18.5℃" 3 "18℃" 2 "17.5℃" 1 "17℃" 0 "No Req";
VAL_ 2566907210 TBOX_ACFrontDefrostReq_TM1 3 "Reserved" 2 "On" 1 "Off" 0 "No Req";
VAL_ 2566907210 TBOX_Cockpit_Cleaning_TM1 3 "Reserved" 2 "On" 1 "Off" 0 "No Req";
VAL_ 2566907210 TBOX_AcMaxSwt 3 "Reserved" 2 "ON" 1 "OFF" 0 "No Req";
VAL_ 2566907210 TBOX_HeatingMaxSwt 3 "Reserved" 2 "ON" 1 "OFF" 0 "No Req";
VAL_ 2566907210 TBOX_DrSeatHeatSw 7 "Res" 6 "Res" 5 "Res" 4 "Level3" 3 "Level2" 2 "Level1" 1 "OFF" 0 "No Req";
VAL_ 2566907210 TBOX_SteerWheelHeatSwt 7 "Reserved" 6 "Reserved" 5 "Reserved" 4 "SWH_Hi" 3 "SWH_Mid" 2 "SWH_Low/On" 1 "OFF" 0 "No Req";
VAL_ 2566907210 TBOX_DCChargingByApntmnReplication_St 2 "Replication每天" 1 "No Replication单次" 0 "Off未设置";
VAL_ 2566907210 TBOX_ChargngByApntmntHourEndFb 62 "表示设置为充满";
VAL_ 2566907210 TBOX_ChargngByApntmntMinuteEndFb 62 "表示设置为充满";
VAL_ 2566909258 TBOX_RemoteReqFlag 1 "Active" 0 "Inactive";
VAL_ 2566901834 TBOX_4_Discharge_St 3 "Reserved" 2 "开启" 1 "关闭" 0 "Inactive (Not Request)";
VAL_ 2566901834 TBOX4_ChargingKeepWarmSet_St 3 "Reserved" 2 "开启" 1 "关闭" 0 "Inactive (Not Request)";
VAL_ 2566901834 TBOX4_DisChargingStop_St 3 "Reserved" 2 "开启" 1 "关闭" 0 "Inactive (Not Request)";
VAL_ 2566901834 TBOX4_N_ExternalDischargeAppointmentForPickupMinutes 63 "Off未设置";
VAL_ 2566901834 TBOX4_N_ExternalDischargeAppointmentForPickupHours 31 "Off未设置";
VAL_ 2566901834 TBOX4_V2L_St 3 "Reserved" 2 "开启" 1 "关闭" 0 "Inactive (Not Request)";
VAL_ 2566902602 TBOX5_DCChargingByApntmnt_St 3 "Reserved" 2 "开启" 1 "关闭" 0 "Inactive (Not Request)";
VAL_ 2566902602 TBOX5_InstantCharging_St 3 "Reserved" 2 "开启" 1 "关闭" 0 "Inactive (Not Request)";
VAL_ 2566902602 TBOX5_ChargingStop_St 3 "Reserved" 2 "开启" 1 "关闭" 0 "Inactive (Not Request)";
VAL_ 2566908199 VehicleID_VDCU 3 "Package 3" 2 "Package 2" 1 "Package 1";
VAL_ 2566907943 VDCU_St_AuthenticationResultResponse 3 "不关心" 2 "握手超时" 1 "握手成功" 0 "握手失败";
VAL_ 2566907943 ValidDKM 1 "Valid" 0 "Invalid";
VAL_ 2566862831 VBUS_VCU1_St_AutoMode 1 "自动驾驶" 0 "人工驾驶";
VAL_ 2566862831 VBUS_VCU1_St_APS_STA 1 "加速踏板踩下" 0 "加速踏板未踩下";
VAL_ 2566858479 VBUS_VCU6_F_BpSynFlt_Fault 1 "故障" 0 "正常";
VAL_ 2566856687 VBUS_VCU3_St_DRIVE_MODE 15 "void" 14 "void" 13 "void" 12 "void" 11 "void" 10 "void" 9 "void" 8 "void" 7 "void" 6 "void" 5 "void" 4 "强制节能模式；" 3 "运动模式；" 2 "节能（ECO）模式" 1 "标准模式 :" 0 "默认值；";
VAL_ 2566856687 VBUS_VCU3_St_Isolation_clc 1 "车辆存在绝缘故障，请检修" 0 "正常";
VAL_ 2566856687 VBUS_VCU3_St_Vehicle_stop 2 "车辆故障，请立即停车" 1 "车辆故障，请停车" 0 "正常";
VAL_ 2566858223 VBUS_VCU7_BiOBC_HVIL_Err 1 "故障" 0 "正常";
VAL_ 2566858223 VBUS_VCU7_HVAccS_HVIL_Err 1 "故障" 0 "正常";
VAL_ 2566858223 VBUS_VCU7_Gear1_Indicator 1 "显示文字“车速过高，已启用N挡，请重新挂挡”" 0 "不显示";
VAL_ 2566858223 VBUS_VCU7_BRAKE_ENGERY_RECOV_LEVEL 7 "void" 6 "恒速挡" 5 "5挡辅助制动能量回收" 4 "4挡辅助制动能量回收" 3 "3挡辅助制动能量回收" 2 "2挡辅助制动能量回收" 1 "1挡辅助制动能量回收" 0 "未设置";
VAL_ 2566858223 VBUS_VCU7_Restricted_Warning 7 "void" 6 "void" 5 "void" 4 "锁车命令已执行，限速20km/h" 3 "防拆策略已执行，限速20km/h" 2 "解锁命令执行，将在车辆下一次启动时执行" 1 "锁车命令执行，将在车辆下一次启动时执行" 0 "默认值";
VAL_ 2566858223 VBUS_VCU7_St_LV_Chrg 3 "void" 2 "void" 1 "补电中" 0 "未进行补电";
VAL_ 2566858223 VBUS_VCU7_IMCUO_422_ready 1 "使能打开（ready）" 0 "使能关闭（not ready）";
VAL_ 2566858223 VBUS_VCU7_MTCU_HVIL_Err 1 "故障" 0 "正常";
VAL_ 2566858223 VBUS_VCU7_PDU_HVIL_Err 1 "故障" 0 "正常";
VAL_ 2566858223 VBUS_VCU7_BATT_HVIL_Err 1 "故障" 0 "正常";
VAL_ 2566858223 VBUS_VCU7_FUELCELL_HVIL_Err 1 "故障" 0 "正常";
VAL_ 2566858223 VBUS_VCU7_ADCAC_BRAKE_EN_CMD 1 "Enable" 0 "Disable";
VAL_ 2566858223 VBUS_VCU7_IMCUA_420_ready 1 "使能打开" 0 "使能关闭";
VAL_ 2566858223 VBUS_VCU7_FAULT_IMCUO 1 "故障" 0 "正常";
VAL_ 2566857711 VBUS_VCU9_DrivngMileageDisplayFb 3 "CHTC工况里程" 2 "WLTC工况里程" 1 "CLTC工况里程" 0 "动态里程";
VAL_ 2566853871 VBUS_VCU12_ICS_Fault_Flg 3 "void" 2 "void" 1 "有故障" 0 "无故障";
VAL_ 2566853871 VBUS_VCU12_HVConnect_Sta 1 "高压连接" 0 "高压断开";
VAL_ 2566858735 VBUS_VCU8_HydFilling 1 "车辆正在加氢" 0 "未加氢";
VAL_ 2566858735 VBUS_VCU8_F_Hyd_LowSOC 1 "黄区范围（低于:20%）" 0 "正常";
VAL_ 2566858735 VBUS_VCU8_F_HydLeakage 1 "故障" 0 "无故障";
VAL_ 2566858735 VBUS_VCU8_St_FCVMode 1 "混动模式" 0 "纯电模式";
VAL_ 2566858735 VBUS_VCU8_F_FCV 4 "四级故障（红色图标）" 3 "三级故障（红色图标）" 2 "二级故障（黄色图标）" 1 "一级故障（黄色图标）" 0 "无故障";
VAL_ 2566858735 VBUS_VCU8_F_Bottle_Pressure_High 3 "NotAvailable" 2 "NotAvailable" 1 "故障" 0 "无故障";
VAL_ 2566858735 VBUS_VCU8_St_HydrLowFcoff 1 "氢压低燃料电池关机" 0 "无报警";
VAL_ 2566858735 VBUS_VCU8_St_EVModeLowSOC 1 "动力电池电量低，请尽快退出EV模式" 0 "正常";
VAL_ 2566858735 VBUS_VCU8_F_Hyd 3 "3级故障（仪表提示文字“氢系统故障”）" 2 "2级故障（仪表提示文字“氢系统故障”）" 1 "1级故障（仪表不显示）" 0 "正常";
VAL_ 2566866215 VBUS_VCU20_V2GSwtFb 1 "直流V2G开关功能开启" 0 "直流V2G开关功能关闭";
VAL_ 2566866215 VBUS_VCU20_PowerOutSts_220V 1 "车内取电中" 0 "车内取电未开启";
VAL_ 2566866215 VBUS_VCU20_PowerSwtFb_220V 1 "车内取电功能开启" 0 "车内取电功能关闭";
VAL_ 2566866215 VBUS_VCU20_AutoBatteryRechargeSwtFb 1 "智能补电功能开启" 0 "智能补电功能关闭";
VAL_ 2566866215 VBUS_VCU20_DiffLockStateRearAxle1 3 "SNA" 2 "Error" 1 "Differential lock engaged" 0 "Differential lock disengaged";
VAL_ 2566866215 VBUS_VCU20_DiffLockStateRearAxle2 3 "SNA" 2 "Error" 1 "Differential lock engaged" 0 "Differential lock disengaged";
VAL_ 2566866215 VBUS_VCU20_DiffLockSwtFb 1 "轮间差速锁功能开启" 0 "轮间差速锁功能关闭";
VAL_ 2566866215 VBUS_VCU20_SPSM_St 1 "超级节电功能开启" 0 "超级节电功能未开启";
VAL_ 2566866215 VBUS_VCU20_VehicleCreepSetFb 1 "无蠕行功能需求" 0 "有蠕行功能需求";
VAL_ 2566866215 VBUS_VCU20_GSMFltSts 1 "有故障" 0 "无故障";
VAL_ 2566866215 VBUS_VCU20_DragModelSwtFb 1 "拖车模式开启" 0 "拖车模式未开启";
VAL_ 2566866215 VBUS_VCU20_SPSM_SwtFb 1 "超级节电开启" 0 "超级节电关闭";
VAL_ 2566866215 VBUS_VCU20_Swt_EV_FCV 1 "EV模式开关开启" 0 "FCV模式开关开启";
VAL_ 2566866215 VBUS_VCU20_DriveAnti_theftSts 2 "认证通过" 1 "认证不通过" 0 "未开始认证，或认证中";
VAL_ 2566866215 VBUS_VCU20_StopChargingSwtFb 1 "充电停止" 0 "未接收充电停止请求";
VAL_ 2566866215 VBUS_VCU20_DrvMod_ECO 1 "建议切换经济模式" 0 "无提示";
VAL_ 2566866215 VBUS_VCU20_EMotor_OverSpeed 3 "sna" 2 "Error" 1 "Emotor Overspeed active" 0 "No Overspeed detected";
VAL_ 2566866983 VBUS_VCU21_ChargngByApntmntSwtFb 1 "预约直流充电功能开启" 0 "预约直流充电功能关闭";
VAL_ 2566866983 VBUS_VCU21_ChargngByApntmntReplicationSetFb 1 "单次" 0 "循环";
VAL_ 2566866983 VBUS_VCU21_ImmediatStartChargngFb 3 "void" 2 "void" 1 "已响应立即充电" 0 "未响应立即充电";
VAL_ 2566866983 VBUS_VCU21_ChargngByApntmntStartFb 3 "预约直流充电失败" 2 "预约直流充电中" 1 "预约直流充电等待" 0 "无预约直流充电";
VAL_ 2566866983 VBUS_VCU21_ChargngByApntmntHourEndFb 62 "表示设置为充满";
VAL_ 2566866983 VBUS_VCU21_ChargngByApntmntMinuteEndFb 62 "表示设置为充满";
VAL_ 2566866983 VBUS_VCU21_V2VSwtFb 1 "直流V2V功能开关开启" 0 "直流V2V功能开关关闭";
VAL_ 2566866983 VBUS_VCU21_DCV2LSwtFb 1 "直流V2L功能开关开启" 0 "直流V2L功能开关关闭";
VAL_ 2566866983 VBUS_VCU21_VCU_BattaryHeatingSts 3 "加热中止（故障或条件不满足）" 2 "动力电池加热完成(满足温度阈值)" 1 "动力电池加热中" 0 "动力电池未开启加热";
VAL_ 2566866983 VBUS_VCU21_ChargingKeepWarmSwtFb 1 "充电保温功能开启" 0 "充电保温功能关闭";
VAL_ 2566866983 VBUS_VCU21_ChargingKeepWarmSts 1 "充电保温状态" 0 "未在充电保温状态";
VAL_ 2566866983 VBUS_VCU21_StopDCDisChargingSwtFb 1 "放电停止" 0 "未接收放电停止请求";
VAL_ 2566868263 VBUS_VCU22_MaintModeSwtFb 1 "维修模式开启" 0 "维修模式关闭";
VAL_ 2566868263 VBUS_VCU22_VehEnginMod 5 "OTAMode" 4 "TransportMode(预留)" 3 "ExhibitionMode(预留)" 2 "LoVRepairMod" 1 "FactoryMode" 0 "NormalMode";
VAL_ 2566868263 VBUS_VCU22_MaintModeSt 3 "进入低压维修模式" 2 "维修模式开启失败" 1 "维修模式开启中" 0 "维修模式关闭";
VAL_ 2566870288 IntarderPilotLampState 3 "NotAvailable" 2 "FLASH(in case of error)" 1 "ON" 0 "OFF";
VAL_ 2566708224 ACCReadinessStatus 3 "NotAvailable" 2 "Error" 1 "On" 0 "Off";
VAL_ 2566708224 AEBSReadinessState 3 "Not Available/Not Supported" 2 "Condition exists that prevents system from responding to AEBS commands even though it is configured" 1 "On -- engine is configured to accept commands from an AEBS" 0 "Off -- engine is not configured to accept commands from an AEBS";
VAL_ 2566719232 EngAmberWarningLampCmd 3 "NotAvailable" 2 "Reserved" 1 "LampOn" 0 "LampOff";
VAL_ 2566719232 EngRedStopLampCmd 3 "NotAvailable" 2 "Reserved" 1 "LampOn" 0 "LampOff";
VAL_ 2566719232 OBDMalfunctionIndicatorLampCmd 3 "NotAvailable" 2 "Reserved" 1 "LampOn" 0 "LampOff";
VAL_ 2566719232 EngBrakeActiveLampCmd 3 "NotAvailable" 2 "Reserved" 1 "LampOn" 0 "LampOff";
VAL_ 2566719232 EngOilPressLowLampCmd 3 "NotAvailable" 2 "Reserved" 1 "LampOn" 0 "LampOff";
VAL_ 2566719232 EngCoolantTempHighLampCmd 3 "NotAvailable" 2 "Reserved" 1 "LampOn" 0 "LampOff";
VAL_ 2566719232 EngCoolantLevelLowLampCmd 3 "NotAvailable" 2 "Reserved" 1 "LampOn" 0 "LampOff";
VAL_ 2566719232 EngineAirFilterRestrictionLampCommand 3 "NotAvailable" 2 "Reserved" 1 "LampOn" 0 "LampOff";
VAL_ 2566853359 VBUS_VCU4_St_Gears 3 "保留" 2 "R" 1 "D" 0 "N";
VAL_ 2566853359 VBUS_VCU4_St_Ready 1 "ready" 0 "not ready";
VAL_ 2566853359 VBUS_VCU4_St_Vehicle 3 "致命故障（闪烁蜂鸣）" 2 "严重故障（红灯闪烁）" 1 "一般故障（红灯常亮）" 0 "正常;";
VAL_ 2566853359 VBUS_VCU4_St_Interlocking 1 "互锁" 0 "非互锁";
VAL_ 2566853359 VBUS_VCU4_St_ShiftGearBrkOn 1 "换挡未踩制动" 0 "换挡已踩制动";
VAL_ 2566853359 VBUS_VCU4_F_ShiftGears 1 "换挡不成功，挡位指示闪烁" 0 "正常，不闪烁";
VAL_ 2566853359 VBUS_VCU4_F_Motor 1 "故障" 0 "正常";
VAL_ 2566853359 VBUS_VCU4_F_MotorOverTemp 1 "故障" 0 "正常";
VAL_ 2566853359 VBUS_VCU4_St_DISCHARGE_STA 3 "void" 2 "void" 1 "正在放电" 0 "非放电状态";
VAL_ 2566853359 VBUS_VCU4_St_BrakeSta 1 "已踩制动踏板" 0 "未踩制动踏板";
VAL_ 2566853359 VBUS_VCU4_St_Thermal_runaway 1 "故障" 0 "正常";
VAL_ 2566853615 VBUS_VCU5_St_LowSOC 1 "SOC低报警（20%，红灯加蜂鸣）；" 0 "正常；";
VAL_ 2566853615 VBUS_VCU5_St_BatteryCHGHeating 1 "动力电池充电仅加热模式" 0 "非加热模式";
VAL_ 2566853615 VBUS_VCU5_F_Battery 1 "故障" 0 "正常";
VAL_ 2566853615 VBUS_VCU5_F_OverTemperature 1 "故障" 0 "正常";
VAL_ 2566853615 VBUS_VCU5_F_LVBattVoltageLow 1 "故障" 0 "正常";
VAL_ 2566853615 VBUS_VCU5_St_HVDisConnect 1 "断开" 0 "连接";
VAL_ 2566853615 VBUS_VCU5_F_Isolation 1 "故障" 0 "正常";
VAL_ 2566853615 VBUS_VCU5_St_ChargerIndicator 3 "充电完成（绿灯点亮）" 2 "充电故障（红灯点亮）；" 1 "正在充电（黄灯点亮）；" 0 "非充电状态（默认值，不点灯）；";
VAL_ 2566853615 VBUS_VCU5_St_ChargerLine 1 "连接中" 0 "未连接（默认值）";
VAL_ 2566853615 VBUS_VCU5_St_EnergyFlow 3 "故障模式" 2 "能量回收模式" 1 "行驶模式" 0 "停车模式";
VAL_ 2566853615 VBUS_VCU5_St_ChargeMode 3 "Reserve" 2 "慢充" 1 "快充" 0 "非充电；";
VAL_ 2566853615 VBUS_VCU5_St_PowerReduceOperation 1 "降功率" 0 "正常";
VAL_ 2566872103 PosnLiForgotWarn 1 "warning" 0 "not warning";
VAL_ 2566872103 N_gearIgnRmn 1 "warning" 0 "not warning";
VAL_ 2566872103 N_gearPwroffRmn 1 "warning" 0 "not warning";
VAL_ 2566872103 PsdBrkIgnRmn 1 "warning" 0 "not warning";
VAL_ 2566872103 PwrOnAlrm 1 "warning" 0 "not warning";
VAL_ 2566872103 PwrStsVld 1 "Valid" 0 "Invalid";
VAL_ 2566872103 LockAutoCloseWinSetSts 1 "ON" 0 "OFF";
VAL_ 2566872103 SpeedLimitSet_SleeperSts 1 "ON" 0 "OFF";
VAL_ 2566872103 SteerWheelHeatReq 7 "Res" 6 "Res" 5 "Res" 4 "Level3" 3 "Level2" 2 "Level1" 1 "OFF" 0 "No Req";
VAL_ 2566872103 DrSeatHeatReq 7 "Res" 6 "Res" 5 "Res" 4 "Level3" 3 "Level2" 2 "Level1" 1 "OFF" 0 "No Req";
VAL_ 2566893351 LowBeamFltWarn_VDCU 3 "预留" 2 "潜伏故障；" 1 "单点故障；" 0 "正常；";
VAL_ 2566893351 MainBrkLightFltWarn_VDCU 3 "预留" 2 "潜伏故障；" 1 "单点故障；" 0 "正常；";
VAL_ 2566893351 TrailerBrkLightFltWarn_VDCU 3 "预留" 2 "潜伏故障；" 1 "单点故障；" 0 "正常；";
VAL_ 2566893351 HighBeamFltWarn_VDCU 3 "预留" 2 "潜伏故障；" 1 "单点故障；" 0 "正常；";
VAL_ 2566893351 OvertakinglampWarn_VDCU 3 "预留" 2 "潜伏故障；" 1 "单点故障；" 0 "正常；";
VAL_ 2566893351 FrontOperatorWiperFltWarn_VDCU 3 "预留" 2 "潜伏故障；" 1 "单点故障；" 0 "正常；";
VAL_ 2566893351 WinCtrlFlt_Drvr_VDCU 3 "预留" 2 "潜伏故障；" 1 "单点故障；" 0 "正常；";
VAL_ 2566893351 WinCtrlFlt_Pass_VDCU 3 "预留" 2 "潜伏故障；" 1 "单点故障；" 0 "正常；";
VAL_ 2566893351 VDCU_ACFrontDefrostSysSts 3 "Reserved" 2 "PotentialFailures" 1 "Fault" 0 "Normal";
VAL_ 2566893351 LowPowerModeWarn_VDCU 3 "预留" 2 "潜伏故障；" 1 "单点故障；" 0 "正常；";
VAL_ 2566875943 VBUS_VCU24_N_AllowedTowing_Mode 7 "SNA" 6 "Error" 3 "Mode3 mech not neutral (Mode3_notMNeutral)" 2 "Mode2 eOP not operational (Mode2_eOP_nok)" 1 "Mode1 eOP operational (Mode1_eOP_ok)" 0 "Mode0 not relevant (Mode0_na)";
VAL_ 2566875943 VBUS_VCU24_N_Towing_Error 15 "SNA" 14 "Error" 4 "TowingTimeTooLong (TimeTooLong)" 2 "TowingDistanceTooLong (OdoTooLong)" 1 "Towing speed is too high (SpdTooHigh)" 0 "No error";
VAL_ 2566861351 LeftTurnLightReq 15 "Invalid" 6 "寻车灯语" 5 "RemoteUnlock(解锁灯语)" 4 "RemoteLock(闭锁灯语)" 3 "变道灯语（预留）" 1 "On Normal(正常)（转向和危报）；" 0 "No Operation/OFF";
VAL_ 2566861351 RightTurnLightReq 15 "Invalid" 6 "寻车灯语" 5 "RemoteUnlock(解锁灯语)" 4 "RemoteLock(闭锁灯语)" 3 "变道灯语（预留）" 1 "On Normal(正常)（转向和危报）；" 0 "No Operation/OFF";
VAL_ 2566861351 HzrdLightReq 1 "Hazard(危报灯激活)" 0 "No Hazard(危报灯未激活)";
VAL_ 2566861351 LowBeamReq 1 "ON" 0 "OFF";
VAL_ 2566861351 HighBeamReq 1 "ON" 0 "OFF";
VAL_ 2566861351 ReverseLampReq 1 "ON" 0 "OFF";
VAL_ 2566861351 MainBrkLightReq 2 "Lamp Flash" 1 "Lamp On" 0 "Lamp Off";
VAL_ 2566861351 TrailerBrkLightReq 2 "Lamp Flash" 1 "Lamp On" 0 "Lamp Off";
VAL_ 2566861351 PosnLigjtReq 1 "ON" 0 "OFF";
VAL_ 2566861351 BacklightAdjustReq 10 "输出50Hz（TBD）占空比30%~100%波形；" 9 "输出50Hz（TBD）占空比30%~100%波形；" 8 "输出50Hz（TBD）占空比30%~100%波形；" 7 "输出50Hz（TBD）占空比30%~100%波形；" 6 "输出50Hz（TBD）占空比30%~100%波形；" 5 "输出50Hz（TBD）占空比30%~100%波形；" 4 "输出50Hz（TBD）占空比30%~100%波形；" 3 "输出50Hz（TBD）占空比30%~100%波形；" 2 "输出50Hz（TBD）占空比20%波形；" 1 "输出50Hz（TBD）占空比10%波形；" 0 "Invalid(Not Request)";
VAL_ 2566861351 LeftDayTimeRunngLiReq 1 "ON" 0 "off";
VAL_ 2566861351 RightDayTimeRunngLiReq 1 "ON" 0 "off";
VAL_ 2566861351 RearFogLampReq 1 "ON" 0 "off";
VAL_ 2566861351 RearFogLampReplcmtReq 1 "ON" 0 "OFF";
VAL_ 2566861351 LanternLanguageReq 15 "NotAvailable" 14 "Reserve" 13 "Reserve" 12 "Reserve" 11 "Reserve" 10 "Reserve" 9 "Reserve" 8 "Reserve" 7 "Reserve" 6 "Type6" 5 "Type5" 4 "Type4" 3 "Type3" 2 "Type2" 1 "Type1" 0 "OFF";
VAL_ 2566861351 IVI_FrontFogLampLinkageSetFB 1 "联动" 0 "无联动";
VAL_ 2566861351 LampFollowMeHomeSetSts 3 "90s" 2 "60s" 1 "30s" 0 "OFF";
VAL_ 2566861351 LampAwayHomeSetSts 3 "90s" 2 "60s" 1 "30s" 0 "OFF";
VAL_ 2566861351 ExtrMirrHeatCtrl 2 "ExtrMirrHeatOn" 1 "ExtrMirrHeatOff" 0 "No Req";
VAL_ 2566861351 ExtrMirrDirAdjmtCtrl_L 4 "TurnRight" 3 "TurnLeft" 2 "TurnDown" 1 "TurnUp" 0 "No Cmd";
VAL_ 2566861351 ExtrMirrDirAdjmtCtrl_R 4 "TurnRight" 3 "TurnLeft" 2 "TurnDown" 1 "TurnUp" 0 "No Cmd";
VAL_ 2566861351 FrontFogLampReq_L 1 "ON" 0 "off";
VAL_ 2566861351 FrontFogLampReq_R 1 "ON" 0 "off";
VAL_ 2566861607 WinReq_L 3 "无效" 2 "Driver Window down" 1 "Driver Window up" 0 "Driver Window Not Moving";
VAL_ 2566861607 WinReq_R 3 "无效" 2 "Passenger Window down" 1 "Passenger Window up" 0 "Passenger Window Not Moving";
VAL_ 2566861607 WasherReq 3 "无效" 2 "Error" 1 "喷淋电机驱动请求" 0 "NOT REQUEST";
VAL_ 2566861607 WiperReq 7 "预留" 6 "预留" 5 "预留" 4 "预留" 3 "雨刮间歇驱动请求（500ms或2帧）" 2 "雨刮高速驱动请求" 1 "雨刮低速驱动请求" 0 "NOT REQUEST";
VAL_ 2566861607 OutIncrWinAntAlarm 1 "Warning" 0 "No warning";
VAL_ 2566861607 StartStopButtonLiReq 2 "Yellow" 1 "Green" 0 "不驱动";
VAL_ 2566861607 RelayReq_ACC 1 "ON" 0 "OFF";
VAL_ 2566861607 RelayReq_IG1 1 "ON" 0 "OFF";
VAL_ 2566861607 RelayReq_IG2 1 "ON" 0 "OFF";
VAL_ 2566861607 CrankReq 1 "Active" 0 "Inactive";
VAL_ 2566861607 RelaySts_ACC 1 "Active" 0 "Inactive";
VAL_ 2566861607 RelaySts_IG1 1 "Active" 0 "Inactive";
VAL_ 2566861607 RelaySts_IG2 1 "Active" 0 "Inactive";
VAL_ 2566861607 LowPowerMode 15 "Signal Invalid" 14 "Reserved" 13 "Reserved" 12 "Reserved" 11 "Reserved" 10 "Reserved" 9 "Reserved" 8 "Reserved" 7 "Reserved" 6 "Reserved" 5 "Reserved" 4 "Start" 3 "ON" 2 "Reserved" 1 "OFF" 0 "Initial";
VAL_ 2566861607 RmtLowPowerMode 1 "有效" 0 "无效";
VAL_ 2566861607 RainCloseWinSwt_Fb 3 "无效" 2 "Error" 1 "ON" 0 "OFF";
VAL_ 2566861607 RmtLocaloutreq_VDCU 3 "Reserved" 2 "Reserved" 1 "本地事件触发" 0 "NOT REQUEST";
VAL_ 2566861607 BluetoothKeyConnect 3 "Reserve" 2 "安全连接" 1 "物理连接" 0 "未连接";
VAL_ 2566861607 BluetoothKeyLocation 4 "out car（除PE区）" 3 "PE（副驾侧）" 2 "PE（主驾侧）" 1 "PS（车内）" 0 "Invalid";
VAL_ 2566861607 BluetoothKeyReq 15 "Signal Invalid" 14 "Reserved" 13 "Reserved" 12 "Reserved" 11 "Reserved" 10 "Reserved" 9 "Reserved" 8 "Reserved" 7 "Reserved" 6 "Lamp Inspection" 5 "Searching Car" 4 "Auto Window Down" 3 "Auto Window Up" 2 "Lock" 1 "Unlock" 0 "Initial";
VAL_ 2566861607 BluetoothPhoneConnect 3 "Reserve" 2 "Reserve" 1 "已连接" 0 "未连接";
VAL_ 2566861607 PrimaryAntennaSleepSts 3 "Connection3:TBD" 2 "Connection2:Connection mode；" 1 "sleep:Sleep mode；" 0 "Connection1:position mode；";
VAL_ 2566872611 RLS_RQ_WiperSPD 3 "Not used" 2 "High Speed" 1 "Low Speed" 0 "No wiping";
VAL_ 2566872611 RLS_RQ_LowBeam 1 "RQ on Low Beam" 0 "No RQ on Low Beam";
VAL_ 2566872611 RLS_RQ_PositionLamp 1 "RQ on Position Lamp" 0 "No RQ on Position Lamp";
VAL_ 2566872611 RLS_Fault_Rain 1 "Status Fault" 0 "Normal Status";
VAL_ 2566872611 RLS_Fault_Light 1 "Status Fault" 0 "Normal Status";
VAL_ 2566872611 RLS_REP_Error 1 "Error" 0 "No error";
VAL_ 2566872611 RLS_VOLT_Error 3 "Not used" 2 "VOLT_High" 1 "VOLT_Low" 0 "No error";
VAL_ 2566872611 RLS_RainCloseWin_Str 1 "关窗" 0 "不关窗";
VAL_ 2566872611 RLS_WiperSPD_FuncErr 3 "预留。" 2 "潜伏故障；" 1 "单点故障（含开关采集类故障、逻辑处理类故障、通讯类故障、驱动类故障等直接影响了功能表现行为的故障）；" 0 "正常；";
VAL_ 2566872611 RLS_RQ_LowBeam_FuncErr 3 "预留。" 2 "潜伏故障；" 1 "单点故障（含开关采集类故障、逻辑处理类故障、通讯类故障、驱动类故障等直接影响了功能表现行为的故障）；" 0 "正常；";
VAL_ 2566873629 SGM_S_Unlock_Swt 3 "Error" 2 "Reserved" 1 "press" 0 "Not press";
VAL_ 2566873629 SGM_S_Lock_Swt 3 "Error" 2 "Reserved" 1 "press" 0 "Not press";
VAL_ 2566873629 SGM_S_WLM_FL_Swt 7 "预留" 6 "预留" 5 "故障" 4 "Driver side driver window auto down" 3 "Driver side driver window auto up" 2 "Driver side driver window manual down" 1 "Driver side driver window manual up" 0 "No request";
VAL_ 2566873629 SGM_S_WLM_FR_Swt 7 "预留" 6 "预留" 5 "故障" 4 "Driver side driver window auto down" 3 "Driver side driver window auto up" 2 "Driver side driver window manual down" 1 "Driver side driver window manual up" 0 "No request";
VAL_ 2566873629 SGM_S_VolumePlus_Swt 3 "Error" 2 "longpress" 1 "shortpress" 0 "Not press";
VAL_ 2566873629 SGM_S_VolumeMinus_Swt 3 "Error" 2 "longpress" 1 "shortpress" 0 "Not press";
VAL_ 2566873629 SGM_S_ACOnOrOff_Swt 3 "Error" 2 "Reserved" 1 "press" 0 "Not press";
VAL_ 2566873629 SGM_S_BlowerLvlPlus_Swt 3 "Error" 2 "Reserved" 1 "press" 0 "Not press";
VAL_ 2566873629 SGM_S_BlowerLvlMinus_Swt 3 "Error" 2 "Reserved" 1 "press" 0 "Not press";
VAL_ 2566873629 SGM_S_ACTempPlus_Swt 3 "Error" 2 "Reserved" 1 "press" 0 "Not press";
VAL_ 2566873629 SGM_S_ACTempMinus_Swt 3 "Error" 2 "Reserved" 1 "press" 0 "Not press";
VAL_ 2566873629 SGM_S_ACTimingRun_Swt 3 "Error" 2 "Reserved" 1 "press" 0 "Not press";
VAL_ 2566873629 SGM_S_CMSStart_Swt 3 "Error" 2 "Reserved" 1 "press" 0 "Not press";
VAL_ 2566873629 SGM_S_F_LINError 1 "Error" 0 "Normal";
VAL_ 2365537816 SWS_Mode_Swt 3 "Error" 2 "Reserved" 1 "press" 0 "Not press";
VAL_ 2365537816 SWS_ReturnOrConfirm_Swt 3 "Error" 2 "Reserved" 1 "press" 0 "Not press";
VAL_ 2365537816 SWS_DirectionUp_Swt 3 "Error" 2 "Reserved" 1 "press" 0 "Not press";
VAL_ 2365537816 SWS_DirectionDown_Swt 3 "Error" 2 "Reserved" 1 "press" 0 "Not press";
VAL_ 2365537816 SWS_DirectionLeft_Swt 3 "Error" 2 "Reserved" 1 "press" 0 "Not press";
VAL_ 2365537816 SWS_DirectionRight_Swt 3 "Error" 2 "Reserved" 1 "press" 0 "Not press";
VAL_ 2365537816 SWS_VROrHangUp_Swt 3 "Error" 2 "Reserved" 1 "press" 0 "Not press";
VAL_ 2365537816 SWS_MuteOrHangDown_Swt 3 "Error" 2 "Reserved" 1 "press" 0 "Not press";
VAL_ 2365537816 SWS_Userde_Swt 3 "Error" 2 "Reserved" 1 "press" 0 "Not press";
VAL_ 2365537816 SWS_ADAS_Swt 3 "Error" 2 "Reserved" 1 "press" 0 "Not press";
VAL_ 2365537816 SWS_SpeedUp_Set 3 "Error" 2 "Error" 1 "press" 0 "Not press";
VAL_ 2365537816 SWS_SpeedDown_Set 3 "Error" 2 "Error" 1 "press" 0 "Not press";
VAL_ 2365537816 SWS_TimeGapInc_Set 3 "Error" 2 "Reserved" 1 "press" 0 "Not press";
VAL_ 2365537816 SWS_TimeGapDec_Set 3 "Error" 2 "Reserved" 1 "press" 0 "Not press";
VAL_ 2365537816 SWS_LKA_Swt 3 "Error" 2 "Reserved" 1 "press" 0 "Not press";
VAL_ 2365537816 SWS_Heating_Swt 3 "Error" 2 "Reserved" 1 "press" 0 "Not press";
VAL_ 2566873374 SGM_IP_HornType_Swt 3 "Error" 2 "Reserved" 1 "press" 0 "Not press";
VAL_ 2566873374 SGM_IP_RearLight_Swt 3 "Error" 2 "Reserved" 1 "press" 0 "Not press";
VAL_ 2566873374 SGM_IP_ACOff_Swt 3 "Error" 2 "Reserved" 1 "press" 0 "Not press";
VAL_ 2566873374 SGM_IP_BlowerLvlPlus_Swt 3 "Error" 2 "Reserved" 1 "press" 0 "Not press";
VAL_ 2566873374 SGM_IP_BlowerLvlMinus_Swt 3 "Error" 2 "Reserved" 1 "press" 0 "Not press";
VAL_ 2566873374 SGM_IP_ACTempPlus_Swt 3 "Error" 2 "Reserved" 1 "press" 0 "Not press";
VAL_ 2566873374 SGM_IP_ACTempMinus_Swt 3 "Error" 2 "Reserved" 1 "press" 0 "Not press";
VAL_ 2566873374 SGM_IP_ACFrontDefrost_Swt 3 "Error" 2 "Reserved" 1 "press" 0 "Not press";
VAL_ 2566873374 SGM_IP_F_LINError 1 "Error" 0 "Normal";
VAL_ 2566892165 WCM1_key_status 3 "Reserved" 2 "OFF" 1 "ON" 0 "Initial Value";
VAL_ 2566892165 WCM1_charge_status 7 "Reserved" 6 "Reserved" 5 "Reserved" 4 "WPC Fault" 3 "Charging Completed" 2 "Charging" 1 "Standby" 0 "Initial Value";
VAL_ 2566892165 WCM1_fault_status 15 "Reserved" 14 "Reserved" 13 "Reserved" 12 "Reserved" 11 "Reserved" 10 "Reserved" 9 "Reserved" 8 "Reserved" 7 "Reserved" 6 "Reserved" 5 "System Fault" 4 "Over Temperature Protection(OTP)" 3 "Low Voltage Protection(LVP)" 2 "Over Voltage Protection(OVP)" 1 "Foreign Object Detection(FOD)" 0 "No Fault/WPC OFF";
VAL_ 2566892165 WCM1_phone_reminder 1 "Remind forgotten phone" 0 "No need to remind";
VAL_ 2566900371 LOG_LogoLightSet_Sts 3 "Res" 2 "OFF" 1 "ON" 0 "Initial";
VAL_ 2566872532 LCM_L_St_RunningLight 3 "NotAvailable" 2 "Error" 1 "ON" 0 "OFF";
VAL_ 2566872532 LCM_L_St_LeftTurnLight 3 "NotAvailable" 2 "Error" 1 "ON" 0 "OFF";
VAL_ 2566872532 LCM_L_St_TractorMarkerLight 3 "NotAvailable" 2 "Error" 1 "ON" 0 "OFF";
VAL_ 2566872532 LCM_L_St_LampFlicker 15 "NotAvailable" 14 "Reserve" 13 "Reserve" 12 "Reserve" 11 "Reserve" 10 "Reserve" 9 "Reserve" 8 "Reserve" 7 "Reserve" 6 "Type6" 5 "Type5" 4 "Type4" 3 "Type3" 2 "Type2" 1 "Type1" 0 "OFF";
VAL_ 2566872532 LCM_L_F_OverVoltage 1 "Error" 0 "Normal";
VAL_ 2566872532 LCM_L_F_UnderVoltage 1 "Error" 0 "Normal";
VAL_ 2566872532 LCM_L_F_RunningLight 3 "Underloading" 2 "Breaking" 1 "Short out" 0 "Normal";
VAL_ 2566872532 LCM_L_F_LeftTurnLight 3 "Underloading" 2 "Breaking" 1 "Short out" 0 "Normal";
VAL_ 2566872532 LCM_L_F_TractorMarkerLight 3 "Underloading" 2 "Breaking" 1 "Short out" 0 "Normal";
VAL_ 2566872789 LCM_R_St_RunningLight 3 "NotAvailable" 2 "Error" 1 "ON" 0 "OFF";
VAL_ 2566872789 LCM_R_St_RightTurnLight 3 "NotAvailable" 2 "Error" 1 "ON" 0 "OFF";
VAL_ 2566872789 LCM_R_St_TractorMarkerLight 3 "NotAvailable" 2 "Error" 1 "ON" 0 "OFF";
VAL_ 2566872789 LCM_R_St_LampFlicker 15 "NotAvailable" 14 "Reserve" 13 "Reserve" 12 "Reserve" 11 "Reserve" 10 "Reserve" 9 "Reserve" 8 "Reserve" 7 "Reserve" 6 "Type6" 5 "Type5" 4 "Type4" 3 "Type3" 2 "Type2" 1 "Type1" 0 "OFF";
VAL_ 2566872789 LCM_R_F_OverVoltage 1 "Error" 0 "Normal";
VAL_ 2566872789 LCM_R_F_UnderVoltage 1 "Error" 0 "Normal";
VAL_ 2566872789 LCM_R_F_RunningLight 3 "Underloading" 2 "Breaking" 1 "Short out" 0 "Normal";
VAL_ 2566872789 LCM_R_F_LeftTurnLight 3 "Underloading" 2 "Breaking" 1 "Short out" 0 "Normal";
VAL_ 2566872789 LCM_R_F_TractorMarkerLight 3 "Underloading" 2 "Breaking" 1 "Short out" 0 "Normal";
VAL_ 2566867415 EPU_LeftStepStatus 7 "NotAvaible" 6 "Fault" 5 "Reserved" 4 "Reserved" 3 "伸出到位状态" 2 "正在收回" 1 "正在伸出" 0 "收回到位状态";
VAL_ 2566867672 EPU_RightStepStatus 7 "NotAvaible" 6 "Fault" 5 "Reserved" 4 "Reserved" 3 "伸出到位状态" 2 "正在收回" 1 "正在伸出" 0 "收回到位状态";
VAL_ 2365536412 ControlMode 7 "Reserved" 6 "Reserved" 5 "Reserved" 4 "Reserved" 3 "Reserved" 2 "Auto2(24V_EHPS)" 1 "Auto1(12V_EHPS)" 0 "Manual";
VAL_ 2365536412 Accelerator_Torque_enable 1 "TorqueControl" 0 "AcceleratorControl";
VAL_ 2365536412 GearControl 15 "Reserved" 14 "Reserved" 13 "Reserved" 12 "Reserved" 11 "Reserved" 10 "Reserved" 9 "Reserved" 8 "Reserved" 7 "Reserved" 6 "Reserved" 5 "M档" 4 "-档" 3 "+档" 2 "R档" 1 "D档" 0 "N档";
VAL_ 2365536412 SetFogSt 3 "NotAvailable" 2 "frontandrearfoglampon" 1 "frontfoglampon" 0 "Off";
VAL_ 2365536412 SetTurnRightST 3 "NotAvailable" 2 "NotAvailable" 1 "On" 0 "Off";
VAL_ 2365536412 SetTurnLeftST 3 "NotAvailable" 2 "NotAvailable" 1 "On" 0 "Off";
VAL_ 2365536412 SetLowBeamSt 3 "NotAvailable" 2 "NotAvailable" 1 "On" 0 "Off";
VAL_ 2365536412 SetHighBeamSt 3 "NotAvailable" 2 "NotAvailable" 1 "On" 0 "Off";
VAL_ 2365536412 SetWiperSt 3 "High" 2 "Low" 1 "INT" 0 "Off";
VAL_ 2365536412 SetHornSt 3 "NotAvailable" 2 "NotAvailable（气喇叭）" 1 "On（电喇叭）" 0 "Off";
VAL_ 2365537692 SWVibrationRequest 7 "reserved" 6 "reserved" 5 "reserved" 4 "alwayson" 3 "0.25son0.25soffasaperiod" 2 "0.5son0.5soffasaperiod" 1 "1son1soffasaperiod" 0 "norequest";
VAL_ 2365537692 SetACFrontDefrostSt 3 "NotAvailable" 2 "NotAvailable" 1 "On" 0 "Off";
VAL_ 2365537692 SetWasherSt 3 "NotAvailable" 2 "NotAvailable" 1 "On" 0 "Off";
VAL_ 2365537692 EPModeDemand 3 "Notavailable" 2 "error" 1 "offroad(P)" 0 "normaloperation(E)";
VAL_ 2365537692 LidarWashSwitch 3 "Notavailable" 2 "blowon" 1 "Washon" 0 "off";
VAL_ 2365537692 SeatbeltTightenRequest 3 "NotAvailable" 2 "NotAvailable" 1 "tighten" 0 "norequest";
VAL_ 2365537692 SetHazardSt 3 "NotAvailable" 2 "NotAvailable" 1 "On" 0 "Off";
VAL_ 2365537692 SetDoorUnlockingSt 3 "NotAvailable" 2 "NotAvailable" 1 "Unlock" 0 "NoRequest";
VAL_ 2365537692 SetWindowSt 3 "NotAvailable" 2 "NotAvailable" 1 "OpenWindow" 0 "NoRequest";
VAL_ 2348810400 EngOverrideCtrlMode_C0000A0 3 "Spd_TrqLmtCtrlLmtSpdAnd_OrTrqBs" 2 "TrqCtrlCntrlTrqTInclddDsrdTrqVl" 1 "SpdCtrlGvrnSpdTInclddDsrdSpdVle" 0 "OvrrdDsbldDsblAnyExstngCtrlCmdd";
VAL_ 2348810400 EngRqedSpeedCtrlConditions_C0000A0 3 "StbltyOptmzdFrDrvlnEnggdAnd_OrI" 2 "ThsCtrlCndtnHsBnOptmzdTMnmzRpmO" 1 "StbltyOptmzdFrDrvlnDsnggdAndNnl" 0 "ThsSpdGvrnrGnSlctnIsAdjstdTPrvd";
VAL_ 2348810400 OverrideCtrlModePriority_TSC1 3 "LowPriority" 2 "MdmPrrtyUsdFrPwrtrnCtrlOprtnsWh" 1 "HighPriority" 0 "HghstPrrtyUsdFrSttnsThtRqrImmdt";
VAL_ 2348810400 TransmissionRate_C0000A0 7 "UseStandardRate10ms" 6 "20ms" 5 "50ms" 4 "100ms" 3 "250ms" 2 "500ms" 1 "750ms" 0 "1000ms";
VAL_ 2348810400 ControlPurpose_C0000A0 31 "TemporaryPowerTrainCotrol" 30 "ReservedForSAEAssigment" 29 "ReservedForSAEAssigment" 28 "ReservedForSAEAssigment" 27 "ReservedForSAEAssigment" 26 "ReservedForSAEAssigment" 25 "ReservedForSAEAssigment" 24 "ReservedForSAEAssigment" 23 "ReservedForSAEAssigment" 22 "ReservedForSAEAssigment" 21 "ReservedForSAEAssigment" 20 "ReservedForSAEAssigment" 19 "ReservedForSAEAssigment" 18 "ReservedForSAEAssigment" 17 "ReservedForSAEAssigment" 16 "ReservedForSAEAssigment" 15 "ReservedForSAEAssigment" 14 "ReservedForSAEAssigment" 13 "ReservedForSAEAssigment" 12 "ReservedForSAEAssigment" 11 "ReservedForSAEAssigment" 10 "ReservedForSAEAssigment" 9 "ReservedForSAEAssigment" 8 "ReservedForSAEAssigment" 7 "ReservedForSAEAssigment" 6 "ReservedForSAEAssigment" 5 "TemporaryPowerTrainControl" 4 "EngineProtection" 3 "RoadSpeedGovernor" 2 "PTOGovernor" 1 "CruiseControl" 0 "AcceleratorPedal";
VAL_ 2348810400 EngineRequestedTorqueHiRes_C0000A0 15 "NotAvailable" 14 "NotAvailable" 13 "NotAvailable" 12 "NotAvailable" 11 "NotAvailable" 10 "NotAvailable" 9 "NotAvailable" 8 "NotAvailable" 7 "+0.825%" 6 "+0.750%" 5 "+0.625%" 4 "+0.500%" 3 "+0.375%" 2 "+0.250%" 1 "+0.125%" 0 "+0.000%";
VAL_ 2348814492 EngOverrideCtrlMode_C00009C 3 "Spd_TrqLmtCtrlLmtSpdAnd_OrTrqBs" 2 "TrqCtrlCntrlTrqTInclddDsrdTrqVl" 1 "SpdCtrlGvrnSpdTInclddDsrdSpdVle" 0 "OvrrdDsbldDsblAnyExstngCtrlCmdd";
VAL_ 2348814492 EngRqedSpeedCtrlConditions_C00009C 3 "StbltyOptmzdFrDrvlnEnggdAnd_OrI" 2 "ThsCtrlCndtnHsBnOptmzdTMnmzRpmO" 1 "StbltyOptmzdFrDrvlnDsnggdAndNnl" 0 "ThsSpdGvrnrGnSlctnIsAdjstdTPrvd";
VAL_ 2348814492 OverrideCtrlModePriority_C00009C 3 "LowPriority" 2 "MdmPrrtyUsdFrPwrtrnCtrlOprtnsWh" 1 "HighPriority" 0 "HghstPrrtyUsdFrSttnsThtRqrImmdt";
VAL_ 2348814492 TransmissionRate_C00009C 7 "UseStandardRate10ms" 6 "20ms" 5 "50ms" 4 "100ms" 3 "250ms" 2 "500ms" 1 "750ms" 0 "1000ms";
VAL_ 2348814492 ControlPurpose_C00009C 31 "TemporaryPowerTrainCotrol" 30 "ReservedForSAEAssigment" 29 "ReservedForSAEAssigment" 28 "ReservedForSAEAssigment" 27 "ReservedForSAEAssigment" 26 "ReservedForSAEAssigment" 25 "ReservedForSAEAssigment" 24 "ReservedForSAEAssigment" 23 "ReservedForSAEAssigment" 22 "ReservedForSAEAssigment" 21 "ReservedForSAEAssigment" 20 "ReservedForSAEAssigment" 19 "ReservedForSAEAssigment" 18 "ReservedForSAEAssigment" 17 "ReservedForSAEAssigment" 16 "ReservedForSAEAssigment" 15 "ReservedForSAEAssigment" 14 "ReservedForSAEAssigment" 13 "ReservedForSAEAssigment" 12 "ReservedForSAEAssigment" 11 "ReservedForSAEAssigment" 10 "ReservedForSAEAssigment" 9 "ReservedForSAEAssigment" 8 "ReservedForSAEAssigment" 7 "ReservedForSAEAssigment" 6 "ReservedForSAEAssigment" 5 "TemporaryPowerTrainControl" 4 "EngineProtection" 3 "RoadSpeedGovernor" 2 "PTOGovernor" 1 "CruiseControl" 0 "AcceleratorPedal";
VAL_ 2348814492 EngineRequestedTorqueHiRes_C00009C 15 "NotAvailable" 14 "NotAvailable" 13 "NotAvailable" 12 "NotAvailable" 11 "NotAvailable" 10 "NotAvailable" 9 "NotAvailable" 8 "NotAvailable" 7 "+0.825%" 6 "+0.750%" 5 "+0.625%" 4 "+0.500%" 3 "+0.375%" 2 "+0.250%" 1 "+0.125%" 0 "+0.000%";
